[part 5 of 10: package /E40_Platform_System_SystemPackage/Components]
AUTOSAR XML (schema 4-2-1)
package /E40_Platform_System_SystemPackage/Components  (continued)
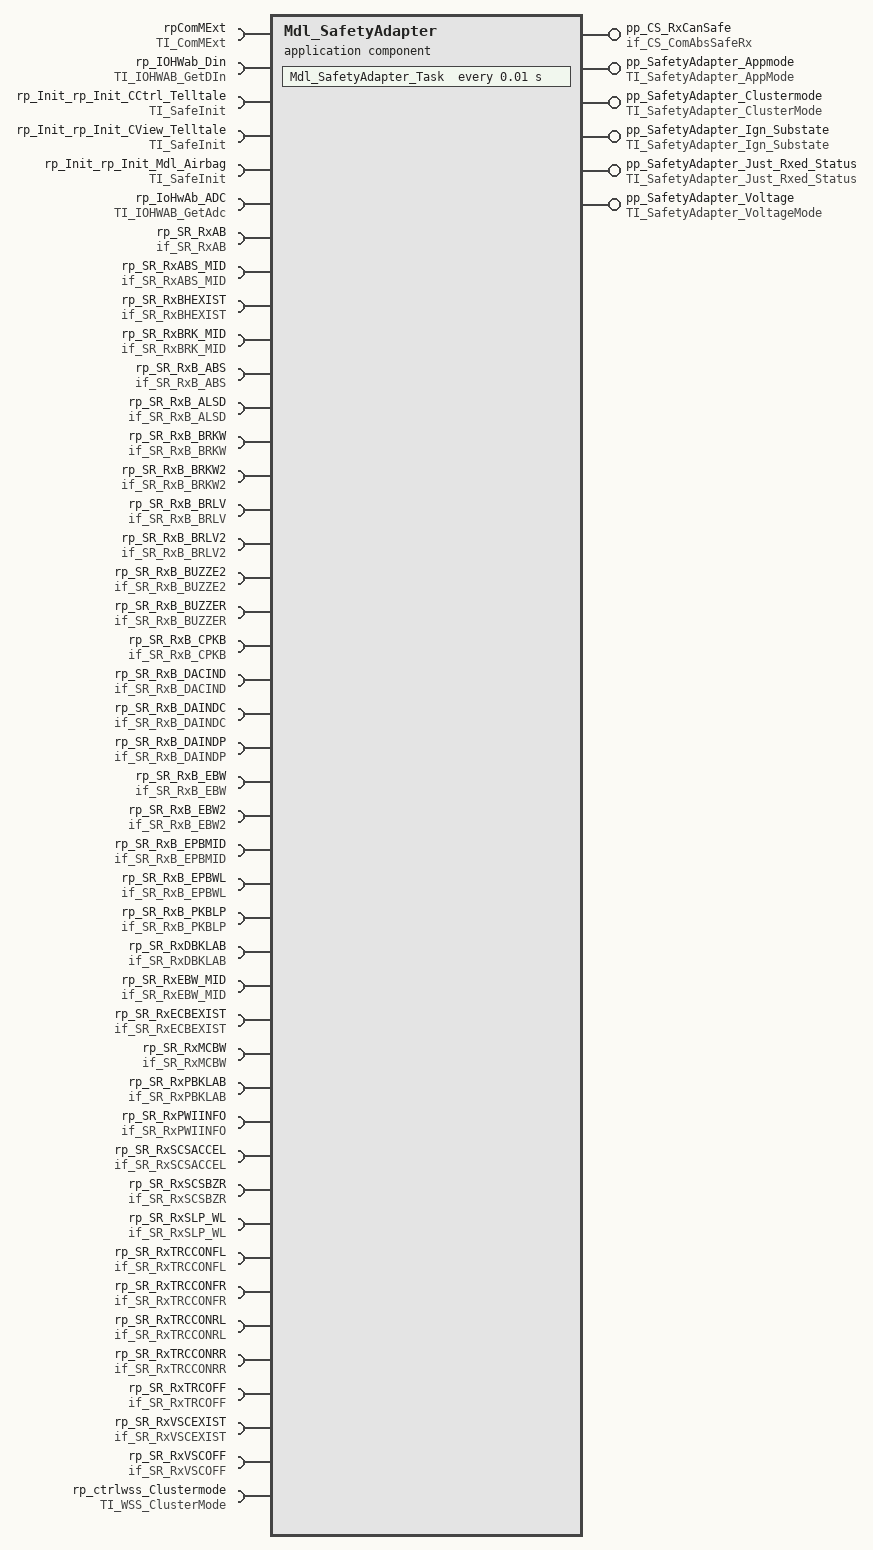
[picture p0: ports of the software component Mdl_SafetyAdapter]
  application sw component type Mdl_SafetyAdapter
    6 x provide port:
      pp_CS_RxCanSafe: provided-interface=if_CS_ComAbsSafeRx
        provided-com-specs:
          operation=Mdl_SafetyAdapter_ReloadMissingTimer, queue-length=1
          operation=RxCanVarInit, queue-length=1
          operation=RxCan_GetSafeSignalValue, queue-length=1
          operation=if_CS_ComAbsSafeRx/RxCan_SetSignalInitValue, queue-length=1
          operation=if_CS_ComAbsSafeRx/RxCan_SignalInvalidProcessingControl, queue-length=1
          operation=if_CS_ComAbsSafeRx/RxCan_SignalMissingProcessingControl, queue-length=1
          operation=if_CS_ComAbsSafeRx/RxCan_SignalNRProcessingControl, queue-length=1
      pp_SafetyAdapter_Appmode: nonqueued-sender-com-spec{data-element=SafetyAdapter_AppMode, init-value=constant-reference=Mdl_SafetyAdapterSafetyAdapter_AppModeValue0}, provided-interface=TI_SafetyAdapter_AppMode
      pp_SafetyAdapter_Clustermode: nonqueued-sender-com-spec{data-element=SafetyAdapter_CurrentClusterMode, init-value=constant-reference=Mdl_SafetyAdapterSafetyAdapter_CurrentClusterModeValue0}, provided-interface=TI_SafetyAdapter_ClusterMode
      pp_SafetyAdapter_Ign_Substate: nonqueued-sender-com-spec{data-element=SafetyAdapter_Ign_Substate, init-value=constant-reference=Mdl_SafetyAdapterSafetyAdapter_Ign_SubstateValue0}, provided-interface=TI_SafetyAdapter_Ign_Substate
      pp_SafetyAdapter_Just_Rxed_Status: provided-interface=TI_SafetyAdapter_Just_Rxed_Status
        provided-com-specs:
          operation=TI_SafetyAdapter_Just_Rxed_Status/RxCan_SignalClearJustRcvdStatus, queue-length=1
          operation=TI_SafetyAdapter_Just_Rxed_Status/RxCan_SignalGetJustRcvdStatus, queue-length=1
      pp_SafetyAdapter_Voltage: provided-interface=TI_SafetyAdapter_VoltageMode
        provided-com-specs:
          data-element=SafetyAdapter_HVSD1, init-value=constant-reference=Mdl_SafetyAdapterSafetyAdapter_HVSD1Value0
          data-element=SafetyAdapter_LVSD1, init-value=constant-reference=Mdl_SafetyAdapterSafetyAdapter_LVSD1Value0
    44 x require port:
      rpComMExt: required-interface=TI_ComMExt
      rp_IOHWab_Din: required-interface=TI_IOHWAB_GetDIn
      rp_Init_rp_Init_CCtrl_Telltale: required-interface=TI_SafeInit
      rp_Init_rp_Init_CView_Telltale: required-interface=TI_SafeInit
      rp_Init_rp_Init_Mdl_Airbag: required-interface=TI_SafeInit
      rp_IoHwAb_ADC: required-interface=TI_IOHWAB_GetAdc
      rp_SR_RxAB: nonqueued-receiver-com-spec{data-element=AB, init-value=constant-reference=Mdl_SafetyAdapterABValue0}, required-interface=if_SR_RxAB
      rp_SR_RxABS_MID: nonqueued-receiver-com-spec{data-element=ABS_MID, init-value=constant-reference=Mdl_SafetyAdapterABS_MIDValue0}, required-interface=if_SR_RxABS_MID
      rp_SR_RxBHEXIST: nonqueued-receiver-com-spec{data-element=BHEXIST, init-value=constant-reference=Mdl_SafetyAdapterBHEXISTValue0}, required-interface=if_SR_RxBHEXIST
      rp_SR_RxBRK_MID: nonqueued-receiver-com-spec{data-element=BRK_MID, init-value=constant-reference=Mdl_SafetyAdapterBRK_MIDValue0}, required-interface=if_SR_RxBRK_MID
      rp_SR_RxB_ABS: nonqueued-receiver-com-spec{data-element=B_ABS, init-value=constant-reference=Mdl_SafetyAdapterB_ABSValue0}, required-interface=if_SR_RxB_ABS
      rp_SR_RxB_ALSD: nonqueued-receiver-com-spec{data-element=B_ALSD, init-value=constant-reference=Mdl_SafetyAdapterB_ALSDValue0}, required-interface=if_SR_RxB_ALSD
      rp_SR_RxB_BRKW: nonqueued-receiver-com-spec{data-element=B_BRKW, init-value=constant-reference=Mdl_SafetyAdapterB_BRKWValue0}, required-interface=if_SR_RxB_BRKW
      rp_SR_RxB_BRKW2: nonqueued-receiver-com-spec{data-element=B_BRKW2, init-value=constant-reference=Mdl_SafetyAdapterB_BRKW2Value0}, required-interface=if_SR_RxB_BRKW2
      rp_SR_RxB_BRLV: nonqueued-receiver-com-spec{data-element=B_BRLV, init-value=constant-reference=Mdl_SafetyAdapterB_BRLVValue0}, required-interface=if_SR_RxB_BRLV
      rp_SR_RxB_BRLV2: nonqueued-receiver-com-spec{data-element=B_BRLV2, init-value=constant-reference=Mdl_SafetyAdapterB_BRLV2Value0}, required-interface=if_SR_RxB_BRLV2
      rp_SR_RxB_BUZZE2: nonqueued-receiver-com-spec{data-element=B_BUZZE2, init-value=constant-reference=Mdl_SafetyAdapterB_BUZZE2Value0}, required-interface=if_SR_RxB_BUZZE2
      rp_SR_RxB_BUZZER: nonqueued-receiver-com-spec{data-element=B_BUZZER, init-value=constant-reference=Mdl_SafetyAdapterB_BUZZERValue0}, required-interface=if_SR_RxB_BUZZER
      rp_SR_RxB_CPKB: nonqueued-receiver-com-spec{data-element=B_CPKB, init-value=constant-reference=Mdl_SafetyAdapterB_CPKBValue0}, required-interface=if_SR_RxB_CPKB
      rp_SR_RxB_DACIND: nonqueued-receiver-com-spec{data-element=B_DACIND, init-value=constant-reference=Mdl_SafetyAdapterB_DACINDValue0}, required-interface=if_SR_RxB_DACIND
      rp_SR_RxB_DAINDC: nonqueued-receiver-com-spec{data-element=B_DAINDC, init-value=constant-reference=Mdl_SafetyAdapterB_DAINDCValue0}, required-interface=if_SR_RxB_DAINDC
      rp_SR_RxB_DAINDP: nonqueued-receiver-com-spec{data-element=B_DAINDP, init-value=constant-reference=Mdl_SafetyAdapterB_DAINDPValue0}, required-interface=if_SR_RxB_DAINDP
      rp_SR_RxB_EBW: nonqueued-receiver-com-spec{data-element=B_EBW, init-value=constant-reference=Mdl_SafetyAdapterB_EBWValue0}, required-interface=if_SR_RxB_EBW
      rp_SR_RxB_EBW2: nonqueued-receiver-com-spec{data-element=B_EBW2, init-value=constant-reference=Mdl_SafetyAdapterB_EBW2Value0}, required-interface=if_SR_RxB_EBW2
      rp_SR_RxB_EPBMID: nonqueued-receiver-com-spec{data-element=B_EPBMID, init-value=constant-reference=Mdl_SafetyAdapterB_EPBMIDValue0}, required-interface=if_SR_RxB_EPBMID
      rp_SR_RxB_EPBWL: nonqueued-receiver-com-spec{data-element=B_EPBWL, init-value=constant-reference=Mdl_SafetyAdapterB_EPBWLValue0}, required-interface=if_SR_RxB_EPBWL
      rp_SR_RxB_PKBLP: nonqueued-receiver-com-spec{data-element=B_PKBLP, init-value=constant-reference=Mdl_SafetyAdapterB_PKBLPValue0}, required-interface=if_SR_RxB_PKBLP
      rp_SR_RxDBKLAB: nonqueued-receiver-com-spec{data-element=DBKLAB, init-value=constant-reference=Mdl_SafetyAdapterDBKLABValue0}, required-interface=if_SR_RxDBKLAB
      rp_SR_RxEBW_MID: nonqueued-receiver-com-spec{data-element=EBW_MID, init-value=constant-reference=Mdl_SafetyAdapterEBW_MIDValue0}, required-interface=if_SR_RxEBW_MID
      rp_SR_RxECBEXIST: nonqueued-receiver-com-spec{data-element=ECBEXIST, init-value=constant-reference=Mdl_SafetyAdapterECBEXISTValue0}, required-interface=if_SR_RxECBEXIST
      rp_SR_RxMCBW: nonqueued-receiver-com-spec{data-element=MCBW, init-value=constant-reference=Mdl_SafetyAdapterMCBWValue0}, required-interface=if_SR_RxMCBW
      rp_SR_RxPBKLAB: nonqueued-receiver-com-spec{data-element=PBKLAB, init-value=constant-reference=Mdl_SafetyAdapterPBKLABValue0}, required-interface=if_SR_RxPBKLAB
      rp_SR_RxPWIINFO: nonqueued-receiver-com-spec{data-element=PWIINFO, init-value=constant-reference=Mdl_SafetyAdapterPWIINFOValue0}, required-interface=if_SR_RxPWIINFO
      rp_SR_RxSCSACCEL: nonqueued-receiver-com-spec{data-element=SCSACCEL, init-value=constant-reference=Mdl_SafetyAdapterSCSACCELValue0}, required-interface=if_SR_RxSCSACCEL
      rp_SR_RxSCSBZR: nonqueued-receiver-com-spec{data-element=SCSBZR, init-value=constant-reference=Mdl_SafetyAdapterSCSBZRValue0}, required-interface=if_SR_RxSCSBZR
      rp_SR_RxSLP_WL: nonqueued-receiver-com-spec{data-element=SLP_WL, init-value=constant-reference=Mdl_SafetyAdapterSLP_WLValue0}, required-interface=if_SR_RxSLP_WL
      rp_SR_RxTRCCONFL: nonqueued-receiver-com-spec{data-element=TRCCONFL, init-value=constant-reference=Mdl_SafetyAdapterTRCCONFLValue0}, required-interface=if_SR_RxTRCCONFL
      rp_SR_RxTRCCONFR: nonqueued-receiver-com-spec{data-element=TRCCONFR, init-value=constant-reference=Mdl_SafetyAdapterTRCCONFRValue0}, required-interface=if_SR_RxTRCCONFR
      rp_SR_RxTRCCONRL: nonqueued-receiver-com-spec{data-element=TRCCONRL, init-value=constant-reference=Mdl_SafetyAdapterTRCCONRLValue0}, required-interface=if_SR_RxTRCCONRL
      rp_SR_RxTRCCONRR: nonqueued-receiver-com-spec{data-element=TRCCONRR, init-value=constant-reference=Mdl_SafetyAdapterTRCCONRRValue0}, required-interface=if_SR_RxTRCCONRR
      rp_SR_RxTRCOFF: nonqueued-receiver-com-spec{data-element=TRCOFF, init-value=constant-reference=Mdl_SafetyAdapterTRCOFFValue0}, required-interface=if_SR_RxTRCOFF
      rp_SR_RxVSCEXIST: nonqueued-receiver-com-spec{data-element=VSCEXIST, init-value=constant-reference=Mdl_SafetyAdapterVSCEXISTValue0}, required-interface=if_SR_RxVSCEXIST
      rp_SR_RxVSCOFF: nonqueued-receiver-com-spec{data-element=VSCOFF, init-value=constant-reference=Mdl_SafetyAdapterVSCOFFValue0}, required-interface=if_SR_RxVSCOFF
      rp_ctrlwss_Clustermode: nonqueued-receiver-com-spec{data-element=WSSCurrentClusterMode, init-value=constant-reference=Mdl_SafetyAdapterWSSCurrentClusterModeValue0}, required-interface=TI_WSS_ClusterMode
    behavior IB_Mdl_SafetyAdapter
      operation invoked event OIE_pp_CS_RxCanSafe_Mdl_SafetyAdapter_Mdl_SafetyAdapter_ReloadMissingTimerTrigByMdl_SafetyAdapter_ReloadMissingTimer: start-on-event=Mdl_SafetyAdapter_Mdl_SafetyAdapter_ReloadMissingTimer, operation=pp_CS_RxCanSafe.Mdl_SafetyAdapter_ReloadMissingTimer
      4 x data received event:
        DREMdl_SafetyAdapter_OnDataRx_B_EBW2TrigByB_EBW2: start-on-event=Mdl_SafetyAdapter_OnDataRx_B_EBW2, data=rp_SR_RxB_EBW2.B_EBW2
        DREMdl_SafetyAdapter_OnDataRx_B_PKBLPTrigByB_PKBLP: start-on-event=Mdl_SafetyAdapter_OnDataRx_B_PKBLP, data=rp_SR_RxB_PKBLP.B_PKBLP
        DREMdl_SafetyAdapter_OnDataRx_SCSBZRTrigBySCSBZR: start-on-event=Mdl_SafetyAdapter_OnDataRx_SCSBZR, data=rp_SR_RxSCSBZR.SCSBZR
        DREMdl_SafetyAdapter_OnDataRx_VSCOFFTrigByVSCOFF: start-on-event=Mdl_SafetyAdapter_OnDataRx_VSCOFF, data=rp_SR_RxVSCOFF.VSCOFF
      8 x operation invoked event:
        OIE_pp_CS_RxCanSafe_Mdl_SafetyAdapter_RxCanVarInitTrigByRxCanVarInit: start-on-event=Mdl_SafetyAdapter_RxCanVarInit, operation=pp_CS_RxCanSafe.RxCanVarInit
        OIE_pp_CS_RxCanSafe_Mdl_SafetyAdapter_RxCan_GetSafeSignalValueTrigByRxCan_GetSafeSignalValue: start-on-event=Mdl_SafetyAdapter_RxCan_GetSafeSignalValue, operation=pp_CS_RxCanSafe.RxCan_GetSafeSignalValue
        OIE_pp_CS_RxCanSafe_Mdl_SafetyAdapter_RxCan_SetSignalInitValueTrigByRxCan_SetSignalInitValue: start-on-event=Mdl_SafetyAdapter_RxCan_SetSignalInitValue, operation=pp_CS_RxCanSafe.RxCan_SetSignalInitValue
        OIE_pp_SafetyAdapter_Just_Rxed_Status_Mdl_SafetyAdapter_RxCan_SignalClearJustRcvdStatusTrigByRxCan_SignalClearJustRcvdStatus: start-on-event=Mdl_SafetyAdapter_RxCan_SignalClearJustRcvdStatus, operation=pp_SafetyAdapter_Just_Rxed_Status.RxCan_SignalClearJustRcvdStatus
        OIE_pp_SafetyAdapter_Just_Rxed_Status_Mdl_SafetyAdapter_RxCan_SignalGetJustRcvdStatusTrigByRxCan_SignalGetJustRcvdStatus: start-on-event=Mdl_SafetyAdapter_RxCan_SignalGetJustRcvdStatus, operation=pp_SafetyAdapter_Just_Rxed_Status.RxCan_SignalGetJustRcvdStatus
        OIE_pp_CS_RxCanSafe_Mdl_SafetyAdapter_RxCan_SignalInvalidProcessingControlTrigByRxCan_SignalInvalidProcessingControl: start-on-event=Mdl_SafetyAdapter_RxCan_SignalInvalidProcessingControl, operation=pp_CS_RxCanSafe.RxCan_SignalInvalidProcessingControl
        OIE_pp_CS_RxCanSafe_Mdl_SafetyAdapter_RxCan_SignalMissingProcessingControlTrigByRxCan_SignalMissingProcessingControl: start-on-event=Mdl_SafetyAdapter_RxCan_SignalMissingProcessingControl, operation=pp_CS_RxCanSafe.RxCan_SignalMissingProcessingControl
        OIE_pp_CS_RxCanSafe_Mdl_SafetyAdapter_RxCan_SignalNRProcessingControlTrigByRxCan_SignalNRProcessingControl: start-on-event=Mdl_SafetyAdapter_RxCan_SignalNRProcessingControl, operation=pp_CS_RxCanSafe.RxCan_SignalNRProcessingControl
      timing event TEMdl_SafetyAdapter_Task: start-on-event=Mdl_SafetyAdapter_Task, period=0.01
      port-api-options:
        enable-take-address=false, indirect-api=false, port=pp_CS_RxCanSafe
        enable-take-address=false, indirect-api=false, port=pp_SafetyAdapter_Appmode
        enable-take-address=false, indirect-api=false, port=pp_SafetyAdapter_Clustermode
        enable-take-address=false, indirect-api=false, port=pp_SafetyAdapter_Ign_Substate
        enable-take-address=false, indirect-api=false, port=pp_SafetyAdapter_Just_Rxed_Status
        enable-take-address=false, indirect-api=false, port=pp_SafetyAdapter_Voltage
        enable-take-address=false, indirect-api=false, port=Mdl_SafetyAdapter/rpComMExt
        enable-take-address=false, indirect-api=false, port=rp_IOHWab_Din
        enable-take-address=false, indirect-api=false, port=rp_Init_rp_Init_CCtrl_Telltale
        enable-take-address=false, indirect-api=false, port=rp_Init_rp_Init_CView_Telltale
        enable-take-address=false, indirect-api=false, port=rp_Init_rp_Init_Mdl_Airbag
        enable-take-address=false, indirect-api=false, port=Mdl_SafetyAdapter/rp_IoHwAb_ADC
        enable-take-address=false, indirect-api=false, port=rp_SR_RxAB
        enable-take-address=false, indirect-api=false, port=rp_SR_RxABS_MID
        enable-take-address=false, indirect-api=false, port=rp_SR_RxBHEXIST
        enable-take-address=false, indirect-api=false, port=rp_SR_RxBRK_MID
        enable-take-address=false, indirect-api=false, port=rp_SR_RxB_ABS
        enable-take-address=false, indirect-api=false, port=rp_SR_RxB_ALSD
        enable-take-address=false, indirect-api=false, port=rp_SR_RxB_BRKW
        enable-take-address=false, indirect-api=false, port=rp_SR_RxB_BRKW2
        enable-take-address=false, indirect-api=false, port=rp_SR_RxB_BRLV
        enable-take-address=false, indirect-api=false, port=rp_SR_RxB_BRLV2
        enable-take-address=false, indirect-api=false, port=rp_SR_RxB_BUZZE2
        enable-take-address=false, indirect-api=false, port=rp_SR_RxB_BUZZER
        enable-take-address=false, indirect-api=false, port=rp_SR_RxB_CPKB
        enable-take-address=false, indirect-api=false, port=rp_SR_RxB_DACIND
        enable-take-address=false, indirect-api=false, port=rp_SR_RxB_DAINDC
        enable-take-address=false, indirect-api=false, port=rp_SR_RxB_DAINDP
        enable-take-address=false, indirect-api=false, port=rp_SR_RxB_EBW
        enable-take-address=false, indirect-api=false, port=rp_SR_RxB_EBW2
        enable-take-address=false, indirect-api=false, port=rp_SR_RxB_EPBMID
        enable-take-address=false, indirect-api=false, port=rp_SR_RxB_EPBWL
        enable-take-address=false, indirect-api=false, port=rp_SR_RxB_PKBLP
        enable-take-address=false, indirect-api=false, port=rp_SR_RxDBKLAB
        enable-take-address=false, indirect-api=false, port=rp_SR_RxEBW_MID
        enable-take-address=false, indirect-api=false, port=rp_SR_RxECBEXIST
        enable-take-address=false, indirect-api=false, port=rp_SR_RxMCBW
        enable-take-address=false, indirect-api=false, port=rp_SR_RxPBKLAB
        enable-take-address=false, indirect-api=false, port=rp_SR_RxPWIINFO
        enable-take-address=false, indirect-api=false, port=rp_SR_RxSCSACCEL
        enable-take-address=false, indirect-api=false, port=rp_SR_RxSCSBZR
        enable-take-address=false, indirect-api=false, port=rp_SR_RxSLP_WL
        enable-take-address=false, indirect-api=false, port=rp_SR_RxTRCCONFL
        enable-take-address=false, indirect-api=false, port=rp_SR_RxTRCCONFR
        enable-take-address=false, indirect-api=false, port=rp_SR_RxTRCCONRL
        enable-take-address=false, indirect-api=false, port=rp_SR_RxTRCCONRR
        enable-take-address=false, indirect-api=false, port=rp_SR_RxTRCOFF
        enable-take-address=false, indirect-api=false, port=rp_SR_RxVSCEXIST
        enable-take-address=false, indirect-api=false, port=rp_SR_RxVSCOFF
        enable-take-address=false, indirect-api=false, port=rp_ctrlwss_Clustermode
      14 x runnable, all with can-be-invoked-concurrently=true:
        Mdl_SafetyAdapter_Mdl_SafetyAdapter_ReloadMissingTimer
        Mdl_SafetyAdapter_OnDataRx_B_EBW2
        Mdl_SafetyAdapter_OnDataRx_B_PKBLP
        Mdl_SafetyAdapter_OnDataRx_SCSBZR
        Mdl_SafetyAdapter_OnDataRx_VSCOFF
        Mdl_SafetyAdapter_RxCanVarInit
        Mdl_SafetyAdapter_RxCan_GetSafeSignalValue
        Mdl_SafetyAdapter_RxCan_SetSignalInitValue
        Mdl_SafetyAdapter_RxCan_SignalClearJustRcvdStatus
        Mdl_SafetyAdapter_RxCan_SignalGetJustRcvdStatus
        Mdl_SafetyAdapter_RxCan_SignalInvalidProcessingControl
        Mdl_SafetyAdapter_RxCan_SignalMissingProcessingControl
        Mdl_SafetyAdapter_RxCan_SignalNRProcessingControl
        Mdl_SafetyAdapter_Task
          data-receive-point-by-arguments:
            38 x access:
              DRA_rp_SR_RxAB_AB: accessed-variable=rp_SR_RxAB.AB
              DRA_rp_SR_RxABS_MID_ABS_MID: accessed-variable=rp_SR_RxABS_MID.ABS_MID
              DRA_rp_SR_RxBHEXIST_BHEXIST: accessed-variable=rp_SR_RxBHEXIST.BHEXIST
              DRA_rp_SR_RxBRK_MID_BRK_MID: accessed-variable=rp_SR_RxBRK_MID.BRK_MID
              DRA_rp_SR_RxB_ABS_B_ABS: accessed-variable=rp_SR_RxB_ABS.B_ABS
              DRA_rp_SR_RxB_ALSD_B_ALSD: accessed-variable=rp_SR_RxB_ALSD.B_ALSD
              DRA_rp_SR_RxB_BRKW_B_BRKW: accessed-variable=rp_SR_RxB_BRKW.B_BRKW
              DRA_rp_SR_RxB_BRKW2_B_BRKW2: accessed-variable=rp_SR_RxB_BRKW2.B_BRKW2
              DRA_rp_SR_RxB_BRLV_B_BRLV: accessed-variable=rp_SR_RxB_BRLV.B_BRLV
              DRA_rp_SR_RxB_BRLV2_B_BRLV2: accessed-variable=rp_SR_RxB_BRLV2.B_BRLV2
              DRA_rp_SR_RxB_BUZZE2_B_BUZZE2: accessed-variable=rp_SR_RxB_BUZZE2.B_BUZZE2
              DRA_rp_SR_RxB_BUZZER_B_BUZZER: accessed-variable=rp_SR_RxB_BUZZER.B_BUZZER
              DRA_rp_SR_RxB_CPKB_B_CPKB: accessed-variable=rp_SR_RxB_CPKB.B_CPKB
              DRA_rp_SR_RxB_DACIND_B_DACIND: accessed-variable=rp_SR_RxB_DACIND.B_DACIND
              DRA_rp_SR_RxB_DAINDC_B_DAINDC: accessed-variable=rp_SR_RxB_DAINDC.B_DAINDC
              DRA_rp_SR_RxB_DAINDP_B_DAINDP: accessed-variable=rp_SR_RxB_DAINDP.B_DAINDP
              DRA_rp_SR_RxB_EBW_B_EBW: accessed-variable=rp_SR_RxB_EBW.B_EBW
              DRA_rp_SR_RxB_EBW2_B_EBW2: accessed-variable=rp_SR_RxB_EBW2.B_EBW2
              DRA_rp_SR_RxB_EPBMID_B_EPBMID: accessed-variable=rp_SR_RxB_EPBMID.B_EPBMID
              DRA_rp_SR_RxB_EPBWL_B_EPBWL: accessed-variable=rp_SR_RxB_EPBWL.B_EPBWL
              DRA_rp_SR_RxB_PKBLP_B_PKBLP: accessed-variable=rp_SR_RxB_PKBLP.B_PKBLP
              DRA_rp_SR_RxDBKLAB_DBKLAB: accessed-variable=rp_SR_RxDBKLAB.DBKLAB
              DRA_rp_SR_RxEBW_MID_EBW_MID: accessed-variable=rp_SR_RxEBW_MID.EBW_MID
              DRA_rp_SR_RxECBEXIST_ECBEXIST: accessed-variable=rp_SR_RxECBEXIST.ECBEXIST
              DRA_rp_SR_RxMCBW_MCBW: accessed-variable=rp_SR_RxMCBW.MCBW
              DRA_rp_SR_RxPBKLAB_PBKLAB: accessed-variable=rp_SR_RxPBKLAB.PBKLAB
              DRA_rp_SR_RxPWIINFO_PWIINFO: accessed-variable=rp_SR_RxPWIINFO.PWIINFO
              DRA_rp_SR_RxSCSACCEL_SCSACCEL: accessed-variable=rp_SR_RxSCSACCEL.SCSACCEL
              DRA_rp_SR_RxSCSBZR_SCSBZR: accessed-variable=rp_SR_RxSCSBZR.SCSBZR
              DRA_rp_SR_RxSLP_WL_SLP_WL: accessed-variable=rp_SR_RxSLP_WL.SLP_WL
              DRA_rp_SR_RxTRCCONFL_TRCCONFL: accessed-variable=rp_SR_RxTRCCONFL.TRCCONFL
              DRA_rp_SR_RxTRCCONFR_TRCCONFR: accessed-variable=rp_SR_RxTRCCONFR.TRCCONFR
              DRA_rp_SR_RxTRCCONRL_TRCCONRL: accessed-variable=rp_SR_RxTRCCONRL.TRCCONRL
              DRA_rp_SR_RxTRCCONRR_TRCCONRR: accessed-variable=rp_SR_RxTRCCONRR.TRCCONRR
              DRA_rp_SR_RxTRCOFF_TRCOFF: accessed-variable=rp_SR_RxTRCOFF.TRCOFF
              DRA_rp_SR_RxVSCEXIST_VSCEXIST: accessed-variable=rp_SR_RxVSCEXIST.VSCEXIST
              DRA_rp_SR_RxVSCOFF_VSCOFF: accessed-variable=rp_SR_RxVSCOFF.VSCOFF
              DRA_rp_ctrlwss_Clustermode_WSSCurrentClusterMode: accessed-variable=rp_ctrlwss_Clustermode.WSSCurrentClusterMode
          data-send-points:
            5 x access:
              DWA_pp_SafetyAdapter_Appmode_SafetyAdapter_AppMode: accessed-variable=pp_SafetyAdapter_Appmode.SafetyAdapter_AppMode
              DWA_pp_SafetyAdapter_Clustermode_SafetyAdapter_CurrentClusterMode: accessed-variable=pp_SafetyAdapter_Clustermode.SafetyAdapter_CurrentClusterMode
              DWA_pp_SafetyAdapter_Ign_Substate_SafetyAdapter_Ign_Substate: accessed-variable=pp_SafetyAdapter_Ign_Substate.SafetyAdapter_Ign_Substate
              DWA_pp_SafetyAdapter_Voltage_SafetyAdapter_HVSD1: accessed-variable=pp_SafetyAdapter_Voltage.SafetyAdapter_HVSD1
              DWA_pp_SafetyAdapter_Voltage_SafetyAdapter_LVSD1: accessed-variable=pp_SafetyAdapter_Voltage.SafetyAdapter_LVSD1
          24 x sync call, all with timeout=0.0:
            OA_rpComMExt_Get_MCAN_ERR_PIN_Status: operation=rpComMExt.Get_MCAN_ERR_PIN_Status
            OA_rpComMExt_Impl_MainFunction: operation=rpComMExt.Impl_MainFunction
            OA_rpComMExt_Init: operation=rpComMExt.Init
            OA_rpComMExt_GetBusOffStatus: operation=rpComMExt.GetBusOffStatus
            OA_rpComMExt_CAN_RequestCommunication: operation=rpComMExt.CAN_RequestCommunication
            OA_rpComMExt_CAN_GetCurrentComMode: operation=rpComMExt.CAN_GetCurrentComMode
            OA_rpComMExt_CAN_ReleaseCommunication: operation=rpComMExt.CAN_ReleaseCommunication
            OA_rpComMExt_CAN_DeActivateSilentCommunication: operation=rpComMExt.CAN_DeActivateSilentCommunication
            OA_rpComMExt_CAN_CommControlSetDone: operation=rpComMExt.CAN_CommControlSetDone
            OA_rpComMExt_CAN_CommControlDeActivateTx: operation=rpComMExt.CAN_CommControlDeActivateTx
            OA_rpComMExt_CAN_CommControlDeActivateRx: operation=rpComMExt.CAN_CommControlDeActivateRx
            OA_rpComMExt_CAN_ActivateSilentCommunication: operation=rpComMExt.CAN_ActivateSilentCommunication
            OA_rpComMExt_CAN_CommControlActivateRx: operation=rpComMExt.CAN_CommControlActivateRx
            OA_rpComMExt_CAN_CommControlActivateTx: operation=rpComMExt.CAN_CommControlActivateTx
            OA_rp_IOHWab_Din_GetAsyncRawInput: operation=rp_IOHWab_Din.GetAsyncRawInput
            OA_rp_IOHWab_Din_GetProcessedInput: operation=rp_IOHWab_Din.GetProcessedInput
            OA_rp_IOHWab_Din_GetSyncRawInput: operation=rp_IOHWab_Din.GetSyncRawInput
            OA_rp_IOHWab_Din_GetInputGroup: operation=rp_IOHWab_Din.GetInputGroup
            OA_rp_Init_rp_Init_CCtrl_Telltale_Init: operation=rp_Init_rp_Init_CCtrl_Telltale.Init
            OA_rp_Init_rp_Init_CView_Telltale_Init: operation=rp_Init_rp_Init_CView_Telltale.Init
            OA_rp_Init_rp_Init_Mdl_Airbag_Init: operation=rp_Init_rp_Init_Mdl_Airbag.Init
            OA_rp_IoHwAb_ADC_GetAsyncRawAdc: operation=rp_IoHwAb_ADC.GetAsyncRawAdc
            OA_rp_IoHwAb_ADC_GetSyncRawAdc: operation=rp_IoHwAb_ADC.GetSyncRawAdc
            OA_rp_IoHwAb_ADC_GetProcessedAdc: operation=rp_IoHwAb_ADC.GetProcessedAdc
  43 x constant specification:
    Mdl_SafetyAdapterSafetyAdapter_AppModeValue0: value-spec=Mdl_SafetyAdapterSafetyAdapter_AppModeValue0:0
    Mdl_SafetyAdapterSafetyAdapter_CurrentClusterModeValue0: value-spec=Mdl_SafetyAdapterSafetyAdapter_CurrentClusterModeValue0:0
    Mdl_SafetyAdapterSafetyAdapter_Ign_SubstateValue0: value-spec=Mdl_SafetyAdapterSafetyAdapter_Ign_SubstateValue0:0
    Mdl_SafetyAdapterSafetyAdapter_HVSD1Value0: value-spec=Mdl_SafetyAdapterSafetyAdapter_HVSD1Value0:0
    Mdl_SafetyAdapterSafetyAdapter_LVSD1Value0: value-spec=Mdl_SafetyAdapterSafetyAdapter_LVSD1Value0:0
    Mdl_SafetyAdapterABValue0: value-spec=Mdl_SafetyAdapterABValue0:0
    Mdl_SafetyAdapterABS_MIDValue0: value-spec=Mdl_SafetyAdapterABS_MIDValue0:0
    Mdl_SafetyAdapterBHEXISTValue0: value-spec=Mdl_SafetyAdapterBHEXISTValue0:0
    Mdl_SafetyAdapterBRK_MIDValue0: value-spec=Mdl_SafetyAdapterBRK_MIDValue0:0
    Mdl_SafetyAdapterB_ABSValue0: value-spec=Mdl_SafetyAdapterB_ABSValue0:0
    Mdl_SafetyAdapterB_ALSDValue0: value-spec=Mdl_SafetyAdapterB_ALSDValue0:0
    Mdl_SafetyAdapterB_BRKWValue0: value-spec=Mdl_SafetyAdapterB_BRKWValue0:0
    Mdl_SafetyAdapterB_BRKW2Value0: value-spec=Mdl_SafetyAdapterB_BRKW2Value0:0
    Mdl_SafetyAdapterB_BRLVValue0: value-spec=Mdl_SafetyAdapterB_BRLVValue0:0
    Mdl_SafetyAdapterB_BRLV2Value0: value-spec=Mdl_SafetyAdapterB_BRLV2Value0:0
    Mdl_SafetyAdapterB_BUZZE2Value0: value-spec=Mdl_SafetyAdapterB_BUZZE2Value0:0
    Mdl_SafetyAdapterB_BUZZERValue0: value-spec=Mdl_SafetyAdapterB_BUZZERValue0:0
    Mdl_SafetyAdapterB_CPKBValue0: value-spec=Mdl_SafetyAdapterB_CPKBValue0:0
    Mdl_SafetyAdapterB_DACINDValue0: value-spec=Mdl_SafetyAdapterB_DACINDValue0:0
    Mdl_SafetyAdapterB_DAINDCValue0: value-spec=Mdl_SafetyAdapterB_DAINDCValue0:0
    Mdl_SafetyAdapterB_DAINDPValue0: value-spec=Mdl_SafetyAdapterB_DAINDPValue0:0
    Mdl_SafetyAdapterB_EBWValue0: value-spec=Mdl_SafetyAdapterB_EBWValue0:0
    Mdl_SafetyAdapterB_EBW2Value0: value-spec=Mdl_SafetyAdapterB_EBW2Value0:0
    Mdl_SafetyAdapterB_EPBMIDValue0: value-spec=Mdl_SafetyAdapterB_EPBMIDValue0:0
    Mdl_SafetyAdapterB_EPBWLValue0: value-spec=Mdl_SafetyAdapterB_EPBWLValue0:0
    Mdl_SafetyAdapterB_PKBLPValue0: value-spec=Mdl_SafetyAdapterB_PKBLPValue0:0
    Mdl_SafetyAdapterDBKLABValue0: value-spec=Mdl_SafetyAdapterDBKLABValue0:0
    Mdl_SafetyAdapterEBW_MIDValue0: value-spec=Mdl_SafetyAdapterEBW_MIDValue0:0
    Mdl_SafetyAdapterECBEXISTValue0: value-spec=Mdl_SafetyAdapterECBEXISTValue0:0
    Mdl_SafetyAdapterMCBWValue0: value-spec=Mdl_SafetyAdapterMCBWValue0:0
    Mdl_SafetyAdapterPBKLABValue0: value-spec=Mdl_SafetyAdapterPBKLABValue0:0
    Mdl_SafetyAdapterPWIINFOValue0: value-spec=Mdl_SafetyAdapterPWIINFOValue0:0
    Mdl_SafetyAdapterSCSACCELValue0: value-spec=Mdl_SafetyAdapterSCSACCELValue0:0
    Mdl_SafetyAdapterSCSBZRValue0: value-spec=Mdl_SafetyAdapterSCSBZRValue0:0
    Mdl_SafetyAdapterSLP_WLValue0: value-spec=Mdl_SafetyAdapterSLP_WLValue0:0
    Mdl_SafetyAdapterTRCCONFLValue0: value-spec=Mdl_SafetyAdapterTRCCONFLValue0:0
    Mdl_SafetyAdapterTRCCONFRValue0: value-spec=Mdl_SafetyAdapterTRCCONFRValue0:0
    Mdl_SafetyAdapterTRCCONRLValue0: value-spec=Mdl_SafetyAdapterTRCCONRLValue0:0
    Mdl_SafetyAdapterTRCCONRRValue0: value-spec=Mdl_SafetyAdapterTRCCONRRValue0:0
    Mdl_SafetyAdapterTRCOFFValue0: value-spec=Mdl_SafetyAdapterTRCOFFValue0:0
    Mdl_SafetyAdapterVSCEXISTValue0: value-spec=Mdl_SafetyAdapterVSCEXISTValue0:0
    Mdl_SafetyAdapterVSCOFFValue0: value-spec=Mdl_SafetyAdapterVSCOFFValue0:0
    Mdl_SafetyAdapterWSSCurrentClusterModeValue0: value-spec=Mdl_SafetyAdapterWSSCurrentClusterModeValue0:0
  swc implementation IMPL_Mdl_SafetyAdapter: programming-language=C, behavior=IB_Mdl_SafetyAdapter
    code-descriptors:
      code CodeDescriptor
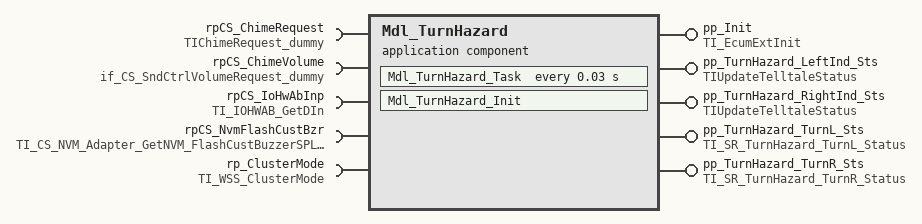
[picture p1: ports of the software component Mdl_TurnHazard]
  application sw component type Mdl_TurnHazard
    5 x provide port:
      pp_Init: server-com-spec{operation=TI_EcumExtInit/Init, queue-length=1}, provided-interface=TI_EcumExtInit
      pp_TurnHazard_LeftInd_Sts: nonqueued-sender-com-spec{data-element=CurrentTelltaleStatus, init-value=constant-reference=Mdl_TurnHazardCurrentTelltaleStatusValue0}, provided-interface=TIUpdateTelltaleStatus
      pp_TurnHazard_RightInd_Sts: nonqueued-sender-com-spec{data-element=CurrentTelltaleStatus, init-value=constant-reference=Mdl_TurnHazardCurrentTelltaleStatusValue0}, provided-interface=TIUpdateTelltaleStatus
      pp_TurnHazard_TurnL_Sts: nonqueued-sender-com-spec{data-element=LeftIndicatorSts, init-value=constant-reference=Mdl_TurnHazardLeftIndicatorStsValue0}, provided-interface=TI_SR_TurnHazard_TurnL_Status
      pp_TurnHazard_TurnR_Sts: nonqueued-sender-com-spec{data-element=RightIndicatorSts, init-value=constant-reference=Mdl_TurnHazardRightIndicatorStsValue0}, provided-interface=TI_SR_TurnHazard_TurnR_Status
    5 x require port:
      rpCS_ChimeRequest: nonqueued-receiver-com-spec{data-element=Chime_Request, init-value=constant-reference=Mdl_TurnHazardChime_RequestValue0}, required-interface=TIChimeRequest_dummy
      rpCS_ChimeVolume: nonqueued-receiver-com-spec{data-element=UpdateChimeVolume, init-value=constant-reference=Mdl_TurnHazardUpdateChimeVolumeValue0}, required-interface=if_CS_SndCtrlVolumeRequest_dummy
      rpCS_IoHwAbInp: required-interface=TI_IOHWAB_GetDIn
      rpCS_NvmFlashCustBzr: nonqueued-receiver-com-spec{data-element=Nvmdata, init-value=constant-reference=Mdl_TurnHazardNvmdataValue0}, required-interface=TI_CS_NVM_Adapter_GetNVM_FlashCustBuzzerSPL_Dummy
      rp_ClusterMode: nonqueued-receiver-com-spec{data-element=WSSCurrentClusterMode, init-value=constant-reference=Mdl_TurnHazardWSSCurrentClusterModeValue0}, required-interface=TI_WSS_ClusterMode
    behavior IB_Mdl_TurnHazard
      operation invoked event OIE_pp_Init_Mdl_TurnHazard_InitTrigByInit: start-on-event=Mdl_TurnHazard_Init, operation=pp_Init.Init
      timing event TEMdl_TurnHazard_Task: start-on-event=Mdl_TurnHazard_Task, period=0.03
      port-api-options:
        enable-take-address=false, indirect-api=false, port=Mdl_TurnHazard/pp_Init
        enable-take-address=false, indirect-api=false, port=pp_TurnHazard_LeftInd_Sts
        enable-take-address=false, indirect-api=false, port=pp_TurnHazard_RightInd_Sts
        enable-take-address=false, indirect-api=false, port=pp_TurnHazard_TurnL_Sts
        enable-take-address=false, indirect-api=false, port=pp_TurnHazard_TurnR_Sts
        enable-take-address=false, indirect-api=false, port=Mdl_TurnHazard/rpCS_ChimeRequest
        enable-take-address=false, indirect-api=false, port=rpCS_ChimeVolume
        enable-take-address=false, indirect-api=false, port=rpCS_IoHwAbInp
        enable-take-address=false, indirect-api=false, port=rpCS_NvmFlashCustBzr
        enable-take-address=false, indirect-api=false, port=Mdl_TurnHazard/rp_ClusterMode
      runnable Mdl_TurnHazard_Init: can-be-invoked-concurrently=true
      runnable Mdl_TurnHazard_Task: can-be-invoked-concurrently=true
        data-receive-point-by-arguments:
          4 x access:
            DRA_rpCS_ChimeRequest_Chime_Request: accessed-variable=rpCS_ChimeRequest.Chime_Request
            DRA_rpCS_ChimeVolume_UpdateChimeVolume: accessed-variable=rpCS_ChimeVolume.UpdateChimeVolume
            DRA_rpCS_NvmFlashCustBzr_Nvmdata: accessed-variable=rpCS_NvmFlashCustBzr.Nvmdata
            DRA_rp_ClusterMode_WSSCurrentClusterMode: accessed-variable=rp_ClusterMode.WSSCurrentClusterMode
        data-send-points:
          4 x access:
            DWA_pp_TurnHazard_LeftInd_Sts_CurrentTelltaleStatus: accessed-variable=pp_TurnHazard_LeftInd_Sts.CurrentTelltaleStatus
            DWA_pp_TurnHazard_RightInd_Sts_CurrentTelltaleStatus: accessed-variable=pp_TurnHazard_RightInd_Sts.CurrentTelltaleStatus
            DWA_pp_TurnHazard_TurnL_Sts_LeftIndicatorSts: accessed-variable=pp_TurnHazard_TurnL_Sts.LeftIndicatorSts
            DWA_pp_TurnHazard_TurnR_Sts_RightIndicatorSts: accessed-variable=pp_TurnHazard_TurnR_Sts.RightIndicatorSts
        4 x sync call, all with timeout=0.0:
          OA_rpCS_IoHwAbInp_GetAsyncRawInput: operation=rpCS_IoHwAbInp.GetAsyncRawInput
          OA_rpCS_IoHwAbInp_GetProcessedInput: operation=rpCS_IoHwAbInp.GetProcessedInput
          OA_rpCS_IoHwAbInp_GetSyncRawInput: operation=rpCS_IoHwAbInp.GetSyncRawInput
          OA_rpCS_IoHwAbInp_GetInputGroup: operation=rpCS_IoHwAbInp.GetInputGroup
  7 x constant specification:
    Mdl_TurnHazardCurrentTelltaleStatusValue0: value-spec=Mdl_TurnHazardCurrentTelltaleStatusValue0:0
    Mdl_TurnHazardLeftIndicatorStsValue0: value-spec=Mdl_TurnHazardLeftIndicatorStsValue0:0
    Mdl_TurnHazardRightIndicatorStsValue0: value-spec=Mdl_TurnHazardRightIndicatorStsValue0:0
    Mdl_TurnHazardChime_RequestValue0: value-spec=Mdl_TurnHazardChime_RequestValue0:0
    Mdl_TurnHazardUpdateChimeVolumeValue0: value-spec=Mdl_TurnHazardUpdateChimeVolumeValue0:0
    Mdl_TurnHazardNvmdataValue0: value-spec=Mdl_TurnHazardNvmdataValue0:0
    Mdl_TurnHazardWSSCurrentClusterModeValue0: value-spec=Mdl_TurnHazardWSSCurrentClusterModeValue0:0
  swc implementation IMPL_Mdl_TurnHazard: programming-language=C, behavior=IB_Mdl_TurnHazard
    code-descriptors:
      code CodeDescriptor
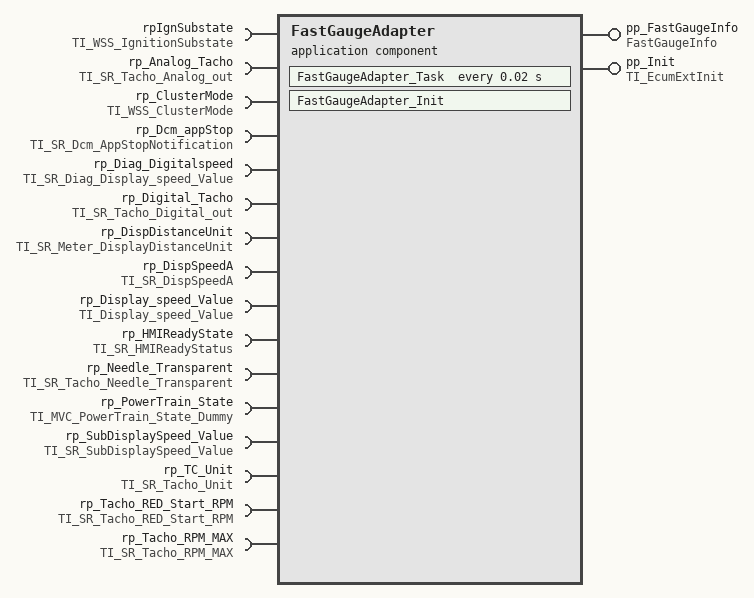
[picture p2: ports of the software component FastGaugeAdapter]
  application sw component type FastGaugeAdapter
    provide port pp_FastGaugeInfo: nonqueued-sender-com-spec{data-element=FastGaugeInfoData, init-value=constant-reference=FastGaugeAdapterFastGaugeInfoDataValue0}, provided-interface=FastGaugeInfo
    provide port pp_Init: server-com-spec{operation=TI_EcumExtInit/Init, queue-length=1}, provided-interface=TI_EcumExtInit
    16 x require port:
      rpIgnSubstate: nonqueued-receiver-com-spec{data-element=IgnitionSubstate, init-value=constant-reference=FastGaugeAdapterIgnitionSubstateValue0}, required-interface=TI_WSS_IgnitionSubstate
      rp_Analog_Tacho: nonqueued-receiver-com-spec{data-element=Analog_Tacho, init-value=constant-reference=FastGaugeAdapterAnalog_TachoValue0}, required-interface=TI_SR_Tacho_Analog_out
      rp_ClusterMode: nonqueued-receiver-com-spec{data-element=WSSCurrentClusterMode, init-value=constant-reference=FastGaugeAdapterWSSCurrentClusterModeValue0}, required-interface=TI_WSS_ClusterMode
      rp_Dcm_appStop: nonqueued-receiver-com-spec{data-element=AppId, init-value=constant-reference=FastGaugeAdapterAppIdValue0}, required-interface=TI_SR_Dcm_AppStopNotification
      rp_Diag_Digitalspeed: nonqueued-receiver-com-spec{data-element=Diag_Digital_Speed_Value, init-value=constant-reference=FastGaugeAdapterDiag_Digital_Speed_ValueValue0}, required-interface=TI_SR_Diag_Display_speed_Value
      rp_Digital_Tacho: nonqueued-receiver-com-spec{data-element=Digital_Tacho, init-value=constant-reference=FastGaugeAdapterDigital_TachoValue0}, required-interface=TI_SR_Tacho_Digital_out
      rp_DispDistanceUnit: nonqueued-receiver-com-spec{data-element=DisplayUnit, init-value=constant-reference=FastGaugeAdapterDisplayUnitValue0}, required-interface=TI_SR_Meter_DisplayDistanceUnit
      rp_DispSpeedA: nonqueued-receiver-com-spec{data-element=DispSpeedVal, init-value=constant-reference=FastGaugeAdapterDispSpeedValValue0}, required-interface=TI_SR_DispSpeedA
      rp_Display_speed_Value: nonqueued-receiver-com-spec{data-element=Digital_Speed_Value, init-value=constant-reference=FastGaugeAdapterDigital_Speed_ValueValue0}, required-interface=TI_Display_speed_Value
      rp_HMIReadyState: nonqueued-receiver-com-spec{data-element=HMI_ReadyStatus, init-value=constant-reference=FastGaugeAdapterHMI_ReadyStatusValue0}, required-interface=TI_SR_HMIReadyStatus
      rp_Needle_Transparent: nonqueued-receiver-com-spec{data-element=Needle_TR, init-value=constant-reference=FastGaugeAdapterNeedle_TRValue0}, required-interface=TI_SR_Tacho_Needle_Transparent
      rp_PowerTrain_State: nonqueued-receiver-com-spec{data-element=PowerTrain_Flag, init-value=constant-reference=FastGaugeAdapterPowerTrain_FlagValue0}, required-interface=TI_MVC_PowerTrain_State_Dummy
      rp_SubDisplaySpeed_Value: nonqueued-receiver-com-spec{data-element=SubDispSpeedVal, init-value=constant-reference=FastGaugeAdapterSubDispSpeedValValue0}, required-interface=TI_SR_SubDisplaySpeed_Value
      rp_TC_Unit: nonqueued-receiver-com-spec{data-element=Digital_TachoUnit, init-value=constant-reference=FastGaugeAdapterDigital_TachoUnitValue0}, required-interface=TI_SR_Tacho_Unit
      rp_Tacho_RED_Start_RPM: nonqueued-receiver-com-spec{data-element=RED_Start_RPM, init-value=constant-reference=FastGaugeAdapterRED_Start_RPMValue0}, required-interface=TI_SR_Tacho_RED_Start_RPM
      rp_Tacho_RPM_MAX: nonqueued-receiver-com-spec{data-element=REVP_RPM_MAX, init-value=constant-reference=FastGaugeAdapterREVP_RPM_MAXValue0}, required-interface=TI_SR_Tacho_RPM_MAX
    behavior IB_FastGaugeAdapter
      operation invoked event OIE_pp_Init_FastGaugeAdapter_InitTrigByInit: start-on-event=FastGaugeAdapter_Init, operation=pp_Init.Init
      timing event TEFastGaugeAdapter_Task: start-on-event=FastGaugeAdapter_Task, period=0.02
      port-api-options:
        enable-take-address=false, indirect-api=false, port=pp_FastGaugeInfo
        enable-take-address=false, indirect-api=false, port=FastGaugeAdapter/pp_Init
        enable-take-address=false, indirect-api=false, port=FastGaugeAdapter/rpIgnSubstate
        enable-take-address=false, indirect-api=false, port=rp_Analog_Tacho
        enable-take-address=false, indirect-api=false, port=FastGaugeAdapter/rp_ClusterMode
        enable-take-address=false, indirect-api=false, port=FastGaugeAdapter/rp_Dcm_appStop
        enable-take-address=false, indirect-api=false, port=FastGaugeAdapter/rp_Diag_Digitalspeed
        enable-take-address=false, indirect-api=false, port=rp_Digital_Tacho
        enable-take-address=false, indirect-api=false, port=FastGaugeAdapter/rp_DispDistanceUnit
        enable-take-address=false, indirect-api=false, port=rp_DispSpeedA
        enable-take-address=false, indirect-api=false, port=rp_Display_speed_Value
        enable-take-address=false, indirect-api=false, port=FastGaugeAdapter/rp_HMIReadyState
        enable-take-address=false, indirect-api=false, port=rp_Needle_Transparent
        enable-take-address=false, indirect-api=false, port=FastGaugeAdapter/rp_PowerTrain_State
        enable-take-address=false, indirect-api=false, port=rp_SubDisplaySpeed_Value
        enable-take-address=false, indirect-api=false, port=rp_TC_Unit
        enable-take-address=false, indirect-api=false, port=rp_Tacho_RED_Start_RPM
        enable-take-address=false, indirect-api=false, port=rp_Tacho_RPM_MAX
      runnable FastGaugeAdapter_Init: can-be-invoked-concurrently=true
      runnable FastGaugeAdapter_Task: can-be-invoked-concurrently=true
        data-receive-point-by-arguments:
          16 x access:
            DRA_rpIgnSubstate_IgnitionSubstate: accessed-variable=rpIgnSubstate.IgnitionSubstate
            DRA_rp_Analog_Tacho_Analog_Tacho: accessed-variable=rp_Analog_Tacho.Analog_Tacho
            DRA_rp_ClusterMode_WSSCurrentClusterMode: accessed-variable=rp_ClusterMode.WSSCurrentClusterMode
            DRA_rp_Dcm_appStop_AppId: accessed-variable=rp_Dcm_appStop.AppId
            DRA_rp_Diag_Digitalspeed_Diag_Digital_Speed_Value: accessed-variable=rp_Diag_Digitalspeed.Diag_Digital_Speed_Value
            DRA_rp_Digital_Tacho_Digital_Tacho: accessed-variable=rp_Digital_Tacho.Digital_Tacho
            DRA_rp_DispDistanceUnit_DisplayUnit: accessed-variable=rp_DispDistanceUnit.DisplayUnit
            DRA_rp_DispSpeedA_DispSpeedVal: accessed-variable=rp_DispSpeedA.DispSpeedVal
            DRA_rp_Display_speed_Value_Digital_Speed_Value: accessed-variable=rp_Display_speed_Value.Digital_Speed_Value
            DRA_rp_HMIReadyState_HMI_ReadyStatus: accessed-variable=rp_HMIReadyState.HMI_ReadyStatus
            DRA_rp_Needle_Transparent_Needle_TR: accessed-variable=rp_Needle_Transparent.Needle_TR
            DRA_rp_PowerTrain_State_PowerTrain_Flag: accessed-variable=rp_PowerTrain_State.PowerTrain_Flag
            DRA_rp_SubDisplaySpeed_Value_SubDispSpeedVal: accessed-variable=rp_SubDisplaySpeed_Value.SubDispSpeedVal
            DRA_rp_TC_Unit_Digital_TachoUnit: accessed-variable=rp_TC_Unit.Digital_TachoUnit
            DRA_rp_Tacho_RED_Start_RPM_RED_Start_RPM: accessed-variable=rp_Tacho_RED_Start_RPM.RED_Start_RPM
            DRA_rp_Tacho_RPM_MAX_REVP_RPM_MAX: accessed-variable=rp_Tacho_RPM_MAX.REVP_RPM_MAX
        data-send-points:
          access DWA_pp_FastGaugeInfo_FastGaugeInfoData: accessed-variable=pp_FastGaugeInfo.FastGaugeInfoData
  17 x constant specification:
    FastGaugeAdapterFastGaugeInfoDataValue0: value-spec={short-label=FastGaugeAdapterFastGaugeInfoDataValue0, fields={short-label=FastGaugeAdapterFastGaugeInfoDataValue_0, fields=[FastGaugeAdaptergaugeInfo_4Value_0:0, FastGaugeAdaptergaugeInfo_4Value_1:0, FastGaugeAdaptergaugeInfo_4Value_2:0, FastGaugeAdaptergaugeInfo_4Value_3:0, FastGaugeAdaptergaugeInfo_4Value_4:0]}}
    FastGaugeAdapterIgnitionSubstateValue0: value-spec=FastGaugeAdapterIgnitionSubstateValue0:0
    FastGaugeAdapterAnalog_TachoValue0: value-spec=FastGaugeAdapterAnalog_TachoValue0:0
    FastGaugeAdapterWSSCurrentClusterModeValue0: value-spec=FastGaugeAdapterWSSCurrentClusterModeValue0:0
    FastGaugeAdapterAppIdValue0: value-spec=FastGaugeAdapterAppIdValue0:0
    FastGaugeAdapterDiag_Digital_Speed_ValueValue0: value-spec=FastGaugeAdapterDiag_Digital_Speed_ValueValue0:0
    FastGaugeAdapterDigital_TachoValue0: value-spec=FastGaugeAdapterDigital_TachoValue0:0
    FastGaugeAdapterDisplayUnitValue0: value-spec=FastGaugeAdapterDisplayUnitValue0:0
    FastGaugeAdapterDispSpeedValValue0: value-spec=FastGaugeAdapterDispSpeedValValue0:0
    FastGaugeAdapterDigital_Speed_ValueValue0: value-spec=FastGaugeAdapterDigital_Speed_ValueValue0:0
    FastGaugeAdapterHMI_ReadyStatusValue0: value-spec=FastGaugeAdapterHMI_ReadyStatusValue0:0
    FastGaugeAdapterNeedle_TRValue0: value-spec=FastGaugeAdapterNeedle_TRValue0:0
    FastGaugeAdapterPowerTrain_FlagValue0: value-spec=FastGaugeAdapterPowerTrain_FlagValue0:0
    FastGaugeAdapterSubDispSpeedValValue0: value-spec=FastGaugeAdapterSubDispSpeedValValue0:0
    FastGaugeAdapterDigital_TachoUnitValue0: value-spec=FastGaugeAdapterDigital_TachoUnitValue0:false
    FastGaugeAdapterRED_Start_RPMValue0: value-spec=FastGaugeAdapterRED_Start_RPMValue0:0
    FastGaugeAdapterREVP_RPM_MAXValue0: value-spec=FastGaugeAdapterREVP_RPM_MAXValue0:0
  swc implementation IMPL_FastGaugeAdapter: programming-language=C, behavior=IB_FastGaugeAdapter
    code-descriptors:
      code CodeDescriptor
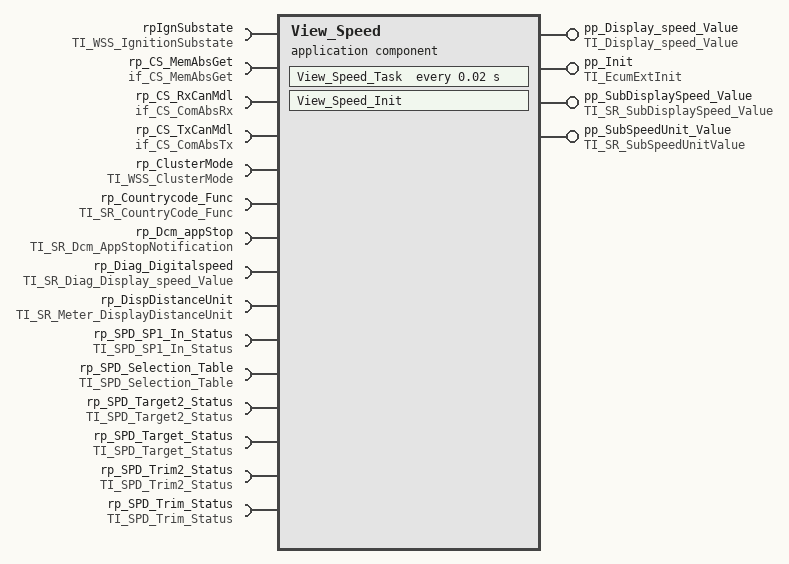
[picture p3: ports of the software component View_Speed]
  application sw component type View_Speed
    4 x provide port:
      pp_Display_speed_Value: nonqueued-sender-com-spec{data-element=Digital_Speed_Value, init-value=constant-reference=View_SpeedDigital_Speed_ValueValue0}, provided-interface=TI_Display_speed_Value
      pp_Init: server-com-spec{operation=TI_EcumExtInit/Init, queue-length=1}, provided-interface=TI_EcumExtInit
      pp_SubDisplaySpeed_Value: nonqueued-sender-com-spec{data-element=SubDispSpeedVal, init-value=constant-reference=View_SpeedSubDispSpeedValValue0}, provided-interface=TI_SR_SubDisplaySpeed_Value
      pp_SubSpeedUnit_Value: nonqueued-sender-com-spec{data-element=SubSpeedunit, init-value=constant-reference=View_SpeedSubSpeedunitValue0}, provided-interface=TI_SR_SubSpeedUnitValue
    15 x require port:
      rpIgnSubstate: nonqueued-receiver-com-spec{data-element=IgnitionSubstate, init-value=constant-reference=View_SpeedIgnitionSubstateValue0}, required-interface=TI_WSS_IgnitionSubstate
      rp_CS_MemAbsGet: required-interface=if_CS_MemAbsGet
      rp_CS_RxCanMdl: required-interface=if_CS_ComAbsRx
      rp_CS_TxCanMdl: required-interface=if_CS_ComAbsTx
      rp_ClusterMode: nonqueued-receiver-com-spec{data-element=WSSCurrentClusterMode, init-value=constant-reference=View_SpeedWSSCurrentClusterModeValue0}, required-interface=TI_WSS_ClusterMode
      rp_Countrycode_Func: nonqueued-receiver-com-spec{data-element=CountryCode_Func, init-value=constant-reference=View_SpeedCountryCode_FuncValue0}, required-interface=TI_SR_CountryCode_Func
      rp_Dcm_appStop: nonqueued-receiver-com-spec{data-element=AppId, init-value=constant-reference=View_SpeedAppIdValue0}, required-interface=TI_SR_Dcm_AppStopNotification
      rp_Diag_Digitalspeed: nonqueued-receiver-com-spec{data-element=Diag_Digital_Speed_Value, init-value=constant-reference=View_SpeedDiag_Digital_Speed_ValueValue0}, required-interface=TI_SR_Diag_Display_speed_Value
      rp_DispDistanceUnit: nonqueued-receiver-com-spec{data-element=DisplayUnit, init-value=constant-reference=View_SpeedDisplayUnitValue0}, required-interface=TI_SR_Meter_DisplayDistanceUnit
      rp_SPD_SP1_In_Status: nonqueued-receiver-com-spec{data-element=SP1_In_Status, init-value=constant-reference=View_SpeedSP1_In_StatusValue0}, required-interface=TI_SPD_SP1_In_Status
      rp_SPD_Selection_Table: nonqueued-receiver-com-spec{data-element=Speed_Selection_Table, init-value=constant-reference=View_SpeedSpeed_Selection_TableValue0}, required-interface=TI_SPD_Selection_Table
      rp_SPD_Target2_Status: nonqueued-receiver-com-spec{data-element=Spd_Target2_Status, init-value=constant-reference=View_SpeedSpd_Target2_StatusValue0}, required-interface=TI_SPD_Target2_Status
      rp_SPD_Target_Status: nonqueued-receiver-com-spec{data-element=Spd_Target_Status, init-value=constant-reference=View_SpeedSpd_Target_StatusValue0}, required-interface=TI_SPD_Target_Status
      rp_SPD_Trim2_Status: nonqueued-receiver-com-spec{data-element=Spd_Trim2_Status, init-value=constant-reference=View_SpeedSpd_Trim2_StatusValue0}, required-interface=TI_SPD_Trim2_Status
      rp_SPD_Trim_Status: nonqueued-receiver-com-spec{data-element=Spd_Trim_Status, init-value=constant-reference=View_SpeedSpd_Trim_StatusValue0}, required-interface=TI_SPD_Trim_Status
    behavior IB_View_Speed
      operation invoked event OIE_pp_Init_View_Speed_InitTrigByInit: start-on-event=View_Speed_Init, operation=pp_Init.Init
      timing event TEView_Speed_Task: start-on-event=View_Speed_Task, period=0.02
      port-api-options:
        enable-take-address=false, indirect-api=false, port=pp_Display_speed_Value
        enable-take-address=false, indirect-api=false, port=View_Speed/pp_Init
        enable-take-address=false, indirect-api=false, port=pp_SubDisplaySpeed_Value
        enable-take-address=false, indirect-api=false, port=pp_SubSpeedUnit_Value
        enable-take-address=false, indirect-api=false, port=View_Speed/rpIgnSubstate
        enable-take-address=false, indirect-api=false, port=View_Speed/rp_CS_MemAbsGet
        enable-take-address=false, indirect-api=false, port=View_Speed/rp_CS_RxCanMdl
        enable-take-address=false, indirect-api=false, port=View_Speed/rp_CS_TxCanMdl
        enable-take-address=false, indirect-api=false, port=View_Speed/rp_ClusterMode
        enable-take-address=false, indirect-api=false, port=View_Speed/rp_Countrycode_Func
        enable-take-address=false, indirect-api=false, port=View_Speed/rp_Dcm_appStop
        enable-take-address=false, indirect-api=false, port=View_Speed/rp_Diag_Digitalspeed
        enable-take-address=false, indirect-api=false, port=View_Speed/rp_DispDistanceUnit
        enable-take-address=false, indirect-api=false, port=View_Speed/rp_SPD_SP1_In_Status
        enable-take-address=false, indirect-api=false, port=rp_SPD_Selection_Table
        enable-take-address=false, indirect-api=false, port=rp_SPD_Target2_Status
        enable-take-address=false, indirect-api=false, port=rp_SPD_Target_Status
        enable-take-address=false, indirect-api=false, port=rp_SPD_Trim2_Status
        enable-take-address=false, indirect-api=false, port=rp_SPD_Trim_Status
      runnable View_Speed_Init: can-be-invoked-concurrently=true
      runnable View_Speed_Task: can-be-invoked-concurrently=true
        data-receive-point-by-arguments:
          12 x access:
            DRA_rpIgnSubstate_IgnitionSubstate: accessed-variable=rpIgnSubstate.IgnitionSubstate
            DRA_rp_ClusterMode_WSSCurrentClusterMode: accessed-variable=rp_ClusterMode.WSSCurrentClusterMode
            DRA_rp_Countrycode_Func_CountryCode_Func: accessed-variable=rp_Countrycode_Func.CountryCode_Func
            DRA_rp_Dcm_appStop_AppId: accessed-variable=rp_Dcm_appStop.AppId
            DRA_rp_Diag_Digitalspeed_Diag_Digital_Speed_Value: accessed-variable=rp_Diag_Digitalspeed.Diag_Digital_Speed_Value
            DRA_rp_DispDistanceUnit_DisplayUnit: accessed-variable=rp_DispDistanceUnit.DisplayUnit
            DRA_rp_SPD_SP1_In_Status_SP1_In_Status: accessed-variable=rp_SPD_SP1_In_Status.SP1_In_Status
            DRA_rp_SPD_Selection_Table_Speed_Selection_Table: accessed-variable=rp_SPD_Selection_Table.Speed_Selection_Table
            DRA_rp_SPD_Target2_Status_Spd_Target2_Status: accessed-variable=rp_SPD_Target2_Status.Spd_Target2_Status
            DRA_rp_SPD_Target_Status_Spd_Target_Status: accessed-variable=rp_SPD_Target_Status.Spd_Target_Status
            DRA_rp_SPD_Trim2_Status_Spd_Trim2_Status: accessed-variable=rp_SPD_Trim2_Status.Spd_Trim2_Status
            DRA_rp_SPD_Trim_Status_Spd_Trim_Status: accessed-variable=rp_SPD_Trim_Status.Spd_Trim_Status
        data-send-points:
          access DWA_pp_Display_speed_Value_Digital_Speed_Value: accessed-variable=pp_Display_speed_Value.Digital_Speed_Value
          access DWA_pp_SubDisplaySpeed_Value_SubDispSpeedVal: accessed-variable=pp_SubDisplaySpeed_Value.SubDispSpeedVal
          access DWA_pp_SubSpeedUnit_Value_SubSpeedunit: accessed-variable=pp_SubSpeedUnit_Value.SubSpeedunit
        109 x sync call, all with timeout=0.0:
          OA_rp_CS_MemAbsGet_Get_BsShare_SwUpdReflash_Element: operation=rp_CS_MemAbsGet.Get_BsShare_SwUpdReflash_Element
          OA_rp_CS_MemAbsGet_Get_BsShare_SwUpdFotaMode_Element: operation=rp_CS_MemAbsGet.Get_BsShare_SwUpdFotaMode_Element
          OA_rp_CS_MemAbsGet_Get_BsShare_SwUpdFotaFinPrint_Element: operation=rp_CS_MemAbsGet.Get_BsShare_SwUpdFotaFinPrint_Element
          OA_rp_CS_MemAbsGet_Get_BsShare_SwUpdFotaStatus_Element: operation=rp_CS_MemAbsGet.Get_BsShare_SwUpdFotaStatus_Element
          OA_rp_CS_MemAbsGet_Get_BsShare_SwUpdFotadecrypt_Element: operation=rp_CS_MemAbsGet.Get_BsShare_SwUpdFotadecrypt_Element
          OA_rp_CS_MemAbsGet_Get_BsShare_EcuPartNumber_Element: operation=rp_CS_MemAbsGet.Get_BsShare_EcuPartNumber_Element
          OA_rp_CS_MemAbsGet_Get_BsShare_VisteonPartNumber: operation=rp_CS_MemAbsGet.Get_BsShare_VisteonPartNumber
          OA_rp_CS_MemAbsGet_Get_BsShare_VisteonPCBPartNumber: operation=rp_CS_MemAbsGet.Get_BsShare_VisteonPCBPartNumber
          OA_rp_CS_MemAbsGet_Get_BsShare_ProductSerialNumber: operation=rp_CS_MemAbsGet.Get_BsShare_ProductSerialNumber
          OA_rp_CS_MemAbsGet_Get_BsShare_PCBSerialNumber: operation=rp_CS_MemAbsGet.Get_BsShare_PCBSerialNumber
          OA_rp_CS_MemAbsGet_Get_BsShare_SMTManufacturingDate: operation=rp_CS_MemAbsGet.Get_BsShare_SMTManufacturingDate
          OA_rp_CS_MemAbsGet_Get_BsShare_AssemblyManufacturingDate: operation=rp_CS_MemAbsGet.Get_BsShare_AssemblyManufacturingDate
          OA_rp_CS_MemAbsGet_Get_BsShare_SMTPlantNumber: operation=rp_CS_MemAbsGet.Get_BsShare_SMTPlantNumber
          OA_rp_CS_MemAbsGet_Get_BsShare_AssemblyPlantNumber: operation=rp_CS_MemAbsGet.Get_BsShare_AssemblyPlantNumber
          OA_rp_CS_MemAbsGet_Get_BsShare_HWModification: operation=rp_CS_MemAbsGet.Get_BsShare_HWModification
          OA_rp_CS_MemAbsGet_Get_BsShare_VisMeet_Element: operation=rp_CS_MemAbsGet.Get_BsShare_VisMeet_Element
          OA_rp_CS_MemAbsGet_Get_BsShare_VisMeet_EOLEntry_Element: operation=rp_CS_MemAbsGet.Get_BsShare_VisMeet_EOLEntry_Element
          OA_rp_CS_MemAbsGet_Get_BsShare_VehicleConfig_Element: operation=rp_CS_MemAbsGet.Get_BsShare_VehicleConfig_Element
          OA_rp_CS_MemAbsGet_Get_BsConst_SpeedoGauge_Element: operation=rp_CS_MemAbsGet.Get_BsConst_SpeedoGauge_Element
          OA_rp_CS_MemAbsGet_Get_BsConst_TachoGauge_Element: operation=rp_CS_MemAbsGet.Get_BsConst_TachoGauge_Element
          OA_rp_CS_MemAbsGet_Get_BsConst_FuelGauge_Element: operation=rp_CS_MemAbsGet.Get_BsConst_FuelGauge_Element
          OA_rp_CS_MemAbsGet_Get_BsConst_TempGauge_Element: operation=rp_CS_MemAbsGet.Get_BsConst_TempGauge_Element
          OA_rp_CS_MemAbsGet_Get_BsConst_PowerGauge_Element: operation=rp_CS_MemAbsGet.Get_BsConst_PowerGauge_Element
          OA_rp_CS_MemAbsGet_Get_BsConst_OilGauge_Element: operation=rp_CS_MemAbsGet.Get_BsConst_OilGauge_Element
          OA_rp_CS_MemAbsGet_Get_BsConst_TripComputer_Element: operation=rp_CS_MemAbsGet.Get_BsConst_TripComputer_Element
          OA_rp_CS_MemAbsGet_Get_BsConst_Compensation_Line_Slope_m: operation=rp_CS_MemAbsGet.Get_BsConst_Compensation_Line_Slope_m
          OA_rp_CS_MemAbsGet_Get_BsConst_Compensation_Line_Shift_b: operation=rp_CS_MemAbsGet.Get_BsConst_Compensation_Line_Shift_b
          OA_rp_CS_MemAbsGet_Get_BsConst_Lookup_Curve_HotSpot_Coef_X: operation=rp_CS_MemAbsGet.Get_BsConst_Lookup_Curve_HotSpot_Coef_X
          OA_rp_CS_MemAbsGet_Get_BsConst_Lookup_Curve_HotSpot_Coef_Y: operation=rp_CS_MemAbsGet.Get_BsConst_Lookup_Curve_HotSpot_Coef_Y
          OA_rp_CS_MemAbsGet_Get_BsConst_Temp_Threshold_Hysteresis_Derating: operation=rp_CS_MemAbsGet.Get_BsConst_Temp_Threshold_Hysteresis_Derating
          OA_rp_CS_MemAbsGet_Get_BsConst_Derating_Backlight_Disable: operation=rp_CS_MemAbsGet.Get_BsConst_Derating_Backlight_Disable
          OA_rp_CS_MemAbsGet_Get_BsConst_Temperature_Sensor_Conv: operation=rp_CS_MemAbsGet.Get_BsConst_Temperature_Sensor_Conv
          OA_rp_CS_MemAbsGet_Get_BsConst_PCB_Temperature_Sensor_Conv: operation=rp_CS_MemAbsGet.Get_BsConst_PCB_Temperature_Sensor_Conv
          OA_rp_CS_MemAbsGet_Get_BsConst_Display_Illum_Max_Level: operation=rp_CS_MemAbsGet.Get_BsConst_Display_Illum_Max_Level
          OA_rp_CS_MemAbsGet_Get_BsConst_PWM_boost_bypass_duty: operation=rp_CS_MemAbsGet.Get_BsConst_PWM_boost_bypass_duty
          OA_rp_CS_MemAbsGet_Get_BsConst_BsConst_Illumination_ReservedByte: operation=rp_CS_MemAbsGet.Get_BsConst_BsConst_Illumination_ReservedByte
          OA_rp_CS_MemAbsGet_Get_BsConst_Compensation_Line_Slope_m_SafeCopy1: operation=rp_CS_MemAbsGet.Get_BsConst_Compensation_Line_Slope_m_SafeCopy1
          OA_rp_CS_MemAbsGet_Get_BsConst_Compensation_Line_Shift_b_SafeCopy1: operation=rp_CS_MemAbsGet.Get_BsConst_Compensation_Line_Shift_b_SafeCopy1
          OA_rp_CS_MemAbsGet_Get_BsConst_Lookup_Curve_HotSpot_Coef_X_SafeCopy1: operation=rp_CS_MemAbsGet.Get_BsConst_Lookup_Curve_HotSpot_Coef_X_SafeCopy1
          OA_rp_CS_MemAbsGet_Get_BsConst_Lookup_Curve_HotSpot_Coef_Y_SafeCopy1: operation=rp_CS_MemAbsGet.Get_BsConst_Lookup_Curve_HotSpot_Coef_Y_SafeCopy1
          OA_rp_CS_MemAbsGet_Get_BsConst_Temp_Threshold_Hysteresis_Derating_SafeCopy1: operation=rp_CS_MemAbsGet.Get_BsConst_Temp_Threshold_Hysteresis_Derating_SafeCopy1
          OA_rp_CS_MemAbsGet_Get_BsConst_Derating_Backlight_Disable_SafeCopy1: operation=rp_CS_MemAbsGet.Get_BsConst_Derating_Backlight_Disable_SafeCopy1
          OA_rp_CS_MemAbsGet_Get_BsConst_Temperature_Sensor_Conv_SafeCopy1: operation=rp_CS_MemAbsGet.Get_BsConst_Temperature_Sensor_Conv_SafeCopy1
          OA_rp_CS_MemAbsGet_Get_BsConst_PCB_Temperature_Sensor_Conv_SafeCopy1: operation=rp_CS_MemAbsGet.Get_BsConst_PCB_Temperature_Sensor_Conv_SafeCopy1
          OA_rp_CS_MemAbsGet_Get_BsConst_Display_Illum_Max_Level_SafeCopy1: operation=rp_CS_MemAbsGet.Get_BsConst_Display_Illum_Max_Level_SafeCopy1
          OA_rp_CS_MemAbsGet_Get_BsConst_PWM_boost_bypass_duty_SafeCopy1: operation=rp_CS_MemAbsGet.Get_BsConst_PWM_boost_bypass_duty_SafeCopy1
          OA_rp_CS_MemAbsGet_Get_BsConst_BsConst_Illumination_ReservedByte_SafeCopy1: operation=rp_CS_MemAbsGet.Get_BsConst_BsConst_Illumination_ReservedByte_SafeCopy1
          OA_rp_CS_MemAbsGet_Get_BsConst_Compensation_Line_Slope_m_SafeCopy2: operation=rp_CS_MemAbsGet.Get_BsConst_Compensation_Line_Slope_m_SafeCopy2
          OA_rp_CS_MemAbsGet_Get_BsConst_Compensation_Line_Shift_b_SafeCopy2: operation=rp_CS_MemAbsGet.Get_BsConst_Compensation_Line_Shift_b_SafeCopy2
          OA_rp_CS_MemAbsGet_Get_BsConst_Lookup_Curve_HotSpot_Coef_X_SafeCopy2: operation=rp_CS_MemAbsGet.Get_BsConst_Lookup_Curve_HotSpot_Coef_X_SafeCopy2
          OA_rp_CS_MemAbsGet_Get_BsConst_Lookup_Curve_HotSpot_Coef_Y_SafeCopy2: operation=rp_CS_MemAbsGet.Get_BsConst_Lookup_Curve_HotSpot_Coef_Y_SafeCopy2
          OA_rp_CS_MemAbsGet_Get_BsConst_Temp_Threshold_Hysteresis_Derating_SafeCopy2: operation=rp_CS_MemAbsGet.Get_BsConst_Temp_Threshold_Hysteresis_Derating_SafeCopy2
          OA_rp_CS_MemAbsGet_Get_BsConst_Derating_Backlight_Disable_SafeCopy2: operation=rp_CS_MemAbsGet.Get_BsConst_Derating_Backlight_Disable_SafeCopy2
          OA_rp_CS_MemAbsGet_Get_BsConst_Temperature_Sensor_Conv_SafeCopy2: operation=rp_CS_MemAbsGet.Get_BsConst_Temperature_Sensor_Conv_SafeCopy2
          OA_rp_CS_MemAbsGet_Get_BsConst_PCB_Temperature_Sensor_Conv_SafeCopy2: operation=rp_CS_MemAbsGet.Get_BsConst_PCB_Temperature_Sensor_Conv_SafeCopy2
          OA_rp_CS_MemAbsGet_Get_BsConst_Display_Illum_Max_Level_SafeCopy2: operation=rp_CS_MemAbsGet.Get_BsConst_Display_Illum_Max_Level_SafeCopy2
          OA_rp_CS_MemAbsGet_Get_BsConst_PWM_boost_bypass_duty_SafeCopy2: operation=rp_CS_MemAbsGet.Get_BsConst_PWM_boost_bypass_duty_SafeCopy2
          OA_rp_CS_MemAbsGet_Get_BsConst_BsConst_Illumination_ReservedByte_SafeCopy2: operation=rp_CS_MemAbsGet.Get_BsConst_BsConst_Illumination_ReservedByte_SafeCopy2
          OA_rp_CS_MemAbsGet_Get_BsConst_Audio_Element: operation=rp_CS_MemAbsGet.Get_BsConst_Audio_Element
          OA_rp_CS_MemAbsGet_Get_BsConst_Warning_Element: operation=rp_CS_MemAbsGet.Get_BsConst_Warning_Element
          OA_rp_CS_MemAbsGet_Get_BsConst_RealTimeClock_Element: operation=rp_CS_MemAbsGet.Get_BsConst_RealTimeClock_Element
          OA_rp_CS_MemAbsGet_Get_BsConst_Communication_Element: operation=rp_CS_MemAbsGet.Get_BsConst_Communication_Element
          OA_rp_CS_MemAbsGet_Get_BsConst_Power_Element: operation=rp_CS_MemAbsGet.Get_BsConst_Power_Element
          OA_rp_CS_MemAbsGet_Get_BsConst_ServiceReminder_Element: operation=rp_CS_MemAbsGet.Get_BsConst_ServiceReminder_Element
          OA_rp_CS_MemAbsGet_Get_BsConst_EngOffTimer_Element: operation=rp_CS_MemAbsGet.Get_BsConst_EngOffTimer_Element
          OA_rp_CS_MemAbsGet_Get_BsCys_Certicificate_Element: operation=rp_CS_MemAbsGet.Get_BsCys_Certicificate_Element
          OA_rp_CS_MemAbsGet_Get_RefCys_Certicificate_Element: operation=rp_CS_MemAbsGet.Get_RefCys_Certicificate_Element
          OA_rp_CS_MemAbsGet_Get_RefCys_Certicificate1_Element: operation=rp_CS_MemAbsGet.Get_RefCys_Certicificate1_Element
          OA_rp_CS_MemAbsGet_Get_BsRt_Odometer_Element: operation=rp_CS_MemAbsGet.Get_BsRt_Odometer_Element
          OA_rp_CS_MemAbsGet_Get_BsRt_SpeedoGauge_Element: operation=rp_CS_MemAbsGet.Get_BsRt_SpeedoGauge_Element
          OA_rp_CS_MemAbsGet_Get_BsRt_TachoGauge_Element: operation=rp_CS_MemAbsGet.Get_BsRt_TachoGauge_Element
          OA_rp_CS_MemAbsGet_Get_BsRt_FuelGauge_Element: operation=rp_CS_MemAbsGet.Get_BsRt_FuelGauge_Element
          OA_rp_CS_MemAbsGet_Get_BsRt_TempGauge_Element: operation=rp_CS_MemAbsGet.Get_BsRt_TempGauge_Element
          OA_rp_CS_MemAbsGet_Get_BsRt_PowerGauge_Element: operation=rp_CS_MemAbsGet.Get_BsRt_PowerGauge_Element
          OA_rp_CS_MemAbsGet_Get_BsRt_OilGauge_Element: operation=rp_CS_MemAbsGet.Get_BsRt_OilGauge_Element
          OA_rp_CS_MemAbsGet_Get_BsRt_TripComputer_Element: operation=rp_CS_MemAbsGet.Get_BsRt_TripComputer_Element
          OA_rp_CS_MemAbsGet_Get_BsRt_Warning_Element: operation=rp_CS_MemAbsGet.Get_BsRt_Warning_Element
          OA_rp_CS_MemAbsGet_Get_BsRt_RealTimeClock_Element: operation=rp_CS_MemAbsGet.Get_BsRt_RealTimeClock_Element
          OA_rp_CS_MemAbsGet_Get_BsRt_Personalization_Element: operation=rp_CS_MemAbsGet.Get_BsRt_Personalization_Element
          OA_rp_CS_MemAbsGet_Get_BsRt_Illumination_Element: operation=rp_CS_MemAbsGet.Get_BsRt_Illumination_Element
          OA_rp_CS_MemAbsGet_Get_BsRt_CusDlt_Element: operation=rp_CS_MemAbsGet.Get_BsRt_CusDlt_Element
          OA_rp_CS_MemAbsGet_Get_BsReten_Odometer_Element: operation=rp_CS_MemAbsGet.Get_BsReten_Odometer_Element
          OA_rp_CS_MemAbsGet_Get_BsReten_Gauges_Element: operation=rp_CS_MemAbsGet.Get_BsReten_Gauges_Element
          OA_rp_CS_MemAbsGet_Get_BsReten_Tripcomputer_Element: operation=rp_CS_MemAbsGet.Get_BsReten_Tripcomputer_Element
          OA_rp_CS_MemAbsGet_Get_BsReten_Illumination_Element: operation=rp_CS_MemAbsGet.Get_BsReten_Illumination_Element
          OA_rp_CS_MemAbsGet_Get_BsReten_Audio_Element: operation=rp_CS_MemAbsGet.Get_BsReten_Audio_Element
          OA_rp_CS_MemAbsGet_Get_BsReten_Warning_Element: operation=rp_CS_MemAbsGet.Get_BsReten_Warning_Element
          OA_rp_CS_MemAbsGet_Get_BsReten_RealTimeClock_Element: operation=rp_CS_MemAbsGet.Get_BsReten_RealTimeClock_Element
          OA_rp_CS_MemAbsGet_Get_BsReten_Communication_Element: operation=rp_CS_MemAbsGet.Get_BsReten_Communication_Element
          OA_rp_CS_MemAbsGet_Get_BsReten_Personalization_Element: operation=rp_CS_MemAbsGet.Get_BsReten_Personalization_Element
          OA_rp_CS_MemAbsGet_Get_BsReten_VisDlt_Element: operation=rp_CS_MemAbsGet.Get_BsReten_VisDlt_Element
          OA_rp_CS_MemAbsGet_Get_BsReten_Power_Element: operation=rp_CS_MemAbsGet.Get_BsReten_Power_Element
          OA_rp_CS_MemAbsGet_Get_BsReten_Display_Element: operation=rp_CS_MemAbsGet.Get_BsReten_Display_Element
          OA_rp_CS_MemAbsGet_Get_BsDiag_ErrorRecord_Element: operation=rp_CS_MemAbsGet.Get_BsDiag_ErrorRecord_Element
          OA_rp_CS_MemAbsGet_Get_BsDiag_Dtc_Element: operation=rp_CS_MemAbsGet.Get_BsDiag_Dtc_Element
          OA_rp_CS_RxCanMdl_RxCan_GetSignalValueU8Arr: operation=rp_CS_RxCanMdl.RxCan_GetSignalValueU8Arr
          OA_rp_CS_RxCanMdl_RxCan_SetSignalInitValue: operation=rp_CS_RxCanMdl.RxCan_SetSignalInitValue
          OA_rp_CS_RxCanMdl_RxCan_SetSignalInitValueU8Arr: operation=rp_CS_RxCanMdl.RxCan_SetSignalInitValueU8Arr
          OA_rp_CS_RxCanMdl_RxCan_SignalInvalidProcessingControl: operation=rp_CS_RxCanMdl.RxCan_SignalInvalidProcessingControl
          OA_rp_CS_RxCanMdl_RxCan_SignalMissingProcessingControl: operation=rp_CS_RxCanMdl.RxCan_SignalMissingProcessingControl
          OA_rp_CS_RxCanMdl_RxCan_SignalNRProcessingControl: operation=rp_CS_RxCanMdl.RxCan_SignalNRProcessingControl
          OA_rp_CS_RxCanMdl_RxCan_SignalGetJustRcvdStatus: operation=rp_CS_RxCanMdl.RxCan_SignalGetJustRcvdStatus
          OA_rp_CS_RxCanMdl_RxCan_SignalClearJustRcvdStatus: operation=rp_CS_RxCanMdl.RxCan_SignalClearJustRcvdStatus
          OA_rp_CS_RxCanMdl_RxCan_GetSignalValue: operation=rp_CS_RxCanMdl.RxCan_GetSignalValue
          OA_rp_CS_TxCanMdl_TxCan_ClearCanSignalTxConfirmation: operation=rp_CS_TxCanMdl.TxCan_ClearCanSignalTxConfirmation
          OA_rp_CS_TxCanMdl_TxCan_GetCanSignalTxConfirmation: operation=rp_CS_TxCanMdl.TxCan_GetCanSignalTxConfirmation
          OA_rp_CS_TxCanMdl_TxCan_SetSignalFromRetentionBuffer: operation=rp_CS_TxCanMdl.TxCan_SetSignalFromRetentionBuffer
          OA_rp_CS_TxCanMdl_TxCan_SetSignalValue: operation=rp_CS_TxCanMdl.TxCan_SetSignalValue
          OA_rp_CS_TxCanMdl_TxCan_SetSignalValueU8Arr: operation=rp_CS_TxCanMdl.TxCan_SetSignalValueU8Arr
  15 x constant specification:
    View_SpeedDigital_Speed_ValueValue0: value-spec=View_SpeedDigital_Speed_ValueValue0:0
    View_SpeedSubDispSpeedValValue0: value-spec=View_SpeedSubDispSpeedValValue0:0
    View_SpeedSubSpeedunitValue0: value-spec=View_SpeedSubSpeedunitValue0:0
    View_SpeedIgnitionSubstateValue0: value-spec=View_SpeedIgnitionSubstateValue0:0
    View_SpeedWSSCurrentClusterModeValue0: value-spec=View_SpeedWSSCurrentClusterModeValue0:0
    View_SpeedCountryCode_FuncValue0: value-spec=View_SpeedCountryCode_FuncValue0:0
    View_SpeedAppIdValue0: value-spec=View_SpeedAppIdValue0:0
    View_SpeedDiag_Digital_Speed_ValueValue0: value-spec=View_SpeedDiag_Digital_Speed_ValueValue0:0
    View_SpeedDisplayUnitValue0: value-spec=View_SpeedDisplayUnitValue0:0
    View_SpeedSP1_In_StatusValue0: value-spec=View_SpeedSP1_In_StatusValue0:0
    View_SpeedSpeed_Selection_TableValue0: value-spec=View_SpeedSpeed_Selection_TableValue0:0
    View_SpeedSpd_Target2_StatusValue0: value-spec=View_SpeedSpd_Target2_StatusValue0:0
    View_SpeedSpd_Target_StatusValue0: value-spec=View_SpeedSpd_Target_StatusValue0:0
    View_SpeedSpd_Trim2_StatusValue0: value-spec=View_SpeedSpd_Trim2_StatusValue0:0
    View_SpeedSpd_Trim_StatusValue0: value-spec=View_SpeedSpd_Trim_StatusValue0:0
  swc implementation IMPL_View_Speed: programming-language=C, behavior=IB_View_Speed
    code-descriptors:
      code CodeDescriptor
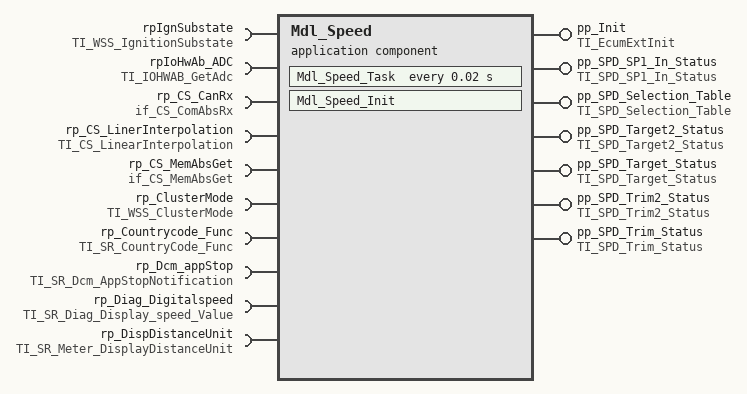
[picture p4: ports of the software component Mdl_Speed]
  application sw component type Mdl_Speed
    7 x provide port:
      pp_Init: server-com-spec{operation=TI_EcumExtInit/Init, queue-length=1}, provided-interface=TI_EcumExtInit
      pp_SPD_SP1_In_Status: nonqueued-sender-com-spec{data-element=SP1_In_Status, init-value=constant-reference=Mdl_SpeedSP1_In_StatusValue0}, provided-interface=TI_SPD_SP1_In_Status
      pp_SPD_Selection_Table: nonqueued-sender-com-spec{data-element=Speed_Selection_Table, init-value=constant-reference=Mdl_SpeedSpeed_Selection_TableValue0}, provided-interface=TI_SPD_Selection_Table
      pp_SPD_Target2_Status: nonqueued-sender-com-spec{data-element=Spd_Target2_Status, init-value=constant-reference=Mdl_SpeedSpd_Target2_StatusValue0}, provided-interface=TI_SPD_Target2_Status
      pp_SPD_Target_Status: nonqueued-sender-com-spec{data-element=Spd_Target_Status, init-value=constant-reference=Mdl_SpeedSpd_Target_StatusValue0}, provided-interface=TI_SPD_Target_Status
      pp_SPD_Trim2_Status: nonqueued-sender-com-spec{data-element=Spd_Trim2_Status, init-value=constant-reference=Mdl_SpeedSpd_Trim2_StatusValue0}, provided-interface=TI_SPD_Trim2_Status
      pp_SPD_Trim_Status: nonqueued-sender-com-spec{data-element=Spd_Trim_Status, init-value=constant-reference=Mdl_SpeedSpd_Trim_StatusValue0}, provided-interface=TI_SPD_Trim_Status
    10 x require port:
      rpIgnSubstate: nonqueued-receiver-com-spec{data-element=IgnitionSubstate, init-value=constant-reference=Mdl_SpeedIgnitionSubstateValue0}, required-interface=TI_WSS_IgnitionSubstate
      rpIoHwAb_ADC: required-interface=TI_IOHWAB_GetAdc
      rp_CS_CanRx: required-interface=if_CS_ComAbsRx
      rp_CS_LinerInterpolation: required-interface=TI_CS_LinearInterpolation
      rp_CS_MemAbsGet: required-interface=if_CS_MemAbsGet
      rp_ClusterMode: nonqueued-receiver-com-spec{data-element=WSSCurrentClusterMode, init-value=constant-reference=Mdl_SpeedWSSCurrentClusterModeValue0}, required-interface=TI_WSS_ClusterMode
      rp_Countrycode_Func: nonqueued-receiver-com-spec{data-element=CountryCode_Func, init-value=constant-reference=Mdl_SpeedCountryCode_FuncValue0}, required-interface=TI_SR_CountryCode_Func
      rp_Dcm_appStop: nonqueued-receiver-com-spec{data-element=AppId, init-value=constant-reference=Mdl_SpeedAppIdValue0}, required-interface=TI_SR_Dcm_AppStopNotification
      rp_Diag_Digitalspeed: nonqueued-receiver-com-spec{data-element=Diag_Digital_Speed_Value, init-value=constant-reference=Mdl_SpeedDiag_Digital_Speed_ValueValue0}, required-interface=TI_SR_Diag_Display_speed_Value
      rp_DispDistanceUnit: nonqueued-receiver-com-spec{data-element=DisplayUnit, init-value=constant-reference=Mdl_SpeedDisplayUnitValue0}, required-interface=TI_SR_Meter_DisplayDistanceUnit
    behavior IB_Mdl_Speed
      operation invoked event OIE_pp_Init_Mdl_Speed_InitTrigByInit: start-on-event=Mdl_Speed_Init, operation=pp_Init.Init
      timing event TEMdl_Speed_Task: start-on-event=Mdl_Speed_Task, period=0.02
      port-api-options:
        enable-take-address=false, indirect-api=false, port=Mdl_Speed/pp_Init
        enable-take-address=false, indirect-api=false, port=pp_SPD_SP1_In_Status
        enable-take-address=false, indirect-api=false, port=pp_SPD_Selection_Table
        enable-take-address=false, indirect-api=false, port=pp_SPD_Target2_Status
        enable-take-address=false, indirect-api=false, port=pp_SPD_Target_Status
        enable-take-address=false, indirect-api=false, port=pp_SPD_Trim2_Status
        enable-take-address=false, indirect-api=false, port=pp_SPD_Trim_Status
        enable-take-address=false, indirect-api=false, port=Mdl_Speed/rpIgnSubstate
        enable-take-address=false, indirect-api=false, port=Mdl_Speed/rpIoHwAb_ADC
        enable-take-address=false, indirect-api=false, port=Mdl_Speed/rp_CS_CanRx
        enable-take-address=false, indirect-api=false, port=rp_CS_LinerInterpolation
        enable-take-address=false, indirect-api=false, port=Mdl_Speed/rp_CS_MemAbsGet
        enable-take-address=false, indirect-api=false, port=Mdl_Speed/rp_ClusterMode
        enable-take-address=false, indirect-api=false, port=Mdl_Speed/rp_Countrycode_Func
        enable-take-address=false, indirect-api=false, port=Mdl_Speed/rp_Dcm_appStop
        enable-take-address=false, indirect-api=false, port=Mdl_Speed/rp_Diag_Digitalspeed
        enable-take-address=false, indirect-api=false, port=Mdl_Speed/rp_DispDistanceUnit
      runnable Mdl_Speed_Init: can-be-invoked-concurrently=true
      runnable Mdl_Speed_Task: can-be-invoked-concurrently=true
        data-receive-point-by-arguments:
          6 x access:
            DRA_rpIgnSubstate_IgnitionSubstate: accessed-variable=rpIgnSubstate.IgnitionSubstate
            DRA_rp_ClusterMode_WSSCurrentClusterMode: accessed-variable=rp_ClusterMode.WSSCurrentClusterMode
            DRA_rp_Countrycode_Func_CountryCode_Func: accessed-variable=rp_Countrycode_Func.CountryCode_Func
            DRA_rp_Dcm_appStop_AppId: accessed-variable=rp_Dcm_appStop.AppId
            DRA_rp_Diag_Digitalspeed_Diag_Digital_Speed_Value: accessed-variable=rp_Diag_Digitalspeed.Diag_Digital_Speed_Value
            DRA_rp_DispDistanceUnit_DisplayUnit: accessed-variable=rp_DispDistanceUnit.DisplayUnit
        data-send-points:
          6 x access:
            DWA_pp_SPD_SP1_In_Status_SP1_In_Status: accessed-variable=pp_SPD_SP1_In_Status.SP1_In_Status
            DWA_pp_SPD_Selection_Table_Speed_Selection_Table: accessed-variable=pp_SPD_Selection_Table.Speed_Selection_Table
            DWA_pp_SPD_Target2_Status_Spd_Target2_Status: accessed-variable=pp_SPD_Target2_Status.Spd_Target2_Status
            DWA_pp_SPD_Target_Status_Spd_Target_Status: accessed-variable=pp_SPD_Target_Status.Spd_Target_Status
            DWA_pp_SPD_Trim2_Status_Spd_Trim2_Status: accessed-variable=pp_SPD_Trim2_Status.Spd_Trim2_Status
            DWA_pp_SPD_Trim_Status_Spd_Trim_Status: accessed-variable=pp_SPD_Trim_Status.Spd_Trim_Status
        111 x sync call, all with timeout=0.0:
          OA_rpIoHwAb_ADC_GetAsyncRawAdc: operation=rpIoHwAb_ADC.GetAsyncRawAdc
          OA_rpIoHwAb_ADC_GetSyncRawAdc: operation=rpIoHwAb_ADC.GetSyncRawAdc
          OA_rpIoHwAb_ADC_GetProcessedAdc: operation=rpIoHwAb_ADC.GetProcessedAdc
          OA_rp_CS_CanRx_RxCan_GetSignalValueU8Arr: operation=rp_CS_CanRx.RxCan_GetSignalValueU8Arr
          OA_rp_CS_CanRx_RxCan_SetSignalInitValue: operation=rp_CS_CanRx.RxCan_SetSignalInitValue
          OA_rp_CS_CanRx_RxCan_SetSignalInitValueU8Arr: operation=rp_CS_CanRx.RxCan_SetSignalInitValueU8Arr
          OA_rp_CS_CanRx_RxCan_SignalInvalidProcessingControl: operation=rp_CS_CanRx.RxCan_SignalInvalidProcessingControl
          OA_rp_CS_CanRx_RxCan_SignalMissingProcessingControl: operation=rp_CS_CanRx.RxCan_SignalMissingProcessingControl
          OA_rp_CS_CanRx_RxCan_SignalNRProcessingControl: operation=rp_CS_CanRx.RxCan_SignalNRProcessingControl
          OA_rp_CS_CanRx_RxCan_SignalGetJustRcvdStatus: operation=rp_CS_CanRx.RxCan_SignalGetJustRcvdStatus
          OA_rp_CS_CanRx_RxCan_SignalClearJustRcvdStatus: operation=rp_CS_CanRx.RxCan_SignalClearJustRcvdStatus
          OA_rp_CS_CanRx_RxCan_GetSignalValue: operation=rp_CS_CanRx.RxCan_GetSignalValue
          OA_rp_CS_LinerInterpolation_Get_LinearInterpolateWord: operation=rp_CS_LinerInterpolation.Get_LinearInterpolateWord
          OA_rp_CS_LinerInterpolation_Get_LinearInterpolateByte: operation=rp_CS_LinerInterpolation.Get_LinearInterpolateByte
          OA_rp_CS_LinerInterpolation_Get_LinearInterpolateSByte: operation=rp_CS_LinerInterpolation.Get_LinearInterpolateSByte
          OA_rp_CS_LinerInterpolation_Get_LinearInterpolateSWord: operation=rp_CS_LinerInterpolation.Get_LinearInterpolateSWord
          OA_rp_CS_MemAbsGet_Get_BsShare_SwUpdReflash_Element: operation=rp_CS_MemAbsGet.Get_BsShare_SwUpdReflash_Element
          OA_rp_CS_MemAbsGet_Get_BsShare_SwUpdFotaMode_Element: operation=rp_CS_MemAbsGet.Get_BsShare_SwUpdFotaMode_Element
          OA_rp_CS_MemAbsGet_Get_BsShare_SwUpdFotaFinPrint_Element: operation=rp_CS_MemAbsGet.Get_BsShare_SwUpdFotaFinPrint_Element
          OA_rp_CS_MemAbsGet_Get_BsShare_SwUpdFotaStatus_Element: operation=rp_CS_MemAbsGet.Get_BsShare_SwUpdFotaStatus_Element
          OA_rp_CS_MemAbsGet_Get_BsShare_SwUpdFotadecrypt_Element: operation=rp_CS_MemAbsGet.Get_BsShare_SwUpdFotadecrypt_Element
          OA_rp_CS_MemAbsGet_Get_BsShare_EcuPartNumber_Element: operation=rp_CS_MemAbsGet.Get_BsShare_EcuPartNumber_Element
          OA_rp_CS_MemAbsGet_Get_BsShare_VisteonPartNumber: operation=rp_CS_MemAbsGet.Get_BsShare_VisteonPartNumber
          OA_rp_CS_MemAbsGet_Get_BsShare_VisteonPCBPartNumber: operation=rp_CS_MemAbsGet.Get_BsShare_VisteonPCBPartNumber
          OA_rp_CS_MemAbsGet_Get_BsShare_ProductSerialNumber: operation=rp_CS_MemAbsGet.Get_BsShare_ProductSerialNumber
          OA_rp_CS_MemAbsGet_Get_BsShare_PCBSerialNumber: operation=rp_CS_MemAbsGet.Get_BsShare_PCBSerialNumber
          OA_rp_CS_MemAbsGet_Get_BsShare_SMTManufacturingDate: operation=rp_CS_MemAbsGet.Get_BsShare_SMTManufacturingDate
          OA_rp_CS_MemAbsGet_Get_BsShare_AssemblyManufacturingDate: operation=rp_CS_MemAbsGet.Get_BsShare_AssemblyManufacturingDate
          OA_rp_CS_MemAbsGet_Get_BsShare_SMTPlantNumber: operation=rp_CS_MemAbsGet.Get_BsShare_SMTPlantNumber
          OA_rp_CS_MemAbsGet_Get_BsShare_AssemblyPlantNumber: operation=rp_CS_MemAbsGet.Get_BsShare_AssemblyPlantNumber
          OA_rp_CS_MemAbsGet_Get_BsShare_HWModification: operation=rp_CS_MemAbsGet.Get_BsShare_HWModification
          OA_rp_CS_MemAbsGet_Get_BsShare_VisMeet_Element: operation=rp_CS_MemAbsGet.Get_BsShare_VisMeet_Element
          OA_rp_CS_MemAbsGet_Get_BsShare_VisMeet_EOLEntry_Element: operation=rp_CS_MemAbsGet.Get_BsShare_VisMeet_EOLEntry_Element
          OA_rp_CS_MemAbsGet_Get_BsShare_VehicleConfig_Element: operation=rp_CS_MemAbsGet.Get_BsShare_VehicleConfig_Element
          OA_rp_CS_MemAbsGet_Get_BsConst_SpeedoGauge_Element: operation=rp_CS_MemAbsGet.Get_BsConst_SpeedoGauge_Element
          OA_rp_CS_MemAbsGet_Get_BsConst_TachoGauge_Element: operation=rp_CS_MemAbsGet.Get_BsConst_TachoGauge_Element
          OA_rp_CS_MemAbsGet_Get_BsConst_FuelGauge_Element: operation=rp_CS_MemAbsGet.Get_BsConst_FuelGauge_Element
          OA_rp_CS_MemAbsGet_Get_BsConst_TempGauge_Element: operation=rp_CS_MemAbsGet.Get_BsConst_TempGauge_Element
          OA_rp_CS_MemAbsGet_Get_BsConst_PowerGauge_Element: operation=rp_CS_MemAbsGet.Get_BsConst_PowerGauge_Element
          OA_rp_CS_MemAbsGet_Get_BsConst_OilGauge_Element: operation=rp_CS_MemAbsGet.Get_BsConst_OilGauge_Element
          OA_rp_CS_MemAbsGet_Get_BsConst_TripComputer_Element: operation=rp_CS_MemAbsGet.Get_BsConst_TripComputer_Element
          OA_rp_CS_MemAbsGet_Get_BsConst_Compensation_Line_Slope_m: operation=rp_CS_MemAbsGet.Get_BsConst_Compensation_Line_Slope_m
          OA_rp_CS_MemAbsGet_Get_BsConst_Compensation_Line_Shift_b: operation=rp_CS_MemAbsGet.Get_BsConst_Compensation_Line_Shift_b
          OA_rp_CS_MemAbsGet_Get_BsConst_Lookup_Curve_HotSpot_Coef_X: operation=rp_CS_MemAbsGet.Get_BsConst_Lookup_Curve_HotSpot_Coef_X
          OA_rp_CS_MemAbsGet_Get_BsConst_Lookup_Curve_HotSpot_Coef_Y: operation=rp_CS_MemAbsGet.Get_BsConst_Lookup_Curve_HotSpot_Coef_Y
          OA_rp_CS_MemAbsGet_Get_BsConst_Temp_Threshold_Hysteresis_Derating: operation=rp_CS_MemAbsGet.Get_BsConst_Temp_Threshold_Hysteresis_Derating
          OA_rp_CS_MemAbsGet_Get_BsConst_Derating_Backlight_Disable: operation=rp_CS_MemAbsGet.Get_BsConst_Derating_Backlight_Disable
          OA_rp_CS_MemAbsGet_Get_BsConst_Temperature_Sensor_Conv: operation=rp_CS_MemAbsGet.Get_BsConst_Temperature_Sensor_Conv
          OA_rp_CS_MemAbsGet_Get_BsConst_PCB_Temperature_Sensor_Conv: operation=rp_CS_MemAbsGet.Get_BsConst_PCB_Temperature_Sensor_Conv
          OA_rp_CS_MemAbsGet_Get_BsConst_Display_Illum_Max_Level: operation=rp_CS_MemAbsGet.Get_BsConst_Display_Illum_Max_Level
          OA_rp_CS_MemAbsGet_Get_BsConst_PWM_boost_bypass_duty: operation=rp_CS_MemAbsGet.Get_BsConst_PWM_boost_bypass_duty
          OA_rp_CS_MemAbsGet_Get_BsConst_BsConst_Illumination_ReservedByte: operation=rp_CS_MemAbsGet.Get_BsConst_BsConst_Illumination_ReservedByte
          OA_rp_CS_MemAbsGet_Get_BsConst_Compensation_Line_Slope_m_SafeCopy1: operation=rp_CS_MemAbsGet.Get_BsConst_Compensation_Line_Slope_m_SafeCopy1
          OA_rp_CS_MemAbsGet_Get_BsConst_Compensation_Line_Shift_b_SafeCopy1: operation=rp_CS_MemAbsGet.Get_BsConst_Compensation_Line_Shift_b_SafeCopy1
          OA_rp_CS_MemAbsGet_Get_BsConst_Lookup_Curve_HotSpot_Coef_X_SafeCopy1: operation=rp_CS_MemAbsGet.Get_BsConst_Lookup_Curve_HotSpot_Coef_X_SafeCopy1
          OA_rp_CS_MemAbsGet_Get_BsConst_Lookup_Curve_HotSpot_Coef_Y_SafeCopy1: operation=rp_CS_MemAbsGet.Get_BsConst_Lookup_Curve_HotSpot_Coef_Y_SafeCopy1
          OA_rp_CS_MemAbsGet_Get_BsConst_Temp_Threshold_Hysteresis_Derating_SafeCopy1: operation=rp_CS_MemAbsGet.Get_BsConst_Temp_Threshold_Hysteresis_Derating_SafeCopy1
          OA_rp_CS_MemAbsGet_Get_BsConst_Derating_Backlight_Disable_SafeCopy1: operation=rp_CS_MemAbsGet.Get_BsConst_Derating_Backlight_Disable_SafeCopy1
          OA_rp_CS_MemAbsGet_Get_BsConst_Temperature_Sensor_Conv_SafeCopy1: operation=rp_CS_MemAbsGet.Get_BsConst_Temperature_Sensor_Conv_SafeCopy1
          OA_rp_CS_MemAbsGet_Get_BsConst_PCB_Temperature_Sensor_Conv_SafeCopy1: operation=rp_CS_MemAbsGet.Get_BsConst_PCB_Temperature_Sensor_Conv_SafeCopy1
          OA_rp_CS_MemAbsGet_Get_BsConst_Display_Illum_Max_Level_SafeCopy1: operation=rp_CS_MemAbsGet.Get_BsConst_Display_Illum_Max_Level_SafeCopy1
          OA_rp_CS_MemAbsGet_Get_BsConst_PWM_boost_bypass_duty_SafeCopy1: operation=rp_CS_MemAbsGet.Get_BsConst_PWM_boost_bypass_duty_SafeCopy1
          OA_rp_CS_MemAbsGet_Get_BsConst_BsConst_Illumination_ReservedByte_SafeCopy1: operation=rp_CS_MemAbsGet.Get_BsConst_BsConst_Illumination_ReservedByte_SafeCopy1
          OA_rp_CS_MemAbsGet_Get_BsConst_Compensation_Line_Slope_m_SafeCopy2: operation=rp_CS_MemAbsGet.Get_BsConst_Compensation_Line_Slope_m_SafeCopy2
          OA_rp_CS_MemAbsGet_Get_BsConst_Compensation_Line_Shift_b_SafeCopy2: operation=rp_CS_MemAbsGet.Get_BsConst_Compensation_Line_Shift_b_SafeCopy2
          OA_rp_CS_MemAbsGet_Get_BsConst_Lookup_Curve_HotSpot_Coef_X_SafeCopy2: operation=rp_CS_MemAbsGet.Get_BsConst_Lookup_Curve_HotSpot_Coef_X_SafeCopy2
          OA_rp_CS_MemAbsGet_Get_BsConst_Lookup_Curve_HotSpot_Coef_Y_SafeCopy2: operation=rp_CS_MemAbsGet.Get_BsConst_Lookup_Curve_HotSpot_Coef_Y_SafeCopy2
          OA_rp_CS_MemAbsGet_Get_BsConst_Temp_Threshold_Hysteresis_Derating_SafeCopy2: operation=rp_CS_MemAbsGet.Get_BsConst_Temp_Threshold_Hysteresis_Derating_SafeCopy2
          OA_rp_CS_MemAbsGet_Get_BsConst_Derating_Backlight_Disable_SafeCopy2: operation=rp_CS_MemAbsGet.Get_BsConst_Derating_Backlight_Disable_SafeCopy2
          OA_rp_CS_MemAbsGet_Get_BsConst_Temperature_Sensor_Conv_SafeCopy2: operation=rp_CS_MemAbsGet.Get_BsConst_Temperature_Sensor_Conv_SafeCopy2
          OA_rp_CS_MemAbsGet_Get_BsConst_PCB_Temperature_Sensor_Conv_SafeCopy2: operation=rp_CS_MemAbsGet.Get_BsConst_PCB_Temperature_Sensor_Conv_SafeCopy2
          OA_rp_CS_MemAbsGet_Get_BsConst_Display_Illum_Max_Level_SafeCopy2: operation=rp_CS_MemAbsGet.Get_BsConst_Display_Illum_Max_Level_SafeCopy2
          OA_rp_CS_MemAbsGet_Get_BsConst_PWM_boost_bypass_duty_SafeCopy2: operation=rp_CS_MemAbsGet.Get_BsConst_PWM_boost_bypass_duty_SafeCopy2
          OA_rp_CS_MemAbsGet_Get_BsConst_BsConst_Illumination_ReservedByte_SafeCopy2: operation=rp_CS_MemAbsGet.Get_BsConst_BsConst_Illumination_ReservedByte_SafeCopy2
          OA_rp_CS_MemAbsGet_Get_BsConst_Audio_Element: operation=rp_CS_MemAbsGet.Get_BsConst_Audio_Element
          OA_rp_CS_MemAbsGet_Get_BsConst_Warning_Element: operation=rp_CS_MemAbsGet.Get_BsConst_Warning_Element
          OA_rp_CS_MemAbsGet_Get_BsConst_RealTimeClock_Element: operation=rp_CS_MemAbsGet.Get_BsConst_RealTimeClock_Element
          OA_rp_CS_MemAbsGet_Get_BsConst_Communication_Element: operation=rp_CS_MemAbsGet.Get_BsConst_Communication_Element
          OA_rp_CS_MemAbsGet_Get_BsConst_Power_Element: operation=rp_CS_MemAbsGet.Get_BsConst_Power_Element
          OA_rp_CS_MemAbsGet_Get_BsConst_ServiceReminder_Element: operation=rp_CS_MemAbsGet.Get_BsConst_ServiceReminder_Element
          OA_rp_CS_MemAbsGet_Get_BsConst_EngOffTimer_Element: operation=rp_CS_MemAbsGet.Get_BsConst_EngOffTimer_Element
          OA_rp_CS_MemAbsGet_Get_BsCys_Certicificate_Element: operation=rp_CS_MemAbsGet.Get_BsCys_Certicificate_Element
          OA_rp_CS_MemAbsGet_Get_RefCys_Certicificate_Element: operation=rp_CS_MemAbsGet.Get_RefCys_Certicificate_Element
          OA_rp_CS_MemAbsGet_Get_RefCys_Certicificate1_Element: operation=rp_CS_MemAbsGet.Get_RefCys_Certicificate1_Element
          OA_rp_CS_MemAbsGet_Get_BsRt_Odometer_Element: operation=rp_CS_MemAbsGet.Get_BsRt_Odometer_Element
          OA_rp_CS_MemAbsGet_Get_BsRt_SpeedoGauge_Element: operation=rp_CS_MemAbsGet.Get_BsRt_SpeedoGauge_Element
          OA_rp_CS_MemAbsGet_Get_BsRt_TachoGauge_Element: operation=rp_CS_MemAbsGet.Get_BsRt_TachoGauge_Element
          OA_rp_CS_MemAbsGet_Get_BsRt_FuelGauge_Element: operation=rp_CS_MemAbsGet.Get_BsRt_FuelGauge_Element
          OA_rp_CS_MemAbsGet_Get_BsRt_TempGauge_Element: operation=rp_CS_MemAbsGet.Get_BsRt_TempGauge_Element
          OA_rp_CS_MemAbsGet_Get_BsRt_PowerGauge_Element: operation=rp_CS_MemAbsGet.Get_BsRt_PowerGauge_Element
          OA_rp_CS_MemAbsGet_Get_BsRt_OilGauge_Element: operation=rp_CS_MemAbsGet.Get_BsRt_OilGauge_Element
          OA_rp_CS_MemAbsGet_Get_BsRt_TripComputer_Element: operation=rp_CS_MemAbsGet.Get_BsRt_TripComputer_Element
          OA_rp_CS_MemAbsGet_Get_BsRt_Warning_Element: operation=rp_CS_MemAbsGet.Get_BsRt_Warning_Element
          OA_rp_CS_MemAbsGet_Get_BsRt_RealTimeClock_Element: operation=rp_CS_MemAbsGet.Get_BsRt_RealTimeClock_Element
          OA_rp_CS_MemAbsGet_Get_BsRt_Personalization_Element: operation=rp_CS_MemAbsGet.Get_BsRt_Personalization_Element
          OA_rp_CS_MemAbsGet_Get_BsRt_Illumination_Element: operation=rp_CS_MemAbsGet.Get_BsRt_Illumination_Element
          OA_rp_CS_MemAbsGet_Get_BsRt_CusDlt_Element: operation=rp_CS_MemAbsGet.Get_BsRt_CusDlt_Element
          OA_rp_CS_MemAbsGet_Get_BsReten_Odometer_Element: operation=rp_CS_MemAbsGet.Get_BsReten_Odometer_Element
          OA_rp_CS_MemAbsGet_Get_BsReten_Gauges_Element: operation=rp_CS_MemAbsGet.Get_BsReten_Gauges_Element
          OA_rp_CS_MemAbsGet_Get_BsReten_Tripcomputer_Element: operation=rp_CS_MemAbsGet.Get_BsReten_Tripcomputer_Element
          OA_rp_CS_MemAbsGet_Get_BsReten_Illumination_Element: operation=rp_CS_MemAbsGet.Get_BsReten_Illumination_Element
          OA_rp_CS_MemAbsGet_Get_BsReten_Audio_Element: operation=rp_CS_MemAbsGet.Get_BsReten_Audio_Element
          OA_rp_CS_MemAbsGet_Get_BsReten_Warning_Element: operation=rp_CS_MemAbsGet.Get_BsReten_Warning_Element
          OA_rp_CS_MemAbsGet_Get_BsReten_RealTimeClock_Element: operation=rp_CS_MemAbsGet.Get_BsReten_RealTimeClock_Element
          OA_rp_CS_MemAbsGet_Get_BsReten_Communication_Element: operation=rp_CS_MemAbsGet.Get_BsReten_Communication_Element
          OA_rp_CS_MemAbsGet_Get_BsReten_Personalization_Element: operation=rp_CS_MemAbsGet.Get_BsReten_Personalization_Element
          OA_rp_CS_MemAbsGet_Get_BsReten_VisDlt_Element: operation=rp_CS_MemAbsGet.Get_BsReten_VisDlt_Element
          OA_rp_CS_MemAbsGet_Get_BsReten_Power_Element: operation=rp_CS_MemAbsGet.Get_BsReten_Power_Element
          OA_rp_CS_MemAbsGet_Get_BsReten_Display_Element: operation=rp_CS_MemAbsGet.Get_BsReten_Display_Element
          OA_rp_CS_MemAbsGet_Get_BsDiag_ErrorRecord_Element: operation=rp_CS_MemAbsGet.Get_BsDiag_ErrorRecord_Element
          OA_rp_CS_MemAbsGet_Get_BsDiag_Dtc_Element: operation=rp_CS_MemAbsGet.Get_BsDiag_Dtc_Element
  12 x constant specification:
    Mdl_SpeedSP1_In_StatusValue0: value-spec=Mdl_SpeedSP1_In_StatusValue0:0
    Mdl_SpeedSpeed_Selection_TableValue0: value-spec=Mdl_SpeedSpeed_Selection_TableValue0:0
    Mdl_SpeedSpd_Target2_StatusValue0: value-spec=Mdl_SpeedSpd_Target2_StatusValue0:0
    Mdl_SpeedSpd_Target_StatusValue0: value-spec=Mdl_SpeedSpd_Target_StatusValue0:0
    Mdl_SpeedSpd_Trim2_StatusValue0: value-spec=Mdl_SpeedSpd_Trim2_StatusValue0:0
    Mdl_SpeedSpd_Trim_StatusValue0: value-spec=Mdl_SpeedSpd_Trim_StatusValue0:0
    Mdl_SpeedIgnitionSubstateValue0: value-spec=Mdl_SpeedIgnitionSubstateValue0:0
    Mdl_SpeedWSSCurrentClusterModeValue0: value-spec=Mdl_SpeedWSSCurrentClusterModeValue0:0
    Mdl_SpeedCountryCode_FuncValue0: value-spec=Mdl_SpeedCountryCode_FuncValue0:0
    Mdl_SpeedAppIdValue0: value-spec=Mdl_SpeedAppIdValue0:0
    Mdl_SpeedDiag_Digital_Speed_ValueValue0: value-spec=Mdl_SpeedDiag_Digital_Speed_ValueValue0:0
    Mdl_SpeedDisplayUnitValue0: value-spec=Mdl_SpeedDisplayUnitValue0:0
  swc implementation IMPL_Mdl_Speed: programming-language=C, behavior=IB_Mdl_Speed
    code-descriptors:
      code CodeDescriptor
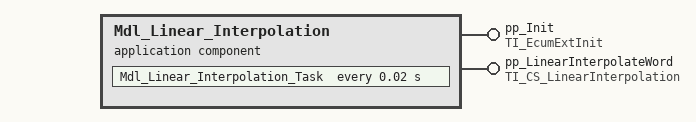
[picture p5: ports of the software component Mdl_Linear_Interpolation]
  application sw component type Mdl_Linear_Interpolation
    provide port pp_Init: server-com-spec{operation=TI_EcumExtInit/Init, queue-length=1}, provided-interface=TI_EcumExtInit
    provide port pp_LinearInterpolateWord: provided-interface=TI_CS_LinearInterpolation
      provided-com-specs:
        operation=Get_LinearInterpolateByte, queue-length=1
        operation=Get_LinearInterpolateSByte, queue-length=1
        operation=Get_LinearInterpolateSWord, queue-length=1
        operation=Get_LinearInterpolateWord, queue-length=1
    behavior IB_Mdl_Linear_Interpolation
      5 x operation invoked event:
        OIE_pp_LinearInterpolateWord_Mdl_Linear_Interpolation_Get_LinearInterpolateByteTrigByGet_LinearInterpolateByte: start-on-event=Mdl_Linear_Interpolation_Get_LinearInterpolateByte, operation=pp_LinearInterpolateWord.Get_LinearInterpolateByte
        OIE_pp_LinearInterpolateWord_Mdl_Linear_Interpolation_Get_LinearInterpolateSByteTrigByGet_LinearInterpolateSByte: start-on-event=Mdl_Linear_Interpolation_Get_LinearInterpolateSByte, operation=pp_LinearInterpolateWord.Get_LinearInterpolateSByte
        OIE_pp_LinearInterpolateWord_Mdl_Linear_Interpolation_Get_LinearInterpolateSWordTrigByGet_LinearInterpolateSWord: start-on-event=Mdl_Linear_Interpolation_Get_LinearInterpolateSWord, operation=pp_LinearInterpolateWord.Get_LinearInterpolateSWord
        OIE_pp_LinearInterpolateWord_Mdl_Linear_Interpolation_Get_LinearInterpolateWordTrigByGet_LinearInterpolateWord: start-on-event=Mdl_Linear_Interpolation_Get_LinearInterpolateWord, operation=pp_LinearInterpolateWord.Get_LinearInterpolateWord
        OIE_pp_Init_Mdl_Linear_Interpolation_InitTrigByInit: start-on-event=Mdl_Linear_Interpolation_Init, operation=pp_Init.Init
      timing event TEMdl_Linear_Interpolation_Task: start-on-event=Mdl_Linear_Interpolation_Task, period=0.02
      port-api-options:
        enable-take-address=false, indirect-api=false, port=Mdl_Linear_Interpolation/pp_Init
        enable-take-address=false, indirect-api=false, port=pp_LinearInterpolateWord
      6 x runnable, all with can-be-invoked-concurrently=true:
        Mdl_Linear_Interpolation_Get_LinearInterpolateByte
        Mdl_Linear_Interpolation_Get_LinearInterpolateSByte
        Mdl_Linear_Interpolation_Get_LinearInterpolateSWord
        Mdl_Linear_Interpolation_Get_LinearInterpolateWord
        Mdl_Linear_Interpolation_Init
        Mdl_Linear_Interpolation_Task
  swc implementation IMPL_Mdl_Linear_Interpolation: programming-language=C, behavior=IB_Mdl_Linear_Interpolation
    code-descriptors:
      code CodeDescriptor
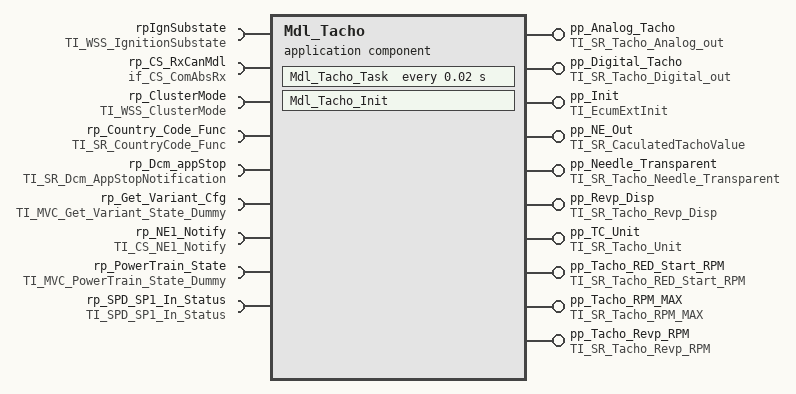
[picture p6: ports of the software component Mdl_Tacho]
  application sw component type Mdl_Tacho
    10 x provide port:
      pp_Analog_Tacho: nonqueued-sender-com-spec{data-element=Analog_Tacho, init-value=constant-reference=Mdl_TachoAnalog_TachoValue0}, provided-interface=TI_SR_Tacho_Analog_out
      pp_Digital_Tacho: nonqueued-sender-com-spec{data-element=Digital_Tacho, init-value=constant-reference=Mdl_TachoDigital_TachoValue0}, provided-interface=TI_SR_Tacho_Digital_out
      pp_Init: server-com-spec{operation=TI_EcumExtInit/Init, queue-length=1}, provided-interface=TI_EcumExtInit
      pp_NE_Out: nonqueued-sender-com-spec{data-element=CalTachoValue, init-value=constant-reference=Mdl_TachoCalTachoValueValue0}, provided-interface=TI_SR_CaculatedTachoValue
      pp_Needle_Transparent: nonqueued-sender-com-spec{data-element=Needle_TR, init-value=constant-reference=Mdl_TachoNeedle_TRValue0}, provided-interface=TI_SR_Tacho_Needle_Transparent
      pp_Revp_Disp: nonqueued-sender-com-spec{data-element=REVP_DISP, uses-end-to-end-protection=0, init-value=constant-reference=Mdl_TachoREVP_DISPValue0}, provided-interface=TI_SR_Tacho_Revp_Disp
      pp_TC_Unit: nonqueued-sender-com-spec{data-element=Digital_TachoUnit, uses-end-to-end-protection=0, init-value=constant-reference=Mdl_TachoDigital_TachoUnitValue0}, provided-interface=TI_SR_Tacho_Unit
      pp_Tacho_RED_Start_RPM: nonqueued-sender-com-spec{data-element=RED_Start_RPM, init-value=constant-reference=Mdl_TachoRED_Start_RPMValue0}, provided-interface=TI_SR_Tacho_RED_Start_RPM
      pp_Tacho_RPM_MAX: nonqueued-sender-com-spec{data-element=REVP_RPM_MAX, init-value=constant-reference=Mdl_TachoREVP_RPM_MAXValue0}, provided-interface=TI_SR_Tacho_RPM_MAX
      pp_Tacho_Revp_RPM: nonqueued-sender-com-spec{data-element=REVP_RPM, init-value=constant-reference=Mdl_TachoREVP_RPMValue0}, provided-interface=TI_SR_Tacho_Revp_RPM
    9 x require port:
      rpIgnSubstate: nonqueued-receiver-com-spec{data-element=IgnitionSubstate, init-value=constant-reference=Mdl_TachoIgnitionSubstateValue0}, required-interface=TI_WSS_IgnitionSubstate
      rp_CS_RxCanMdl: required-interface=if_CS_ComAbsRx
      rp_ClusterMode: nonqueued-receiver-com-spec{data-element=WSSCurrentClusterMode, init-value=constant-reference=Mdl_TachoWSSCurrentClusterModeValue0}, required-interface=TI_WSS_ClusterMode
      rp_Country_Code_Func: nonqueued-receiver-com-spec{data-element=CountryCode_Func, init-value=constant-reference=Mdl_TachoCountryCode_FuncValue0}, required-interface=TI_SR_CountryCode_Func
      rp_Dcm_appStop: nonqueued-receiver-com-spec{data-element=AppId, init-value=constant-reference=Mdl_TachoAppIdValue0}, required-interface=TI_SR_Dcm_AppStopNotification
      rp_Get_Variant_Cfg: required-interface=TI_MVC_Get_Variant_State_Dummy
      rp_NE1_Notify: required-interface=TI_CS_NE1_Notify
      rp_PowerTrain_State: nonqueued-receiver-com-spec{data-element=PowerTrain_Flag, init-value=constant-reference=Mdl_TachoPowerTrain_FlagValue0}, required-interface=TI_MVC_PowerTrain_State_Dummy
      rp_SPD_SP1_In_Status: nonqueued-receiver-com-spec{data-element=SP1_In_Status, init-value=constant-reference=Mdl_TachoSP1_In_StatusValue0}, required-interface=TI_SPD_SP1_In_Status
    behavior IB_Mdl_Tacho
      operation invoked event OIE_pp_Init_Mdl_Tacho_InitTrigByInit: start-on-event=Mdl_Tacho_Init, operation=pp_Init.Init
      timing event TEMdl_Tacho_Task: start-on-event=Mdl_Tacho_Task, period=0.02
      port-api-options:
        enable-take-address=false, indirect-api=false, port=pp_Analog_Tacho
        enable-take-address=false, indirect-api=false, port=pp_Digital_Tacho
        enable-take-address=false, indirect-api=false, port=Mdl_Tacho/pp_Init
        enable-take-address=false, indirect-api=false, port=pp_NE_Out
        enable-take-address=false, indirect-api=false, port=pp_Needle_Transparent
        enable-take-address=false, indirect-api=false, port=pp_Revp_Disp
        enable-take-address=false, indirect-api=false, port=pp_TC_Unit
        enable-take-address=false, indirect-api=false, port=pp_Tacho_RED_Start_RPM
        enable-take-address=false, indirect-api=false, port=pp_Tacho_RPM_MAX
        enable-take-address=false, indirect-api=false, port=pp_Tacho_Revp_RPM
        enable-take-address=false, indirect-api=false, port=Mdl_Tacho/rpIgnSubstate
        enable-take-address=false, indirect-api=false, port=Mdl_Tacho/rp_CS_RxCanMdl
        enable-take-address=false, indirect-api=false, port=Mdl_Tacho/rp_ClusterMode
        enable-take-address=false, indirect-api=false, port=rp_Country_Code_Func
        enable-take-address=false, indirect-api=false, port=Mdl_Tacho/rp_Dcm_appStop
        enable-take-address=false, indirect-api=false, port=Mdl_Tacho/rp_Get_Variant_Cfg
        enable-take-address=false, indirect-api=false, port=rp_NE1_Notify
        enable-take-address=false, indirect-api=false, port=Mdl_Tacho/rp_PowerTrain_State
        enable-take-address=false, indirect-api=false, port=Mdl_Tacho/rp_SPD_SP1_In_Status
      runnable Mdl_Tacho_Init: can-be-invoked-concurrently=true
      runnable Mdl_Tacho_Task: can-be-invoked-concurrently=true
        data-receive-point-by-arguments:
          6 x access:
            DRA_rpIgnSubstate_IgnitionSubstate: accessed-variable=rpIgnSubstate.IgnitionSubstate
            DRA_rp_ClusterMode_WSSCurrentClusterMode: accessed-variable=rp_ClusterMode.WSSCurrentClusterMode
            DRA_rp_Country_Code_Func_CountryCode_Func: accessed-variable=rp_Country_Code_Func.CountryCode_Func
            DRA_rp_Dcm_appStop_AppId: accessed-variable=rp_Dcm_appStop.AppId
            DRA_rp_PowerTrain_State_PowerTrain_Flag: accessed-variable=rp_PowerTrain_State.PowerTrain_Flag
            DRA_rp_SPD_SP1_In_Status_SP1_In_Status: accessed-variable=rp_SPD_SP1_In_Status.SP1_In_Status
        data-send-points:
          9 x access:
            DWA_pp_Analog_Tacho_Analog_Tacho: accessed-variable=pp_Analog_Tacho.Analog_Tacho
            DWA_pp_Digital_Tacho_Digital_Tacho: accessed-variable=pp_Digital_Tacho.Digital_Tacho
            DWA_pp_NE_Out_CalTachoValue: accessed-variable=pp_NE_Out.CalTachoValue
            DWA_pp_Needle_Transparent_Needle_TR: accessed-variable=pp_Needle_Transparent.Needle_TR
            DWA_pp_Revp_Disp_REVP_DISP: accessed-variable=pp_Revp_Disp.REVP_DISP
            DWA_pp_TC_Unit_Digital_TachoUnit: accessed-variable=pp_TC_Unit.Digital_TachoUnit
            DWA_pp_Tacho_RED_Start_RPM_RED_Start_RPM: accessed-variable=pp_Tacho_RED_Start_RPM.RED_Start_RPM
            DWA_pp_Tacho_RPM_MAX_REVP_RPM_MAX: accessed-variable=pp_Tacho_RPM_MAX.REVP_RPM_MAX
            DWA_pp_Tacho_Revp_RPM_REVP_RPM: accessed-variable=pp_Tacho_Revp_RPM.REVP_RPM
        11 x sync call, all with timeout=0.0:
          OA_rp_CS_RxCanMdl_RxCan_GetSignalValueU8Arr: operation=rp_CS_RxCanMdl.RxCan_GetSignalValueU8Arr
          OA_rp_CS_RxCanMdl_RxCan_SetSignalInitValue: operation=rp_CS_RxCanMdl.RxCan_SetSignalInitValue
          OA_rp_CS_RxCanMdl_RxCan_SetSignalInitValueU8Arr: operation=rp_CS_RxCanMdl.RxCan_SetSignalInitValueU8Arr
          OA_rp_CS_RxCanMdl_RxCan_SignalInvalidProcessingControl: operation=rp_CS_RxCanMdl.RxCan_SignalInvalidProcessingControl
          OA_rp_CS_RxCanMdl_RxCan_SignalMissingProcessingControl: operation=rp_CS_RxCanMdl.RxCan_SignalMissingProcessingControl
          OA_rp_CS_RxCanMdl_RxCan_SignalNRProcessingControl: operation=rp_CS_RxCanMdl.RxCan_SignalNRProcessingControl
          OA_rp_CS_RxCanMdl_RxCan_SignalGetJustRcvdStatus: operation=rp_CS_RxCanMdl.RxCan_SignalGetJustRcvdStatus
          OA_rp_CS_RxCanMdl_RxCan_SignalClearJustRcvdStatus: operation=rp_CS_RxCanMdl.RxCan_SignalClearJustRcvdStatus
          OA_rp_CS_RxCanMdl_RxCan_GetSignalValue: operation=rp_CS_RxCanMdl.RxCan_GetSignalValue
          OA_rp_Get_Variant_Cfg_Get_Variant_Config_State: operation=rp_Get_Variant_Cfg.Get_Variant_Config_State
          OA_rp_NE1_Notify_NE1_Recieve_Notify_Value: operation=rp_NE1_Notify.NE1_Recieve_Notify_Value
  15 x constant specification:
    Mdl_TachoAnalog_TachoValue0: value-spec=Mdl_TachoAnalog_TachoValue0:0
    Mdl_TachoDigital_TachoValue0: value-spec=Mdl_TachoDigital_TachoValue0:0
    Mdl_TachoCalTachoValueValue0: value-spec=Mdl_TachoCalTachoValueValue0:0
    Mdl_TachoNeedle_TRValue0: value-spec=Mdl_TachoNeedle_TRValue0:0
    Mdl_TachoREVP_DISPValue0: value-spec=Mdl_TachoREVP_DISPValue0:false
    Mdl_TachoDigital_TachoUnitValue0: value-spec=Mdl_TachoDigital_TachoUnitValue0:false
    Mdl_TachoRED_Start_RPMValue0: value-spec=Mdl_TachoRED_Start_RPMValue0:0
    Mdl_TachoREVP_RPM_MAXValue0: value-spec=Mdl_TachoREVP_RPM_MAXValue0:0
    Mdl_TachoREVP_RPMValue0: value-spec=Mdl_TachoREVP_RPMValue0:0
    Mdl_TachoIgnitionSubstateValue0: value-spec=Mdl_TachoIgnitionSubstateValue0:0
    Mdl_TachoWSSCurrentClusterModeValue0: value-spec=Mdl_TachoWSSCurrentClusterModeValue0:0
    Mdl_TachoCountryCode_FuncValue0: value-spec=Mdl_TachoCountryCode_FuncValue0:0
    Mdl_TachoAppIdValue0: value-spec=Mdl_TachoAppIdValue0:0
    Mdl_TachoPowerTrain_FlagValue0: value-spec=Mdl_TachoPowerTrain_FlagValue0:0
    Mdl_TachoSP1_In_StatusValue0: value-spec=Mdl_TachoSP1_In_StatusValue0:0
  swc implementation IMPL_Mdl_Tacho: programming-language=C, behavior=IB_Mdl_Tacho
    code-descriptors:
      code CodeDescriptor
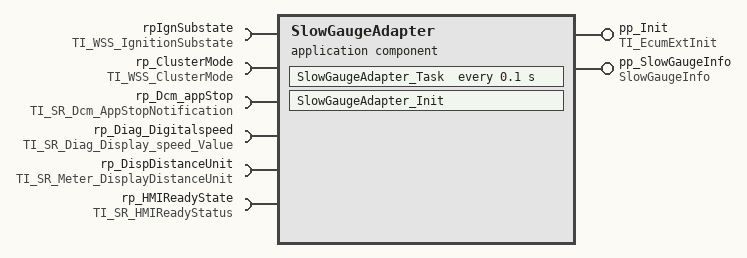
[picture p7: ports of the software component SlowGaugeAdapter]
  application sw component type SlowGaugeAdapter
    provide port pp_Init: server-com-spec{operation=TI_EcumExtInit/Init, queue-length=1}, provided-interface=TI_EcumExtInit
    provide port pp_SlowGaugeInfo: nonqueued-sender-com-spec{data-element=SlowGaugeInfoData, init-value=constant-reference=SlowGaugeAdapterSlowGaugeInfoDataValue0}, provided-interface=SlowGaugeInfo
    6 x require port:
      rpIgnSubstate: nonqueued-receiver-com-spec{data-element=IgnitionSubstate, init-value=constant-reference=SlowGaugeAdapterIgnitionSubstateValue0}, required-interface=TI_WSS_IgnitionSubstate
      rp_ClusterMode: nonqueued-receiver-com-spec{data-element=WSSCurrentClusterMode, init-value=constant-reference=SlowGaugeAdapterWSSCurrentClusterModeValue0}, required-interface=TI_WSS_ClusterMode
      rp_Dcm_appStop: nonqueued-receiver-com-spec{data-element=AppId, init-value=constant-reference=SlowGaugeAdapterAppIdValue0}, required-interface=TI_SR_Dcm_AppStopNotification
      rp_Diag_Digitalspeed: nonqueued-receiver-com-spec{data-element=Diag_Digital_Speed_Value, init-value=constant-reference=SlowGaugeAdapterDiag_Digital_Speed_ValueValue0}, required-interface=TI_SR_Diag_Display_speed_Value
      rp_DispDistanceUnit: nonqueued-receiver-com-spec{data-element=DisplayUnit, init-value=constant-reference=SlowGaugeAdapterDisplayUnitValue0}, required-interface=TI_SR_Meter_DisplayDistanceUnit
      rp_HMIReadyState: nonqueued-receiver-com-spec{data-element=HMI_ReadyStatus, init-value=constant-reference=SlowGaugeAdapterHMI_ReadyStatusValue0}, required-interface=TI_SR_HMIReadyStatus
    behavior IB_SlowGaugeAdapter
      operation invoked event OIE_pp_Init_SlowGaugeAdapter_InitTrigByInit: start-on-event=SlowGaugeAdapter_Init, operation=pp_Init.Init
      timing event TESlowGaugeAdapter_Task: start-on-event=SlowGaugeAdapter_Task, period=0.1
      port-api-options:
        enable-take-address=false, indirect-api=false, port=SlowGaugeAdapter/pp_Init
        enable-take-address=false, indirect-api=false, port=pp_SlowGaugeInfo
        enable-take-address=false, indirect-api=false, port=SlowGaugeAdapter/rpIgnSubstate
        enable-take-address=false, indirect-api=false, port=SlowGaugeAdapter/rp_ClusterMode
        enable-take-address=false, indirect-api=false, port=SlowGaugeAdapter/rp_Dcm_appStop
        enable-take-address=false, indirect-api=false, port=SlowGaugeAdapter/rp_Diag_Digitalspeed
        enable-take-address=false, indirect-api=false, port=SlowGaugeAdapter/rp_DispDistanceUnit
        enable-take-address=false, indirect-api=false, port=SlowGaugeAdapter/rp_HMIReadyState
      runnable SlowGaugeAdapter_Init: can-be-invoked-concurrently=true
      runnable SlowGaugeAdapter_Task: can-be-invoked-concurrently=true
        data-receive-point-by-arguments:
          6 x access:
            DRA_rpIgnSubstate_IgnitionSubstate: accessed-variable=rpIgnSubstate.IgnitionSubstate
            DRA_rp_ClusterMode_WSSCurrentClusterMode: accessed-variable=rp_ClusterMode.WSSCurrentClusterMode
            DRA_rp_Dcm_appStop_AppId: accessed-variable=rp_Dcm_appStop.AppId
            DRA_rp_Diag_Digitalspeed_Diag_Digital_Speed_Value: accessed-variable=rp_Diag_Digitalspeed.Diag_Digital_Speed_Value
            DRA_rp_DispDistanceUnit_DisplayUnit: accessed-variable=rp_DispDistanceUnit.DisplayUnit
            DRA_rp_HMIReadyState_HMI_ReadyStatus: accessed-variable=rp_HMIReadyState.HMI_ReadyStatus
        data-send-points:
          access DWA_pp_SlowGaugeInfo_SlowGaugeInfoData: accessed-variable=pp_SlowGaugeInfo.SlowGaugeInfoData
  7 x constant specification:
    SlowGaugeAdapterSlowGaugeInfoDataValue0: value-spec={short-label=SlowGaugeAdapterSlowGaugeInfoDataValue0, fields={short-label=SlowGaugeAdapterSlowGaugeInfoDataValue_0, fields=[SlowGaugeAdaptergaugeInfoValue_0:0, SlowGaugeAdaptergaugeInfoValue_1:0, SlowGaugeAdaptergaugeInfoValue_2:0, SlowGaugeAdaptergaugeInfoValue_3:0, SlowGaugeAdaptergaugeInfoValue_4:0]}}
    SlowGaugeAdapterIgnitionSubstateValue0: value-spec=SlowGaugeAdapterIgnitionSubstateValue0:0
    SlowGaugeAdapterWSSCurrentClusterModeValue0: value-spec=SlowGaugeAdapterWSSCurrentClusterModeValue0:0
    SlowGaugeAdapterAppIdValue0: value-spec=SlowGaugeAdapterAppIdValue0:0
    SlowGaugeAdapterDiag_Digital_Speed_ValueValue0: value-spec=SlowGaugeAdapterDiag_Digital_Speed_ValueValue0:0
    SlowGaugeAdapterDisplayUnitValue0: value-spec=SlowGaugeAdapterDisplayUnitValue0:0
    SlowGaugeAdapterHMI_ReadyStatusValue0: value-spec=SlowGaugeAdapterHMI_ReadyStatusValue0:0
  swc implementation IMPL_SlowGaugeAdapter: programming-language=C, behavior=IB_SlowGaugeAdapter
    code-descriptors:
      code CodeDescriptor
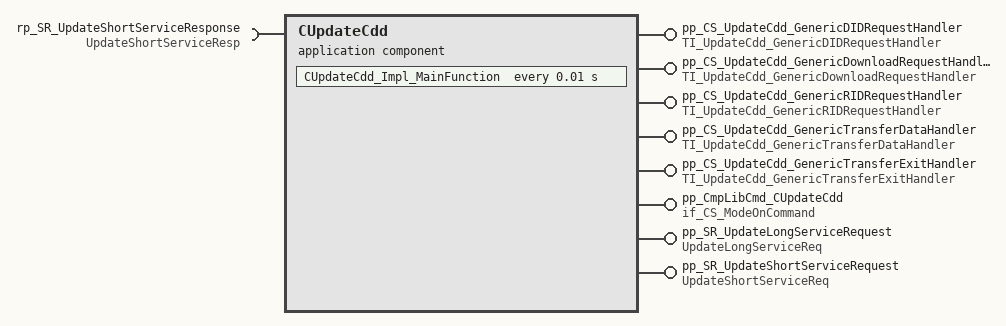
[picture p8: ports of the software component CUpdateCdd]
  application sw component type CUpdateCdd
    8 x provide port:
      pp_CS_UpdateCdd_GenericDIDRequestHandler: server-com-spec{operation=UpdateCdd_GenericDIDRequestHandler, queue-length=1}, provided-interface=TI_UpdateCdd_GenericDIDRequestHandler
      pp_CS_UpdateCdd_GenericDownloadRequestHandler: server-com-spec{operation=UpdateCdd_GenericDownloadRequestHandler, queue-length=1}, provided-interface=TI_UpdateCdd_GenericDownloadRequestHandler
      pp_CS_UpdateCdd_GenericRIDRequestHandler: server-com-spec{operation=UpdateCdd_GenericRIDRequestHandler, queue-length=1}, provided-interface=TI_UpdateCdd_GenericRIDRequestHandler
      pp_CS_UpdateCdd_GenericTransferDataHandler: server-com-spec{operation=UpdateCdd_GenericTransferDataHandler, queue-length=1}, provided-interface=TI_UpdateCdd_GenericTransferDataHandler
      pp_CS_UpdateCdd_GenericTransferExitHandler: server-com-spec{operation=UpdateCdd_GenericTransferExitHandler, queue-length=1}, provided-interface=TI_UpdateCdd_GenericTransferExitHandler
      pp_CmpLibCmd_CUpdateCdd: server-com-spec{operation=Impl_OnCommand, queue-length=1}, provided-interface=if_CS_ModeOnCommand
      pp_SR_UpdateLongServiceRequest: nonqueued-sender-com-spec{data-element=UpdateLongServiceReqData, init-value=constant-reference=CUpdateCddUpdateLongServiceReqDataValue0}, provided-interface=UpdateLongServiceReq
      pp_SR_UpdateShortServiceRequest: nonqueued-sender-com-spec{data-element=UpdateShortServiceReqData, init-value=constant-reference=CUpdateCddUpdateShortServiceReqDataValue0}, provided-interface=UpdateShortServiceReq
    require port rp_SR_UpdateShortServiceResponse: nonqueued-receiver-com-spec{data-element=UpdateShortServiceRespData, init-value=constant-reference=CUpdateCddUpdateShortServiceRespDataValue0}, required-interface=UpdateShortServiceResp
    behavior IB_CUpdateCdd
      timing event TECUpdateCdd_Impl_MainFunction: start-on-event=CUpdateCdd_Impl_MainFunction, period=0.01
      6 x operation invoked event:
        OIE_pp_CmpLibCmd_CUpdateCdd_CUpdateCdd_Impl_OnCommandTrigByImpl_OnCommand: start-on-event=CUpdateCdd_Impl_OnCommand, operation=pp_CmpLibCmd_CUpdateCdd.Impl_OnCommand
        OperationInvokeEvent_105: start-on-event=CUpdateCdd_UpdateCdd_GenericDIDRequestHandler, operation=pp_CS_UpdateCdd_GenericDIDRequestHandler.UpdateCdd_GenericDIDRequestHandler
        OperationInvokeEvent_106: start-on-event=CUpdateCdd_UpdateCdd_GenericDownloadRequestHandler, operation=pp_CS_UpdateCdd_GenericDownloadRequestHandler.UpdateCdd_GenericDownloadRequestHandler
        OperationInvokeEvent_107: start-on-event=CUpdateCdd_UpdateCdd_GenericRIDRequestHandler, operation=pp_CS_UpdateCdd_GenericRIDRequestHandler.UpdateCdd_GenericRIDRequestHandler
        OperationInvokeEvent_108: start-on-event=CUpdateCdd_UpdateCdd_GenericTransferDataHandler, operation=pp_CS_UpdateCdd_GenericTransferDataHandler.UpdateCdd_GenericTransferDataHandler
        OperationInvokeEvent_109: start-on-event=CUpdateCdd_UpdateCdd_GenericTransferExitHandler, operation=pp_CS_UpdateCdd_GenericTransferExitHandler.UpdateCdd_GenericTransferExitHandler
      port-api-options:
        enable-take-address=false, indirect-api=false, port=pp_CS_UpdateCdd_GenericDIDRequestHandler
        enable-take-address=false, indirect-api=false, port=pp_CS_UpdateCdd_GenericDownloadRequestHandler
        enable-take-address=false, indirect-api=false, port=pp_CS_UpdateCdd_GenericRIDRequestHandler
        enable-take-address=false, indirect-api=false, port=pp_CS_UpdateCdd_GenericTransferDataHandler
        enable-take-address=false, indirect-api=false, port=pp_CS_UpdateCdd_GenericTransferExitHandler
        enable-take-address=false, indirect-api=false, port=pp_CmpLibCmd_CUpdateCdd
        enable-take-address=false, indirect-api=false, port=pp_SR_UpdateLongServiceRequest
        enable-take-address=false, indirect-api=false, port=pp_SR_UpdateShortServiceRequest
        enable-take-address=false, indirect-api=false, port=rp_SR_UpdateShortServiceResponse
      7 x runnable, all with can-be-invoked-concurrently=true:
        CUpdateCdd_Impl_MainFunction
          data-receive-point-by-arguments:
            access DRA_rp_SR_UpdateShortServiceResponse_UpdateShortServiceRespData: accessed-variable=rp_SR_UpdateShortServiceResponse.UpdateShortServiceRespData
          data-send-points:
            access DWA_pp_SR_UpdateLongServiceRequest_UpdateLongServiceReqData: accessed-variable=pp_SR_UpdateLongServiceRequest.UpdateLongServiceReqData
            access DWA_pp_SR_UpdateShortServiceRequest_UpdateShortServiceReqData: accessed-variable=pp_SR_UpdateShortServiceRequest.UpdateShortServiceReqData
        CUpdateCdd_Impl_OnCommand
          data-receive-point-by-arguments:
            access DRA_rp_SR_UpdateShortServiceResponse_UpdateShortServiceRespData: accessed-variable=rp_SR_UpdateShortServiceResponse.UpdateShortServiceRespData
          data-send-points:
            access DWA_pp_SR_UpdateLongServiceRequest_UpdateLongServiceReqData: accessed-variable=pp_SR_UpdateLongServiceRequest.UpdateLongServiceReqData
            access DWA_pp_SR_UpdateShortServiceRequest_UpdateShortServiceReqData: accessed-variable=pp_SR_UpdateShortServiceRequest.UpdateShortServiceReqData
        CUpdateCdd_UpdateCdd_GenericDIDRequestHandler
          data-receive-point-by-arguments:
            access DRA_rp_SR_UpdateShortServiceResponse_UpdateShortServiceRespData: accessed-variable=rp_SR_UpdateShortServiceResponse.UpdateShortServiceRespData
          data-send-points:
            access DWA_pp_SR_UpdateLongServiceRequest_UpdateLongServiceReqData: accessed-variable=pp_SR_UpdateLongServiceRequest.UpdateLongServiceReqData
            access DWA_pp_SR_UpdateShortServiceRequest_UpdateShortServiceReqData: accessed-variable=pp_SR_UpdateShortServiceRequest.UpdateShortServiceReqData
        CUpdateCdd_UpdateCdd_GenericDownloadRequestHandler
          data-receive-point-by-arguments:
            access DRA_rp_SR_UpdateShortServiceResponse_UpdateShortServiceRespData: accessed-variable=rp_SR_UpdateShortServiceResponse.UpdateShortServiceRespData
          data-send-points:
            access DWA_pp_SR_UpdateLongServiceRequest_UpdateLongServiceReqData: accessed-variable=pp_SR_UpdateLongServiceRequest.UpdateLongServiceReqData
            access DWA_pp_SR_UpdateShortServiceRequest_UpdateShortServiceReqData: accessed-variable=pp_SR_UpdateShortServiceRequest.UpdateShortServiceReqData
        CUpdateCdd_UpdateCdd_GenericRIDRequestHandler
          data-receive-point-by-arguments:
            access DRA_rp_SR_UpdateShortServiceResponse_UpdateShortServiceRespData: accessed-variable=rp_SR_UpdateShortServiceResponse.UpdateShortServiceRespData
          data-send-points:
            access DWA_pp_SR_UpdateLongServiceRequest_UpdateLongServiceReqData: accessed-variable=pp_SR_UpdateLongServiceRequest.UpdateLongServiceReqData
            access DWA_pp_SR_UpdateShortServiceRequest_UpdateShortServiceReqData: accessed-variable=pp_SR_UpdateShortServiceRequest.UpdateShortServiceReqData
        CUpdateCdd_UpdateCdd_GenericTransferDataHandler
          data-receive-point-by-arguments:
            access DRA_rp_SR_UpdateShortServiceResponse_UpdateShortServiceRespData: accessed-variable=rp_SR_UpdateShortServiceResponse.UpdateShortServiceRespData
          data-send-points:
            access DWA_pp_SR_UpdateLongServiceRequest_UpdateLongServiceReqData: accessed-variable=pp_SR_UpdateLongServiceRequest.UpdateLongServiceReqData
            access DWA_pp_SR_UpdateShortServiceRequest_UpdateShortServiceReqData: accessed-variable=pp_SR_UpdateShortServiceRequest.UpdateShortServiceReqData
        CUpdateCdd_UpdateCdd_GenericTransferExitHandler
          data-receive-point-by-arguments:
            access DRA_rp_SR_UpdateShortServiceResponse_UpdateShortServiceRespData: accessed-variable=rp_SR_UpdateShortServiceResponse.UpdateShortServiceRespData
          data-send-points:
            access DWA_pp_SR_UpdateLongServiceRequest_UpdateLongServiceReqData: accessed-variable=pp_SR_UpdateLongServiceRequest.UpdateLongServiceReqData
            access DWA_pp_SR_UpdateShortServiceRequest_UpdateShortServiceReqData: accessed-variable=pp_SR_UpdateShortServiceRequest.UpdateShortServiceReqData
  constant specification CUpdateCddUpdateLongServiceReqDataValue0: value-spec={short-label=CUpdateCddUpdateLongServiceReqDataValue0, fields=[CUpdateCddUpdateLongServiceReqDataValue_0:0, CUpdateCddUpdateLongServiceReqDataValue_1:0, CUpdateCddUpdateLongServiceReqDataValue_2:0, CUpdateCddUpdateLongServiceReqDataValue_3:0, CUpdateCddUpdateLongServiceReqDataValue_4:0, CUpdateCddUpdateLongServiceReqDataValue_5:0, CUpdateCddUpdateLongServiceReqDataValue_6:[CUpdateCdddata0Value:0, CUpdateCdddata1Value:0, CUpdateCdddata2Value:0, CUpdateCdddata3Value:0, CUpdateCdddata4Value:0, CUpdateCdddata5Value:0, CUpdateCdddata6Value:0, CUpdateCdddata7Value:0, CUpdateCdddata8Value:0, CUpdateCdddata9Value:0, CUpdateCdddata10Value:0, CUpdateCdddata11Value:0, CUpdateCdddata12Value:0, CUpdateCdddata13Value:0, CUpdateCdddata14Value:0, CUpdateCdddata15Value:0, CUpdateCdddata16Value:0, CUpdateCdddata17Value:0, CUpdateCdddata18Value:0, CUpdateCdddata19Value:0, CUpdateCdddata20Value:0, CUpdateCdddata21Value:0, CUpdateCdddata22Value:0, CUpdateCdddata23Value:0, CUpdateCdddata24Value:0, CUpdateCdddata25Value:0, CUpdateCdddata26Value:0, CUpdateCdddata27Value:0, CUpdateCdddata28Value:0, CUpdateCdddata29Value:0, CUpdateCdddata30Value:0, CUpdateCdddata31Value:0, CUpdateCdddata32Value:0, CUpdateCdddata33Value:0, CUpdateCdddata34Value:0, CUpdateCdddata35Value:0, CUpdateCdddata36Value:0, CUpdateCdddata37Value:0, CUpdateCdddata38Value:0, CUpdateCdddata39Value:0, CUpdateCdddata40Value:0, CUpdateCdddata41Value:0, CUpdateCdddata42Value:0, CUpdateCdddata43Value:0, CUpdateCdddata44Value:0, CUpdateCdddata45Value:0, CUpdateCdddata46Value:0, CUpdateCdddata47Value:0, CUpdateCdddata48Value:0, CUpdateCdddata49Value:0, CUpdateCdddata50Value:0, CUpdateCdddata51Value:0, CUpdateCdddata52Value:0, CUpdateCdddata53Value:0, CUpdateCdddata54Value:0, CUpdateCdddata55Value:0, CUpdateCdddata56Value:0, CUpdateCdddata57Value:0, CUpdateCdddata58Value:0, CUpdateCdddata59Value:0, CUpdateCdddata60Value:0, CUpdateCdddata61Value:0, CUpdateCdddata62Value:0, CUpdateCdddata63Value:0, CUpdateCdddata64Value:0, CUpdateCdddata65Value:0, CUpdateCdddata66Value:0, CUpdateCdddata67Value:0, CUpdateCdddata68Value:0, CUpdateCdddata69Value:0, CUpdateCdddata70Value:0, CUpdateCdddata71Value:0, CUpdateCdddata72Value:0, CUpdateCdddata73Value:0, CUpdateCdddata74Value:0, CUpdateCdddata75Value:0, CUpdateCdddata76Value:0, CUpdateCdddata77Value:0, CUpdateCdddata78Value:0, CUpdateCdddata79Value:0, CUpdateCdddata80Value:0, CUpdateCdddata81Value:0, CUpdateCdddata82Value:0, CUpdateCdddata83Value:0, CUpdateCdddata84Value:0, CUpdateCdddata85Value:0, CUpdateCdddata86Value:0, CUpdateCdddata87Value:0, CUpdateCdddata88Value:0, CUpdateCdddata89Value:0, CUpdateCdddata90Value:0, CUpdateCdddata91Value:0, CUpdateCdddata92Value:0, CUpdateCdddata93Value:0, CUpdateCdddata94Value:0, CUpdateCdddata95Value:0, CUpdateCdddata96Value:0, CUpdateCdddata97Value:0, CUpdateCdddata98Value:0, CUpdateCdddata99Value:0, CUpdateCdddata100Value:0, CUpdateCdddata101Value:0, CUpdateCdddata102Value:0, CUpdateCdddata103Value:0, CUpdateCdddata104Value:0, CUpdateCdddata105Value:0, CUpdateCdddata106Value:0, CUpdateCdddata107Value:0, CUpdateCdddata108Value:0, CUpdateCdddata109Value:0, CUpdateCdddata110Value:0, CUpdateCdddata111Value:0, CUpdateCdddata112Value:0, CUpdateCdddata113Value:0, CUpdateCdddata114Value:0, CUpdateCdddata115Value:0, CUpdateCdddata116Value:0, CUpdateCdddata117Value:0, CUpdateCdddata118Value:0, CUpdateCdddata119Value:0, CUpdateCdddata120Value:0, CUpdateCdddata121Value:0, CUpdateCdddata122Value:0, CUpdateCdddata123Value:0, CUpdateCdddata124Value:0, CUpdateCdddata125Value:0, CUpdateCdddata126Value:0, CUpdateCdddata127Value:0, CUpdateCdddata128Value:0, CUpdateCdddata129Value:0, CUpdateCdddata130Value:0, CUpdateCdddata131Value:0, CUpdateCdddata132Value:0, CUpdateCdddata133Value:0, CUpdateCdddata134Value:0, CUpdateCdddata135Value:0, CUpdateCdddata136Value:0, CUpdateCdddata137Value:0, CUpdateCdddata138Value:0, CUpdateCdddata139Value:0, CUpdateCdddata140Value:0, CUpdateCdddata141Value:0, CUpdateCdddata142Value:0, CUpdateCdddata143Value:0, CUpdateCdddata144Value:0, CUpdateCdddata145Value:0, CUpdateCdddata146Value:0, CUpdateCdddata147Value:0, CUpdateCdddata148Value:0, CUpdateCdddata149Value:0, CUpdateCdddata150Value:0, CUpdateCdddata151Value:0, CUpdateCdddata152Value:0, CUpdateCdddata153Value:0, CUpdateCdddata154Value:0, CUpdateCdddata155Value:0, CUpdateCdddata156Value:0, CUpdateCdddata157Value:0, CUpdateCdddata158Value:0, CUpdateCdddata159Value:0, CUpdateCdddata160Value:0, CUpdateCdddata161Value:0, CUpdateCdddata162Value:0, CUpdateCdddata163Value:0, CUpdateCdddata164Value:0, CUpdateCdddata165Value:0, CUpdateCdddata166Value:0, CUpdateCdddata167Value:0, CUpdateCdddata168Value:0, CUpdateCdddata169Value:0, CUpdateCdddata170Value:0, CUpdateCdddata171Value:0, CUpdateCdddata172Value:0, CUpdateCdddata173Value:0, CUpdateCdddata174Value:0, CUpdateCdddata175Value:0, CUpdateCdddata176Value:0, CUpdateCdddata177Value:0, CUpdateCdddata178Value:0, CUpdateCdddata179Value:0, CUpdateCdddata180Value:0, CUpdateCdddata181Value:0, CUpdateCdddata182Value:0, CUpdateCdddata183Value:0, CUpdateCdddata184Value:0, CUpdateCdddata185Value:0, CUpdateCdddata186Value:0, CUpdateCdddata187Value:0, CUpdateCdddata188Value:0, CUpdateCdddata189Value:0, CUpdateCdddata190Value:0, CUpdateCdddata191Value:0, CUpdateCdddata192Value:0, CUpdateCdddata193Value:0, CUpdateCdddata194Value:0, CUpdateCdddata195Value:0, CUpdateCdddata196Value:0, CUpdateCdddata197Value:0, CUpdateCdddata198Value:0, CUpdateCdddata199Value:0, CUpdateCdddata200Value:0, CUpdateCdddata201Value:0, CUpdateCdddata202Value:0, CUpdateCdddata203Value:0, CUpdateCdddata204Value:0, CUpdateCdddata205Value:0, CUpdateCdddata206Value:0, CUpdateCdddata207Value:0, CUpdateCdddata208Value:0, CUpdateCdddata209Value:0, CUpdateCdddata210Value:0, CUpdateCdddata211Value:0, CUpdateCdddata212Value:0, CUpdateCdddata213Value:0, CUpdateCdddata214Value:0, CUpdateCdddata215Value:0, CUpdateCdddata216Value:0, CUpdateCdddata217Value:0, CUpdateCdddata218Value:0, CUpdateCdddata219Value:0, CUpdateCdddata220Value:0, CUpdateCdddata221Value:0, CUpdateCdddata222Value:0, CUpdateCdddata223Value:0, CUpdateCdddata224Value:0, CUpdateCdddata225Value:0, CUpdateCdddata226Value:0, CUpdateCdddata227Value:0, CUpdateCdddata228Value:0, CUpdateCdddata229Value:0, CUpdateCdddata230Value:0, CUpdateCdddata231Value:0, CUpdateCdddata232Value:0, CUpdateCdddata233Value:0, CUpdateCdddata234Value:0, CUpdateCdddata235Value:0, CUpdateCdddata236Value:0, CUpdateCdddata237Value:0, CUpdateCdddata238Value:0, CUpdateCdddata239Value:0, CUpdateCdddata240Value:0, CUpdateCdddata241Value:0, CUpdateCdddata242Value:0, CUpdateCdddata243Value:0, CUpdateCdddata244Value:0, CUpdateCdddata245Value:0, CUpdateCdddata246Value:0, CUpdateCdddata247Value:0, CUpdateCdddata248Value:0, CUpdateCdddata249Value:0, CUpdateCdddata250Value:0, CUpdateCdddata251Value:0, CUpdateCdddata252Value:0, CUpdateCdddata253Value:0, CUpdateCdddata254Value:0, CUpdateCdddata255Value:0, CUpdateCdddata256Value:0, CUpdateCdddata257Value:0, CUpdateCdddata258Value:0, CUpdateCdddata259Value:0, CUpdateCdddata260Value:0, CUpdateCdddata261Value:0, CUpdateCdddata262Value:0, CUpdateCdddata263Value:0, CUpdateCdddata264Value:0, CUpdateCdddata265Value:0, CUpdateCdddata266Value:0, CUpdateCdddata267Value:0, CUpdateCdddata268Value:0, CUpdateCdddata269Value:0, CUpdateCdddata270Value:0, CUpdateCdddata271Value:0, CUpdateCdddata272Value:0, CUpdateCdddata273Value:0, CUpdateCdddata274Value:0, CUpdateCdddata275Value:0, CUpdateCdddata276Value:0, CUpdateCdddata277Value:0, CUpdateCdddata278Value:0, CUpdateCdddata279Value:0, CUpdateCdddata280Value:0, CUpdateCdddata281Value:0, CUpdateCdddata282Value:0, CUpdateCdddata283Value:0, CUpdateCdddata284Value:0, CUpdateCdddata285Value:0, CUpdateCdddata286Value:0, CUpdateCdddata287Value:0, CUpdateCdddata288Value:0, CUpdateCdddata289Value:0, CUpdateCdddata290Value:0, CUpdateCdddata291Value:0, CUpdateCdddata292Value:0, CUpdateCdddata293Value:0, CUpdateCdddata294Value:0, CUpdateCdddata295Value:0, CUpdateCdddata296Value:0, CUpdateCdddata297Value:0, CUpdateCdddata298Value:0, CUpdateCdddata299Value:0, CUpdateCdddata300Value:0, CUpdateCdddata301Value:0, CUpdateCdddata302Value:0, CUpdateCdddata303Value:0, CUpdateCdddata304Value:0, CUpdateCdddata305Value:0, CUpdateCdddata306Value:0, CUpdateCdddata307Value:0, CUpdateCdddata308Value:0, CUpdateCdddata309Value:0, CUpdateCdddata310Value:0, CUpdateCdddata311Value:0, CUpdateCdddata312Value:0, CUpdateCdddata313Value:0, CUpdateCdddata314Value:0, CUpdateCdddata315Value:0, CUpdateCdddata316Value:0, CUpdateCdddata317Value:0, CUpdateCdddata318Value:0, CUpdateCdddata319Value:0, CUpdateCdddata320Value:0, CUpdateCdddata321Value:0, CUpdateCdddata322Value:0, CUpdateCdddata323Value:0, CUpdateCdddata324Value:0, CUpdateCdddata325Value:0, CUpdateCdddata326Value:0, CUpdateCdddata327Value:0, CUpdateCdddata328Value:0, CUpdateCdddata329Value:0, CUpdateCdddata330Value:0, CUpdateCdddata331Value:0, CUpdateCdddata332Value:0, CUpdateCdddata333Value:0, CUpdateCdddata334Value:0, CUpdateCdddata335Value:0, CUpdateCdddata336Value:0, CUpdateCdddata337Value:0, CUpdateCdddata338Value:0, CUpdateCdddata339Value:0, CUpdateCdddata340Value:0, CUpdateCdddata341Value:0, CUpdateCdddata342Value:0, CUpdateCdddata343Value:0, CUpdateCdddata344Value:0, CUpdateCdddata345Value:0, CUpdateCdddata346Value:0, CUpdateCdddata347Value:0, CUpdateCdddata348Value:0, CUpdateCdddata349Value:0, CUpdateCdddata350Value:0, CUpdateCdddata351Value:0, CUpdateCdddata352Value:0, CUpdateCdddata353Value:0, CUpdateCdddata354Value:0, CUpdateCdddata355Value:0, CUpdateCdddata356Value:0, CUpdateCdddata357Value:0, CUpdateCdddata358Value:0, CUpdateCdddata359Value:0, CUpdateCdddata360Value:0, CUpdateCdddata361Value:0, CUpdateCdddata362Value:0, CUpdateCdddata363Value:0, CUpdateCdddata364Value:0, CUpdateCdddata365Value:0, CUpdateCdddata366Value:0, CUpdateCdddata367Value:0, CUpdateCdddata368Value:0, CUpdateCdddata369Value:0, CUpdateCdddata370Value:0, CUpdateCdddata371Value:0, CUpdateCdddata372Value:0, CUpdateCdddata373Value:0, CUpdateCdddata374Value:0, CUpdateCdddata375Value:0, CUpdateCdddata376Value:0, CUpdateCdddata377Value:0, CUpdateCdddata378Value:0, CUpdateCdddata379Value:0, CUpdateCdddata380Value:0, CUpdateCdddata381Value:0, CUpdateCdddata382Value:0, CUpdateCdddata383Value:0, CUpdateCdddata384Value:0, CUpdateCdddata385Value:0, CUpdateCdddata386Value:0, CUpdateCdddata387Value:0, CUpdateCdddata388Value:0, CUpdateCdddata389Value:0, CUpdateCdddata390Value:0, CUpdateCdddata391Value:0, CUpdateCdddata392Value:0, CUpdateCdddata393Value:0, CUpdateCdddata394Value:0, CUpdateCdddata395Value:0, CUpdateCdddata396Value:0, CUpdateCdddata397Value:0, CUpdateCdddata398Value:0, CUpdateCdddata399Value:0, CUpdateCdddata400Value:0, CUpdateCdddata401Value:0, CUpdateCdddata402Value:0, CUpdateCdddata403Value:0, CUpdateCdddata404Value:0, CUpdateCdddata405Value:0, CUpdateCdddata406Value:0, CUpdateCdddata407Value:0, CUpdateCdddata408Value:0, CUpdateCdddata409Value:0, CUpdateCdddata410Value:0, CUpdateCdddata411Value:0, CUpdateCdddata412Value:0, CUpdateCdddata413Value:0, CUpdateCdddata414Value:0, CUpdateCdddata415Value:0, CUpdateCdddata416Value:0, CUpdateCdddata417Value:0, CUpdateCdddata418Value:0, CUpdateCdddata419Value:0, CUpdateCdddata420Value:0, CUpdateCdddata421Value:0, CUpdateCdddata422Value:0, CUpdateCdddata423Value:0, CUpdateCdddata424Value:0, CUpdateCdddata425Value:0, CUpdateCdddata426Value:0, CUpdateCdddata427Value:0, CUpdateCdddata428Value:0, CUpdateCdddata429Value:0, CUpdateCdddata430Value:0, CUpdateCdddata431Value:0, CUpdateCdddata432Value:0, CUpdateCdddata433Value:0, CUpdateCdddata434Value:0, CUpdateCdddata435Value:0, CUpdateCdddata436Value:0, CUpdateCdddata437Value:0, CUpdateCdddata438Value:0, CUpdateCdddata439Value:0, CUpdateCdddata440Value:0, CUpdateCdddata441Value:0, CUpdateCdddata442Value:0, CUpdateCdddata443Value:0, CUpdateCdddata444Value:0, CUpdateCdddata445Value:0, CUpdateCdddata446Value:0, CUpdateCdddata447Value:0, CUpdateCdddata448Value:0, CUpdateCdddata449Value:0, CUpdateCdddata450Value:0, CUpdateCdddata451Value:0, CUpdateCdddata452Value:0, CUpdateCdddata453Value:0, CUpdateCdddata454Value:0, CUpdateCdddata455Value:0, CUpdateCdddata456Value:0, CUpdateCdddata457Value:0, CUpdateCdddata458Value:0, CUpdateCdddata459Value:0, CUpdateCdddata460Value:0, CUpdateCdddata461Value:0, CUpdateCdddata462Value:0, CUpdateCdddata463Value:0, CUpdateCdddata464Value:0, CUpdateCdddata465Value:0, CUpdateCdddata466Value:0, CUpdateCdddata467Value:0, CUpdateCdddata468Value:0, CUpdateCdddata469Value:0, CUpdateCdddata470Value:0, CUpdateCdddata471Value:0, CUpdateCdddata472Value:0, CUpdateCdddata473Value:0, CUpdateCdddata474Value:0, CUpdateCdddata475Value:0, CUpdateCdddata476Value:0, CUpdateCdddata477Value:0, CUpdateCdddata478Value:0, CUpdateCdddata479Value:0, CUpdateCdddata480Value:0, CUpdateCdddata481Value:0, CUpdateCdddata482Value:0, CUpdateCdddata483Value:0, CUpdateCdddata484Value:0, CUpdateCdddata485Value:0, CUpdateCdddata486Value:0, CUpdateCdddata487Value:0, CUpdateCdddata488Value:0, CUpdateCdddata489Value:0, CUpdateCdddata490Value:0, CUpdateCdddata491Value:0, CUpdateCdddata492Value:0, CUpdateCdddata493Value:0, CUpdateCdddata494Value:0, CUpdateCdddata495Value:0, CUpdateCdddata496Value:0, CUpdateCdddata497Value:0, CUpdateCdddata498Value:0, CUpdateCdddata499Value:0, CUpdateCdddata500Value:0, CUpdateCdddata501Value:0, CUpdateCdddata502Value:0, CUpdateCdddata503Value:0, CUpdateCdddata504Value:0, CUpdateCdddata505Value:0, CUpdateCdddata506Value:0, CUpdateCdddata507Value:0, CUpdateCdddata508Value:0, CUpdateCdddata509Value:0, CUpdateCdddata510Value:0, CUpdateCdddata511Value:0]]}
  constant specification CUpdateCddUpdateShortServiceReqDataValue0: value-spec={short-label=CUpdateCddUpdateShortServiceReqDataValue0, fields=[CUpdateCddUpdateShortServiceReqDataValue_0:0, CUpdateCddUpdateShortServiceReqDataValue_1:0, CUpdateCddUpdateShortServiceReqDataValue_2:0, CUpdateCddUpdateShortServiceReqDataValue_3:0, CUpdateCddUpdateShortServiceReqDataValue_4:0, CUpdateCddUpdateShortServiceReqDataValue_5:0, CUpdateCddUpdateShortServiceReqDataValue_6:[CUpdateCdddata0Value:0, CUpdateCdddata1Value:0, CUpdateCdddata2Value:0, CUpdateCdddata3Value:0, CUpdateCdddata4Value:0, CUpdateCdddata5Value:0, CUpdateCdddata6Value:0, CUpdateCdddata7Value:0, CUpdateCdddata8Value:0, CUpdateCdddata9Value:0, CUpdateCdddata10Value:0, CUpdateCdddata11Value:0, CUpdateCdddata12Value:0, CUpdateCdddata13Value:0, CUpdateCdddata14Value:0, CUpdateCdddata15Value:0, CUpdateCdddata16Value:0, CUpdateCdddata17Value:0, CUpdateCdddata18Value:0, CUpdateCdddata19Value:0, CUpdateCdddata20Value:0, CUpdateCdddata21Value:0, CUpdateCdddata22Value:0, CUpdateCdddata23Value:0, CUpdateCdddata24Value:0, CUpdateCdddata25Value:0, CUpdateCdddata26Value:0, CUpdateCdddata27Value:0, CUpdateCdddata28Value:0, CUpdateCdddata29Value:0, CUpdateCdddata30Value:0, CUpdateCdddata31Value:0, CUpdateCdddata32Value:0, CUpdateCdddata33Value:0, CUpdateCdddata34Value:0, CUpdateCdddata35Value:0, CUpdateCdddata36Value:0, CUpdateCdddata37Value:0, CUpdateCdddata38Value:0, CUpdateCdddata39Value:0, CUpdateCdddata40Value:0, CUpdateCdddata41Value:0, CUpdateCdddata42Value:0, CUpdateCdddata43Value:0, CUpdateCdddata44Value:0, CUpdateCdddata45Value:0, CUpdateCdddata46Value:0, CUpdateCdddata47Value:0, CUpdateCdddata48Value:0, CUpdateCdddata49Value:0, CUpdateCdddata50Value:0, CUpdateCdddata51Value:0, CUpdateCdddata52Value:0, CUpdateCdddata53Value:0, CUpdateCdddata54Value:0, CUpdateCdddata55Value:0, CUpdateCdddata56Value:0, CUpdateCdddata57Value:0, CUpdateCdddata58Value:0, CUpdateCdddata59Value:0, CUpdateCdddata60Value:0, CUpdateCdddata61Value:0, CUpdateCdddata62Value:0, CUpdateCdddata63Value:0]]}
  constant specification CUpdateCddUpdateShortServiceRespDataValue0: value-spec={short-label=CUpdateCddUpdateShortServiceRespDataValue0, fields=[CUpdateCddUpdateShortServiceRespDataValue_0:0, CUpdateCddUpdateShortServiceRespDataValue_1:0, CUpdateCddUpdateShortServiceRespDataValue_2:0, CUpdateCddUpdateShortServiceRespDataValue_3:0, CUpdateCddUpdateShortServiceRespDataValue_4:0, CUpdateCddUpdateShortServiceRespDataValue_5:0, CUpdateCddUpdateShortServiceRespDataValue_6:[CUpdateCdddata0Value:0, CUpdateCdddata1Value:0, CUpdateCdddata2Value:0, CUpdateCdddata3Value:0, CUpdateCdddata4Value:0, CUpdateCdddata5Value:0, CUpdateCdddata6Value:0, CUpdateCdddata7Value:0, CUpdateCdddata8Value:0, CUpdateCdddata9Value:0, CUpdateCdddata10Value:0, CUpdateCdddata11Value:0, CUpdateCdddata12Value:0, CUpdateCdddata13Value:0, CUpdateCdddata14Value:0, CUpdateCdddata15Value:0, CUpdateCdddata16Value:0, CUpdateCdddata17Value:0, CUpdateCdddata18Value:0, CUpdateCdddata19Value:0, CUpdateCdddata20Value:0, CUpdateCdddata21Value:0, CUpdateCdddata22Value:0, CUpdateCdddata23Value:0, CUpdateCdddata24Value:0, CUpdateCdddata25Value:0, CUpdateCdddata26Value:0, CUpdateCdddata27Value:0, CUpdateCdddata28Value:0, CUpdateCdddata29Value:0, CUpdateCdddata30Value:0, CUpdateCdddata31Value:0, CUpdateCdddata32Value:0, CUpdateCdddata33Value:0, CUpdateCdddata34Value:0, CUpdateCdddata35Value:0, CUpdateCdddata36Value:0, CUpdateCdddata37Value:0, CUpdateCdddata38Value:0, CUpdateCdddata39Value:0, CUpdateCdddata40Value:0, CUpdateCdddata41Value:0, CUpdateCdddata42Value:0, CUpdateCdddata43Value:0, CUpdateCdddata44Value:0, CUpdateCdddata45Value:0, CUpdateCdddata46Value:0, CUpdateCdddata47Value:0, CUpdateCdddata48Value:0, CUpdateCdddata49Value:0, CUpdateCdddata50Value:0, CUpdateCdddata51Value:0, CUpdateCdddata52Value:0, CUpdateCdddata53Value:0, CUpdateCdddata54Value:0, CUpdateCdddata55Value:0, CUpdateCdddata56Value:0, CUpdateCdddata57Value:0, CUpdateCdddata58Value:0, CUpdateCdddata59Value:0, CUpdateCdddata60Value:0, CUpdateCdddata61Value:0, CUpdateCdddata62Value:0, CUpdateCdddata63Value:0]]}
  swc implementation IMPL_CUpdateCdd: programming-language=C, behavior=IB_CUpdateCdd
    code-descriptors:
      code CodeDescriptor
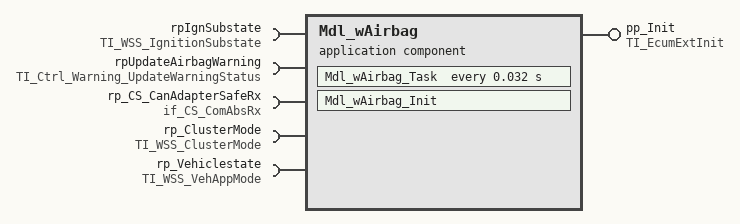
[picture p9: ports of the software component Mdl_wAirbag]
  application sw component type Mdl_wAirbag
    provide port pp_Init: server-com-spec{operation=TI_EcumExtInit/Init, queue-length=1}, provided-interface=TI_EcumExtInit
    5 x require port:
      rpIgnSubstate: nonqueued-receiver-com-spec{data-element=IgnitionSubstate, init-value=constant-reference=Mdl_wAirbagIgnitionSubstateValue0}, required-interface=TI_WSS_IgnitionSubstate
      rpUpdateAirbagWarning: required-interface=TI_Ctrl_Warning_UpdateWarningStatus
      rp_CS_CanAdapterSafeRx: required-interface=if_CS_ComAbsRx
      rp_ClusterMode: nonqueued-receiver-com-spec{data-element=WSSCurrentClusterMode, init-value=constant-reference=Mdl_wAirbagWSSCurrentClusterModeValue0}, required-interface=TI_WSS_ClusterMode
      rp_Vehiclestate: nonqueued-receiver-com-spec{data-element=WSSCurrentVehicleState, init-value=constant-reference=Mdl_wAirbagWSSCurrentVehicleStateValue0}, required-interface=TI_WSS_VehAppMode
    behavior IB_Mdl_wAirbag
      operation invoked event OIE_pp_Init_Mdl_wAirbag_InitTrigByInit: start-on-event=Mdl_wAirbag_Init, operation=pp_Init.Init
      timing event TEMdl_wAirbag_Task: start-on-event=Mdl_wAirbag_Task, period=0.032
      port-api-options:
        enable-take-address=false, indirect-api=false, port=Mdl_wAirbag/pp_Init
        enable-take-address=false, indirect-api=false, port=Mdl_wAirbag/rpIgnSubstate
        enable-take-address=false, indirect-api=false, port=rpUpdateAirbagWarning
        enable-take-address=false, indirect-api=false, port=rp_CS_CanAdapterSafeRx
        enable-take-address=false, indirect-api=false, port=Mdl_wAirbag/rp_ClusterMode
        enable-take-address=false, indirect-api=false, port=rp_Vehiclestate
      runnable Mdl_wAirbag_Init: can-be-invoked-concurrently=true
      runnable Mdl_wAirbag_Task: can-be-invoked-concurrently=true
        data-receive-point-by-arguments:
          access DRA_rpIgnSubstate_IgnitionSubstate: accessed-variable=rpIgnSubstate.IgnitionSubstate
          access DRA_rp_ClusterMode_WSSCurrentClusterMode: accessed-variable=rp_ClusterMode.WSSCurrentClusterMode
          access DRA_rp_Vehiclestate_WSSCurrentVehicleState: accessed-variable=rp_Vehiclestate.WSSCurrentVehicleState
        10 x sync call, all with timeout=0.0:
          OA_rpUpdateAirbagWarning_UpdateWarningStatus: operation=rpUpdateAirbagWarning.UpdateWarningStatus
          OA_rp_CS_CanAdapterSafeRx_RxCan_GetSignalValueU8Arr: operation=rp_CS_CanAdapterSafeRx.RxCan_GetSignalValueU8Arr
          OA_rp_CS_CanAdapterSafeRx_RxCan_SetSignalInitValue: operation=rp_CS_CanAdapterSafeRx.RxCan_SetSignalInitValue
          OA_rp_CS_CanAdapterSafeRx_RxCan_SetSignalInitValueU8Arr: operation=rp_CS_CanAdapterSafeRx.RxCan_SetSignalInitValueU8Arr
          OA_rp_CS_CanAdapterSafeRx_RxCan_SignalInvalidProcessingControl: operation=rp_CS_CanAdapterSafeRx.RxCan_SignalInvalidProcessingControl
          OA_rp_CS_CanAdapterSafeRx_RxCan_SignalMissingProcessingControl: operation=rp_CS_CanAdapterSafeRx.RxCan_SignalMissingProcessingControl
          OA_rp_CS_CanAdapterSafeRx_RxCan_SignalNRProcessingControl: operation=rp_CS_CanAdapterSafeRx.RxCan_SignalNRProcessingControl
          OA_rp_CS_CanAdapterSafeRx_RxCan_SignalGetJustRcvdStatus: operation=rp_CS_CanAdapterSafeRx.RxCan_SignalGetJustRcvdStatus
          OA_rp_CS_CanAdapterSafeRx_RxCan_SignalClearJustRcvdStatus: operation=rp_CS_CanAdapterSafeRx.RxCan_SignalClearJustRcvdStatus
          OA_rp_CS_CanAdapterSafeRx_RxCan_GetSignalValue: operation=rp_CS_CanAdapterSafeRx.RxCan_GetSignalValue
  constant specification Mdl_wAirbagIgnitionSubstateValue0: value-spec=Mdl_wAirbagIgnitionSubstateValue0:0
  constant specification Mdl_wAirbagWSSCurrentClusterModeValue0: value-spec=Mdl_wAirbagWSSCurrentClusterModeValue0:0
  constant specification Mdl_wAirbagWSSCurrentVehicleStateValue0: value-spec=Mdl_wAirbagWSSCurrentVehicleStateValue0:0
  swc implementation IMPL_Mdl_wAirbag: programming-language=C, behavior=IB_Mdl_wAirbag
    code-descriptors:
      code CodeDescriptor
  application sw component type Mdl_wFuelLidOpen
    provide port pp_Init: server-com-spec{operation=TI_EcumExtInit/Init, queue-length=1}, provided-interface=TI_EcumExtInit
    4 x require port:
      rpIgnSubstate: nonqueued-receiver-com-spec{data-element=IgnitionSubstate, init-value=constant-reference=Mdl_wFuelLidOpenIgnitionSubstateValue0}, required-interface=TI_WSS_IgnitionSubstate
      rpUpdateFuelLidOpenWarning: required-interface=TI_Ctrl_Warning_UpdateWarningStatus
      rp_CS_RxCanAdapterMdl: required-interface=if_CS_ComAbsRx
      rp_ClusterMode: nonqueued-receiver-com-spec{data-element=WSSCurrentClusterMode, init-value=constant-reference=Mdl_wFuelLidOpenWSSCurrentClusterModeValue0}, required-interface=TI_WSS_ClusterMode
    behavior IB_Mdl_wFuelLidOpen
      operation invoked event OIE_pp_Init_Mdl_wFuelLidOpen_InitTrigByInit: start-on-event=Mdl_wFuelLidOpen_Init, operation=pp_Init.Init
      timing event TEMdl_wFuelLidOpen_Task: start-on-event=Mdl_wFuelLidOpen_Task, period=0.032
      port-api-options:
        enable-take-address=false, indirect-api=false, port=Mdl_wFuelLidOpen/pp_Init
        enable-take-address=false, indirect-api=false, port=Mdl_wFuelLidOpen/rpIgnSubstate
        enable-take-address=false, indirect-api=false, port=rpUpdateFuelLidOpenWarning
        enable-take-address=false, indirect-api=false, port=rp_CS_RxCanAdapterMdl
        enable-take-address=false, indirect-api=false, port=Mdl_wFuelLidOpen/rp_ClusterMode
      runnable Mdl_wFuelLidOpen_Init: can-be-invoked-concurrently=true
      runnable Mdl_wFuelLidOpen_Task: can-be-invoked-concurrently=true
        data-receive-point-by-arguments:
          access DRA_rpIgnSubstate_IgnitionSubstate: accessed-variable=rpIgnSubstate.IgnitionSubstate
          access DRA_rp_ClusterMode_WSSCurrentClusterMode: accessed-variable=rp_ClusterMode.WSSCurrentClusterMode
        10 x sync call, all with timeout=0.0:
          OA_rpUpdateFuelLidOpenWarning_UpdateWarningStatus: operation=rpUpdateFuelLidOpenWarning.UpdateWarningStatus
          OA_rp_CS_RxCanAdapterMdl_RxCan_GetSignalValueU8Arr: operation=rp_CS_RxCanAdapterMdl.RxCan_GetSignalValueU8Arr
          OA_rp_CS_RxCanAdapterMdl_RxCan_SetSignalInitValue: operation=rp_CS_RxCanAdapterMdl.RxCan_SetSignalInitValue
          OA_rp_CS_RxCanAdapterMdl_RxCan_SetSignalInitValueU8Arr: operation=rp_CS_RxCanAdapterMdl.RxCan_SetSignalInitValueU8Arr
          OA_rp_CS_RxCanAdapterMdl_RxCan_SignalInvalidProcessingControl: operation=rp_CS_RxCanAdapterMdl.RxCan_SignalInvalidProcessingControl
          OA_rp_CS_RxCanAdapterMdl_RxCan_SignalMissingProcessingControl: operation=rp_CS_RxCanAdapterMdl.RxCan_SignalMissingProcessingControl
          OA_rp_CS_RxCanAdapterMdl_RxCan_SignalNRProcessingControl: operation=rp_CS_RxCanAdapterMdl.RxCan_SignalNRProcessingControl
          OA_rp_CS_RxCanAdapterMdl_RxCan_SignalGetJustRcvdStatus: operation=rp_CS_RxCanAdapterMdl.RxCan_SignalGetJustRcvdStatus
          OA_rp_CS_RxCanAdapterMdl_RxCan_SignalClearJustRcvdStatus: operation=rp_CS_RxCanAdapterMdl.RxCan_SignalClearJustRcvdStatus
          OA_rp_CS_RxCanAdapterMdl_RxCan_GetSignalValue: operation=rp_CS_RxCanAdapterMdl.RxCan_GetSignalValue
  constant specification Mdl_wFuelLidOpenIgnitionSubstateValue0: value-spec=Mdl_wFuelLidOpenIgnitionSubstateValue0:0
  constant specification Mdl_wFuelLidOpenWSSCurrentClusterModeValue0: value-spec=Mdl_wFuelLidOpenWSSCurrentClusterModeValue0:0
  swc implementation IMPL_Mdl_wFuelLidOpen: programming-language=C, behavior=IB_Mdl_wFuelLidOpen
    code-descriptors:
      code CodeDescriptor
  application sw component type WarnMsg_Core_TmrSupport
    provide port pp_Init: server-com-spec{operation=TI_EcumExtInit/Init, queue-length=1}, provided-interface=TI_EcumExtInit
    4 x require port:
      rp_CS_TmExt_Timer_Elapsed: required-interface=TI_If_TmExt_Timer_IsElapsed
      rp_CS_TmExt_Timer_Start: required-interface=TI_If_TmExt_Timer_Start
      rp_CS_TmExt_Timer_Started: required-interface=TI_If_TmExt_Timer_IsStarted
      rp_CS_TmExt_Timer_Stop: required-interface=TI_If_TmExt_Timer_Stop
    behavior IB_WarnMsg_Core_TmrSupport
      operation invoked event OIE_pp_Init_WarnMsg_Core_TmrSupport_InitTrigByInit: start-on-event=WarnMsg_Core_TmrSupport_Init, operation=pp_Init.Init
      timing event TEWarnMsg_Core_TmrSupport_Task: start-on-event=WarnMsg_Core_TmrSupport_Task, period=0.032
      port-api-options:
        enable-take-address=false, indirect-api=false, port=WarnMsg_Core_TmrSupport/pp_Init
        enable-take-address=false, indirect-api=false, port=WarnMsg_Core_TmrSupport/rp_CS_TmExt_Timer_Elapsed
        enable-take-address=false, indirect-api=false, port=WarnMsg_Core_TmrSupport/rp_CS_TmExt_Timer_Start
        enable-take-address=false, indirect-api=false, port=WarnMsg_Core_TmrSupport/rp_CS_TmExt_Timer_Started
        enable-take-address=false, indirect-api=false, port=WarnMsg_Core_TmrSupport/rp_CS_TmExt_Timer_Stop
      runnable WarnMsg_Core_TmrSupport_Init: can-be-invoked-concurrently=true
      runnable WarnMsg_Core_TmrSupport_Task: can-be-invoked-concurrently=true
        4 x sync call, all with timeout=0.0:
          OA_rp_CS_TmExt_Timer_Elapsed_Timer_IsElapsed: operation=rp_CS_TmExt_Timer_Elapsed.Timer_IsElapsed
          OA_rp_CS_TmExt_Timer_Start_Timer_Start: operation=rp_CS_TmExt_Timer_Start.Timer_Start
          OA_rp_CS_TmExt_Timer_Started_Timer_IsStarted: operation=rp_CS_TmExt_Timer_Started.Timer_IsStarted
          OA_rp_CS_TmExt_Timer_Stop_Timer_Stop: operation=rp_CS_TmExt_Timer_Stop.Timer_Stop
  swc implementation IMPL_WarnMsg_Core_TmrSupport: programming-language=C, behavior=IB_WarnMsg_Core_TmrSupport
    code-descriptors:
      code CodeDescriptor
  application sw component type DcmApp
    4 x provide port:
      pp_CS_DID_App_Diag_Action: server-com-spec{operation=TI_DID_App_Diag_Action/DID_DiagAction, queue-length=1}, provided-interface=TI_DID_App_Diag_Action
      pp_CS_DiagEntryStatus: server-com-spec{operation=Diag_Entry_Status, queue-length=1}, provided-interface=TI_DiagEntrySts
      pp_CS_RID_App_Diag_Action: server-com-spec{operation=TI_RID_App_Diag_Action/RID_DiagAction, queue-length=1}, provided-interface=TI_RID_App_Diag_Action
      pp_CmpLibCmd_CDcmApp: server-com-spec{operation=Impl_OnCommand, queue-length=1}, provided-interface=if_CS_ModeOnCommand
    behavior IB_DcmApp
      operation invoked event OIE_pp_CS_DID_App_Diag_Action_CDcmApp_DID_DiagActionTrigByDID_DiagAction: start-on-event=CDcmApp_DID_DiagAction, operation=pp_CS_DID_App_Diag_Action.DID_DiagAction
      operation invoked event OIE_pp_CS_DiagEntryStatus_CDcmApp_Diag_Entry_StatusTrigByDiag_Entry_Status: start-on-event=CDcmApp_Diag_Entry_Status, operation=pp_CS_DiagEntryStatus.Diag_Entry_Status
      timing event TECDcmApp_Impl_MainFunction: start-on-event=CDcmApp_Impl_MainFunction, period=0.01
      operation invoked event OIE_pp_CmpLibCmd_CDcmApp_CDcmApp_Impl_OnCommandTrigByImpl_OnCommand: start-on-event=CDcmApp_Impl_OnCommand, operation=pp_CmpLibCmd_CDcmApp.Impl_OnCommand
      operation invoked event OIE_pp_CS_RID_App_Diag_Action_CDcmApp_RID_DiagActionTrigByRID_DiagAction: start-on-event=CDcmApp_RID_DiagAction, operation=pp_CS_RID_App_Diag_Action.RID_DiagAction
      port-api-options:
        enable-take-address=false, indirect-api=false, port=pp_CS_DID_App_Diag_Action
        enable-take-address=false, indirect-api=false, port=pp_CS_DiagEntryStatus
        enable-take-address=false, indirect-api=false, port=pp_CS_RID_App_Diag_Action
        enable-take-address=false, indirect-api=false, port=pp_CmpLibCmd_CDcmApp
      5 x runnable, all with can-be-invoked-concurrently=true:
        CDcmApp_DID_DiagAction
        CDcmApp_Diag_Entry_Status
        CDcmApp_Impl_MainFunction
        CDcmApp_Impl_OnCommand
        CDcmApp_RID_DiagAction
  swc implementation IMPL_DcmApp: programming-language=C, behavior=IB_DcmApp
    code-descriptors:
      code CodeDescriptor
  application sw component type DemApp
    provide port pp_CmpLibCmd_CDemApp: server-com-spec{operation=Impl_OnCommand, queue-length=1}, provided-interface=if_CS_ModeOnCommand
    require port rp_CS_DemExt_ClearDTC: required-interface=TI_DemExt_ClearDTC
    require port rp_CS_DemExt_SetEventStatus: required-interface=TI_DemExt_SetEventStatus
    require port rp_CS_DemExt_SetOperationCycleState: required-interface=TI_DemExt_SetOperationCycleState
    behavior IB_DemApp
      timing event TECDemApp_Impl_MainFunction: start-on-event=CDemApp_Impl_MainFunction, period=0.01
      operation invoked event OIE_pp_CmpLibCmd_CDemApp_CDemApp_Impl_OnCommandTrigByImpl_OnCommand: start-on-event=CDemApp_Impl_OnCommand, operation=pp_CmpLibCmd_CDemApp.Impl_OnCommand
      port-api-options:
        enable-take-address=false, indirect-api=false, port=pp_CmpLibCmd_CDemApp
        enable-take-address=false, indirect-api=false, port=rp_CS_DemExt_ClearDTC
        enable-take-address=false, indirect-api=false, port=DemApp/rp_CS_DemExt_SetEventStatus
        enable-take-address=false, indirect-api=false, port=rp_CS_DemExt_SetOperationCycleState
      runnable CDemApp_Impl_MainFunction: can-be-invoked-concurrently=true
        sync call OA_rp_CS_DemExt_ClearDTC_DemExt_ClearDTC: operation=rp_CS_DemExt_ClearDTC.DemExt_ClearDTC, timeout=0.0
        sync call OA_rp_CS_DemExt_SetEventStatus_DemExt_SetEventStatus: operation=rp_CS_DemExt_SetEventStatus.DemExt_SetEventStatus, timeout=0.0
        sync call OA_rp_CS_DemExt_SetOperationCycleState_DemExt_SetOperationCycleState: operation=rp_CS_DemExt_SetOperationCycleState.DemExt_SetOperationCycleState, timeout=0.0
      runnable CDemApp_Impl_OnCommand: can-be-invoked-concurrently=true
        sync call OA_rp_CS_DemExt_ClearDTC_DemExt_ClearDTC: operation=rp_CS_DemExt_ClearDTC.DemExt_ClearDTC, timeout=0.0
        sync call OA_rp_CS_DemExt_SetEventStatus_DemExt_SetEventStatus: operation=rp_CS_DemExt_SetEventStatus.DemExt_SetEventStatus, timeout=0.0
        sync call OA_rp_CS_DemExt_SetOperationCycleState_DemExt_SetOperationCycleState: operation=rp_CS_DemExt_SetOperationCycleState.DemExt_SetOperationCycleState, timeout=0.0
  swc implementation IMPL_DemApp: programming-language=C, behavior=IB_DemApp
    code-descriptors:
      code CodeDescriptor
  application sw component type DemExt
    17 x provide port:
      pp_CS_DemExt_ClearDTC: server-com-spec{operation=DemExt_ClearDTC, queue-length=1}, provided-interface=TI_DemExt_ClearDTC
      pp_CS_DemExt_GetDTCOfEvent: server-com-spec{operation=DemExt_GetDTCOfEvent, queue-length=1}, provided-interface=TI_DemExt_GetDTCOfEvent
      pp_CS_DemExt_GetDTCSelectionResult: server-com-spec{operation=DemExt_GetDTCSelectionResult, queue-length=1}, provided-interface=TI_DemExt_GetDTCSelectionResult
      pp_CS_DemExt_GetDTCSelectionResultForClearDTC: server-com-spec{operation=DemExt_GetDTCSelectionResultForClearDTC, queue-length=1}, provided-interface=TI_DemExt_GetDTCSelectionResultForClearDTC
      pp_CS_DemExt_GetDebouncingOfEvent: server-com-spec{operation=DemExt_GetDebouncingOfEvent, queue-length=1}, provided-interface=TI_DemExt_GetDebouncingOfEvent
      pp_CS_DemExt_GetEventExtendedDataRecordEx: server-com-spec{operation=DemExt_GetEventExtendedDataRecordEx, queue-length=1}, provided-interface=TI_DemExt_GetEventExtendedDataRecordEx
      pp_CS_DemExt_GetEventFreezeFrameDataEx: server-com-spec{operation=DemExt_GetEventFreezeFrameDataEx, queue-length=1}, provided-interface=TI_DemExt_GetEventFreezeFrameDataEx
      pp_CS_DemExt_GetEventUdsStatus: server-com-spec{operation=DemExt_GetEventUdsStatus, queue-length=1}, provided-interface=TI_DemExt_GetEventUdsStatus
      pp_CS_DemExt_GetFaultDetectionCounter: server-com-spec{operation=DemExt_GetFaultDetectionCounter, queue-length=1}, provided-interface=TI_DemExt_GetFaultDetectionCounter
      pp_CS_DemExt_GetNumberOfEventMemoryEntries: server-com-spec{operation=DemExt_GetNumberOfEventMemoryEntries, queue-length=1}, provided-interface=TI_DemExt_GetNumberOfEventMemoryEntries
      pp_CS_DemExt_GetOperationCycleState: server-com-spec{operation=DemExt_GetOperationCycleState, queue-length=1}, provided-interface=TI_DemExt_GetOperationCycleState
      pp_CS_DemExt_SelectDTC: server-com-spec{operation=DemExt_SelectDTC, queue-length=1}, provided-interface=TI_DemExt_SelectDTC
      pp_CS_DemExt_SetEnableCondition: server-com-spec{operation=DemExt_SetEnableCondition, queue-length=1}, provided-interface=TI_DemExt_SetEnableCondition
      pp_CS_DemExt_SetEventAvailable: server-com-spec{operation=DemExt_SetEventAvailable, queue-length=1}, provided-interface=TI_DemExt_SetEventAvailable
      pp_CS_DemExt_SetEventStatus: server-com-spec{operation=DemExt_SetEventStatus, queue-length=1}, provided-interface=TI_DemExt_SetEventStatus
      pp_CS_DemExt_SetOperationCycleState: server-com-spec{operation=DemExt_SetOperationCycleState, queue-length=1}, provided-interface=TI_DemExt_SetOperationCycleState
      pp_CS_DemExt_SetStorageCondition: server-com-spec{operation=DemExt_SetStorageCondition, queue-length=1}, provided-interface=TI_DemExt_SetStorageCondition
    behavior IB_DemExt
      17 x operation invoked event:
        OIE_pp_CS_DemExt_ClearDTC_DemExt_ClearDTCTrigByDemExt_ClearDTC: start-on-event=DemExt_ClearDTC, operation=pp_CS_DemExt_ClearDTC.DemExt_ClearDTC
        OIE_pp_CS_DemExt_GetDTCOfEvent_DemExt_GetDTCOfEventTrigByDemExt_GetDTCOfEvent: start-on-event=DemExt_GetDTCOfEvent, operation=pp_CS_DemExt_GetDTCOfEvent.DemExt_GetDTCOfEvent
        OIE_pp_CS_DemExt_GetDTCSelectionResult_DemExt_GetDTCSelectionResultTrigByDemExt_GetDTCSelectionResult: start-on-event=DemExt_GetDTCSelectionResult, operation=pp_CS_DemExt_GetDTCSelectionResult.DemExt_GetDTCSelectionResult
        OperationInvokeEvent_110: start-on-event=DemExt_GetDTCSelectionResultForClearDTC, operation=pp_CS_DemExt_GetDTCSelectionResultForClearDTC.DemExt_GetDTCSelectionResultForClearDTC
        OIE_pp_CS_DemExt_GetDebouncingOfEvent_DemExt_GetDebouncingOfEventTrigByDemExt_GetDebouncingOfEvent: start-on-event=DemExt_GetDebouncingOfEvent, operation=pp_CS_DemExt_GetDebouncingOfEvent.DemExt_GetDebouncingOfEvent
        OIE_pp_CS_DemExt_GetEventExtendedDataRecordEx_DemExt_GetEventExtendedDataRecordExTrigByDemExt_GetEventExtendedDataRecordEx: start-on-event=DemExt_GetEventExtendedDataRecordEx, operation=pp_CS_DemExt_GetEventExtendedDataRecordEx.DemExt_GetEventExtendedDataRecordEx
        OIE_pp_CS_DemExt_GetEventFreezeFrameDataEx_DemExt_GetEventFreezeFrameDataExTrigByDemExt_GetEventFreezeFrameDataEx: start-on-event=DemExt_GetEventFreezeFrameDataEx, operation=pp_CS_DemExt_GetEventFreezeFrameDataEx.DemExt_GetEventFreezeFrameDataEx
        OIE_pp_CS_DemExt_GetEventUdsStatus_DemExt_GetEventUdsStatusTrigByDemExt_GetEventUdsStatus: start-on-event=DemExt_GetEventUdsStatus, operation=pp_CS_DemExt_GetEventUdsStatus.DemExt_GetEventUdsStatus
        OIE_pp_CS_DemExt_GetFaultDetectionCounter_DemExt_GetFaultDetectionCounterTrigByDemExt_GetFaultDetectionCounter: start-on-event=DemExt_GetFaultDetectionCounter, operation=pp_CS_DemExt_GetFaultDetectionCounter.DemExt_GetFaultDetectionCounter
        OIE_pp_CS_DemExt_GetNumberOfEventMemoryEntries_DemExt_GetNumberOfEventMemoryEntriesTrigByDemExt_GetNumberOfEventMemoryEntries: start-on-event=DemExt_GetNumberOfEventMemoryEntries, operation=pp_CS_DemExt_GetNumberOfEventMemoryEntries.DemExt_GetNumberOfEventMemoryEntries
        OIE_pp_CS_DemExt_GetOperationCycleState_DemExt_GetOperationCycleStateTrigByDemExt_GetOperationCycleState: start-on-event=DemExt_GetOperationCycleState, operation=pp_CS_DemExt_GetOperationCycleState.DemExt_GetOperationCycleState
        OIE_pp_CS_DemExt_SelectDTC_DemExt_SelectDTCTrigByDemExt_SelectDTC: start-on-event=DemExt_SelectDTC, operation=pp_CS_DemExt_SelectDTC.DemExt_SelectDTC
        OIE_pp_CS_DemExt_SetEnableCondition_DemExt_SetEnableConditionTrigByDemExt_SetEnableCondition: start-on-event=DemExt_SetEnableCondition, operation=pp_CS_DemExt_SetEnableCondition.DemExt_SetEnableCondition
        OIE_pp_CS_DemExt_SetEventAvailable_DemExt_SetEventAvailableTrigByDemExt_SetEventAvailable: start-on-event=DemExt_SetEventAvailable, operation=pp_CS_DemExt_SetEventAvailable.DemExt_SetEventAvailable
        OIE_pp_CS_DemExt_SetEventStatus_DemExt_SetEventStatusTrigByDemExt_SetEventStatus: start-on-event=DemExt_SetEventStatus, operation=pp_CS_DemExt_SetEventStatus.DemExt_SetEventStatus
        OIE_pp_CS_DemExt_SetOperationCycleState_DemExt_SetOperationCycleStateTrigByDemExt_SetOperationCycleState: start-on-event=DemExt_SetOperationCycleState, operation=pp_CS_DemExt_SetOperationCycleState.DemExt_SetOperationCycleState
        OIE_pp_CS_DemExt_SetStorageCondition_DemExt_SetStorageConditionTrigByDemExt_SetStorageCondition: start-on-event=DemExt_SetStorageCondition, operation=pp_CS_DemExt_SetStorageCondition.DemExt_SetStorageCondition
      timing event TEDemExt_MainFunction: start-on-event=DemExt_MainFunction, period=0.01
      port-api-options:
        enable-take-address=false, indirect-api=false, port=pp_CS_DemExt_ClearDTC
        enable-take-address=false, indirect-api=false, port=pp_CS_DemExt_GetDTCOfEvent
        enable-take-address=false, indirect-api=false, port=pp_CS_DemExt_GetDTCSelectionResult
        enable-take-address=false, indirect-api=false, port=pp_CS_DemExt_GetDTCSelectionResultForClearDTC
        enable-take-address=false, indirect-api=false, port=pp_CS_DemExt_GetDebouncingOfEvent
        enable-take-address=false, indirect-api=false, port=pp_CS_DemExt_GetEventExtendedDataRecordEx
        enable-take-address=false, indirect-api=false, port=pp_CS_DemExt_GetEventFreezeFrameDataEx
        enable-take-address=false, indirect-api=false, port=pp_CS_DemExt_GetEventUdsStatus
        enable-take-address=false, indirect-api=false, port=pp_CS_DemExt_GetFaultDetectionCounter
        enable-take-address=false, indirect-api=false, port=pp_CS_DemExt_GetNumberOfEventMemoryEntries
        enable-take-address=false, indirect-api=false, port=pp_CS_DemExt_GetOperationCycleState
        enable-take-address=false, indirect-api=false, port=pp_CS_DemExt_SelectDTC
        enable-take-address=false, indirect-api=false, port=pp_CS_DemExt_SetEnableCondition
        enable-take-address=false, indirect-api=false, port=pp_CS_DemExt_SetEventAvailable
        enable-take-address=false, indirect-api=false, port=pp_CS_DemExt_SetEventStatus
        enable-take-address=false, indirect-api=false, port=pp_CS_DemExt_SetOperationCycleState
        enable-take-address=false, indirect-api=false, port=pp_CS_DemExt_SetStorageCondition
      18 x runnable, all with can-be-invoked-concurrently=true:
        DemExt_ClearDTC
        DemExt_GetDTCOfEvent
        DemExt_GetDTCSelectionResult
        DemExt_GetDTCSelectionResultForClearDTC
        DemExt_GetDebouncingOfEvent
        DemExt_GetEventExtendedDataRecordEx
        DemExt_GetEventFreezeFrameDataEx
        DemExt_GetEventUdsStatus
        DemExt_GetFaultDetectionCounter
        DemExt_GetNumberOfEventMemoryEntries
        DemExt_GetOperationCycleState
        DemExt_SelectDTC
        DemExt_SetEnableCondition
        DemExt_SetEventAvailable
        DemExt_SetEventStatus
        DemExt_SetOperationCycleState
        DemExt_SetStorageCondition
        DemExt_MainFunction
  swc implementation IMPL_DemExt: programming-language=C, behavior=IB_DemExt
    code-descriptors:
      code CodeDescriptor
  application sw component type CDisplayCdd
    5 x provide port:
      ppCS_DisplayCdd_Cbk: server-com-spec{operation=I2cSeqEndCallback, queue-length=1}, provided-interface=TI_Display_I2cSeqCallback
      ppCS_DisplayCdd_GammaSet: provided-com-specs=[{operation=GetGammaCorrectionStatus, queue-length=1}, {operation=SetGammaCorrection, queue-length=1}], provided-interface=TI_Display_GammaCorrection
      ppSRDisplaySetPower: nonqueued-sender-com-spec{data-element=TI_DisplaySetPower/DisplaySetPowerData, init-value=constant-reference=CDisplayCddDisplaySetPowerDataValue0}, provided-interface=TI_DisplaySetPower
      pp_CS_DisplayCdd_Status: provided-com-specs=[{operation=TI_Display_Status/GetStatus, queue-length=1}, {operation=SetState, queue-length=1}], provided-interface=TI_Display_Status
      pp_CmpLibCmd_CDisplayCdd: server-com-spec{operation=Impl_OnCommand, queue-length=1}, provided-interface=if_CS_ModeOnCommand
    4 x require port:
      rpIoHwAb_SetDout: required-interface=TI_IOHWAB_SetDout
      rpSRDisplayCurrentState: nonqueued-receiver-com-spec{data-element=DisplayCurrentStateData, init-value=constant-reference=CDisplayCddDisplayCurrentStateDataValue0}, required-interface=DisplayCurrentState
      rp_CS_Backlight_Notify: required-interface=TI_Backlight_NotifyDispaly
      rp_CS_Backlight_Status: required-interface=TI_Backlight_Status
    behavior IB_CDisplayCdd
      operation invoked event OIE_ppCS_DisplayCdd_GammaSet_CDisplayCdd_GetGammaCorrectionStatusTrigByGetGammaCorrectionStatus: start-on-event=CDisplayCdd_GetGammaCorrectionStatus, operation=ppCS_DisplayCdd_GammaSet.GetGammaCorrectionStatus
      operation invoked event OIE_pp_CS_DisplayCdd_Status_CDisplayCdd_GetStatusTrigByGetStatus: start-on-event=CDisplayCdd_GetStatus, operation=pp_CS_DisplayCdd_Status.GetStatus
      operation invoked event OIE_ppCS_DisplayCdd_Cbk_CDisplayCdd_I2cSeqEndCallbackTrigByI2cSeqEndCallback: start-on-event=CDisplayCdd_I2cSeqEndCallback, operation=ppCS_DisplayCdd_Cbk.I2cSeqEndCallback
      timing event TECDisplayCdd_Impl_MainFunction: start-on-event=CDisplayCdd_Impl_MainFunction, period=0.01
      operation invoked event OIE_pp_CmpLibCmd_CDisplayCdd_CDisplayCdd_Impl_OnCommandTrigByImpl_OnCommand: start-on-event=CDisplayCdd_Impl_OnCommand, operation=pp_CmpLibCmd_CDisplayCdd.Impl_OnCommand
      operation invoked event OIE_ppCS_DisplayCdd_GammaSet_CDisplayCdd_SetGammaCorrectionTrigBySetGammaCorrection: start-on-event=CDisplayCdd_SetGammaCorrection, operation=ppCS_DisplayCdd_GammaSet.SetGammaCorrection
      operation invoked event OIE_pp_CS_DisplayCdd_Status_CDisplayCdd_SetStateTrigBySetState: start-on-event=CDisplayCdd_SetState, operation=pp_CS_DisplayCdd_Status.SetState
      port-api-options:
        enable-take-address=false, indirect-api=false, port=ppCS_DisplayCdd_Cbk
        enable-take-address=false, indirect-api=false, port=ppCS_DisplayCdd_GammaSet
        enable-take-address=false, indirect-api=false, port=ppSRDisplaySetPower
        enable-take-address=false, indirect-api=false, port=pp_CS_DisplayCdd_Status
        enable-take-address=false, indirect-api=false, port=pp_CmpLibCmd_CDisplayCdd
        enable-take-address=false, indirect-api=false, port=rpIoHwAb_SetDout
        enable-take-address=false, indirect-api=false, port=rpSRDisplayCurrentState
        enable-take-address=false, indirect-api=false, port=rp_CS_Backlight_Notify
        enable-take-address=false, indirect-api=false, port=rp_CS_Backlight_Status
      7 x runnable, all with can-be-invoked-concurrently=true:
        CDisplayCdd_GetGammaCorrectionStatus
        CDisplayCdd_GetStatus
          data-receive-point-by-arguments:
            access DRA_rpSRDisplayCurrentState_DisplayCurrentStateData: accessed-variable=rpSRDisplayCurrentState.DisplayCurrentStateData
          data-send-points:
            access DWA_ppSRDisplaySetPower_DisplaySetPowerData: accessed-variable=ppSRDisplaySetPower.DisplaySetPowerData
          4 x sync call, all with timeout=0.0:
            OA_rpIoHwAb_SetDout_SetOutputGroup: operation=rpIoHwAb_SetDout.SetOutputGroup
            OA_rpIoHwAb_SetDout_SetOutputPin: operation=rpIoHwAb_SetDout.SetOutputPin
            OA_rp_CS_Backlight_Notify_NotifyDisplayPowerState: operation=rp_CS_Backlight_Notify.NotifyDisplayPowerState
            OA_rp_CS_Backlight_Status_GetStatus: operation=rp_CS_Backlight_Status.GetStatus
        CDisplayCdd_I2cSeqEndCallback
        CDisplayCdd_Impl_MainFunction
          data-receive-point-by-arguments:
            access DRA_rpSRDisplayCurrentState_DisplayCurrentStateData: accessed-variable=rpSRDisplayCurrentState.DisplayCurrentStateData
          data-send-points:
            access DWA_ppSRDisplaySetPower_DisplaySetPowerData: accessed-variable=ppSRDisplaySetPower.DisplaySetPowerData
          4 x sync call, all with timeout=0.0:
            OA_rpIoHwAb_SetDout_SetOutputGroup: operation=rpIoHwAb_SetDout.SetOutputGroup
            OA_rpIoHwAb_SetDout_SetOutputPin: operation=rpIoHwAb_SetDout.SetOutputPin
            OA_rp_CS_Backlight_Notify_NotifyDisplayPowerState: operation=rp_CS_Backlight_Notify.NotifyDisplayPowerState
            OA_rp_CS_Backlight_Status_GetStatus: operation=rp_CS_Backlight_Status.GetStatus
        CDisplayCdd_Impl_OnCommand
          data-receive-point-by-arguments:
            access DRA_rpSRDisplayCurrentState_DisplayCurrentStateData: accessed-variable=rpSRDisplayCurrentState.DisplayCurrentStateData
          data-send-points:
            access DWA_ppSRDisplaySetPower_DisplaySetPowerData: accessed-variable=ppSRDisplaySetPower.DisplaySetPowerData
          4 x sync call, all with timeout=0.0:
            OA_rpIoHwAb_SetDout_SetOutputGroup: operation=rpIoHwAb_SetDout.SetOutputGroup
            OA_rpIoHwAb_SetDout_SetOutputPin: operation=rpIoHwAb_SetDout.SetOutputPin
            OA_rp_CS_Backlight_Notify_NotifyDisplayPowerState: operation=rp_CS_Backlight_Notify.NotifyDisplayPowerState
            OA_rp_CS_Backlight_Status_GetStatus: operation=rp_CS_Backlight_Status.GetStatus
        CDisplayCdd_SetGammaCorrection
        CDisplayCdd_SetState
          data-receive-point-by-arguments:
            access DRA_rpSRDisplayCurrentState_DisplayCurrentStateData: accessed-variable=rpSRDisplayCurrentState.DisplayCurrentStateData
          data-send-points:
            access DWA_ppSRDisplaySetPower_DisplaySetPowerData: accessed-variable=ppSRDisplaySetPower.DisplaySetPowerData
          4 x sync call, all with timeout=0.0:
            OA_rpIoHwAb_SetDout_SetOutputGroup: operation=rpIoHwAb_SetDout.SetOutputGroup
            OA_rpIoHwAb_SetDout_SetOutputPin: operation=rpIoHwAb_SetDout.SetOutputPin
            OA_rp_CS_Backlight_Notify_NotifyDisplayPowerState: operation=rp_CS_Backlight_Notify.NotifyDisplayPowerState
            OA_rp_CS_Backlight_Status_GetStatus: operation=rp_CS_Backlight_Status.GetStatus
  constant specification CDisplayCddDisplaySetPowerDataValue0: value-spec={short-label=CDisplayCddDisplaySetPowerDataValue0, fields=[CDisplayCddDisplaySetPowerDataValue_0:0, CDisplayCddDisplaySetPowerDataValue_1:0]}
  constant specification CDisplayCddDisplayCurrentStateDataValue0: value-spec={short-label=CDisplayCddDisplayCurrentStateDataValue0, fields=[CDisplayCddDisplayCurrentStateDataValue_0:0, CDisplayCddDisplayCurrentStateDataValue_1:0]}
  swc implementation IMPL_CDisplayCdd: programming-language=C, behavior=IB_CDisplayCdd
    code-descriptors:
      code CodeDescriptor
  application sw component type CFltM
    provide port pp_CS_FltM_HandlePostReset: server-com-spec{operation=FltM_HandlePostReset, queue-length=1}, provided-interface=TI_FltM_HandlePostReset
    provide port pp_CS_FltM_ReportFault: server-com-spec{operation=FltM_ReportFault, queue-length=1}, provided-interface=TI_FltM_ReportFault
    provide port pp_CmpLibCmd_CFltM: server-com-spec{operation=Impl_OnCommand, queue-length=1}, provided-interface=if_CS_ModeOnCommand
    7 x require port:
      rp_CS_DemExt_SetEventStatus: required-interface=TI_DemExt_SetEventStatus
      rp_CS_Dlt_SendLogMessage: required-interface=If_CS_Dlt_SendLogMessage
      rp_CS_RstM_ClearResetHistory: required-interface=TI_RstM_ClearResetHistory
      rp_CS_RstM_GetLastResetReason: required-interface=TI_RstM_GetLastResetReason
      rp_CS_RstM_GetResetCount: required-interface=TI_RstM_GetResetCount
      rp_CS_RstM_GetResetHistory: required-interface=TI_RstM_GetResetHistory
      rp_CS_RstM_RequestSwReset: required-interface=TI_RstM_RequestSwReset
    behavior IB_CFltM
      operation invoked event OIE_pp_CS_FltM_HandlePostReset_FltM_HandlePostResetTrigByFltM_HandlePostReset: start-on-event=FltM_HandlePostReset, operation=pp_CS_FltM_HandlePostReset.FltM_HandlePostReset
      operation invoked event OIE_pp_CS_FltM_ReportFault_FltM_ReportFaultTrigByFltM_ReportFault: start-on-event=FltM_ReportFault, operation=pp_CS_FltM_ReportFault.FltM_ReportFault
      operation invoked event OIE_pp_CmpLibCmd_CFltM_CFltM_Impl_OnCommandTrigByImpl_OnCommand: start-on-event=CFltM_Impl_OnCommand, operation=pp_CmpLibCmd_CFltM.Impl_OnCommand
      timing event TECFltM_MainFunction: start-on-event=CFltM_MainFunction, period=0.01
      port-api-options:
        enable-take-address=false, indirect-api=false, port=pp_CS_FltM_HandlePostReset
        enable-take-address=false, indirect-api=false, port=pp_CS_FltM_ReportFault
        enable-take-address=false, indirect-api=false, port=pp_CmpLibCmd_CFltM
        enable-take-address=false, indirect-api=false, port=CFltM/rp_CS_DemExt_SetEventStatus
        enable-take-address=false, indirect-api=false, port=CFltM/rp_CS_Dlt_SendLogMessage
        enable-take-address=false, indirect-api=false, port=rp_CS_RstM_ClearResetHistory
        enable-take-address=false, indirect-api=false, port=rp_CS_RstM_GetLastResetReason
        enable-take-address=false, indirect-api=false, port=rp_CS_RstM_GetResetCount
        enable-take-address=false, indirect-api=false, port=rp_CS_RstM_GetResetHistory
        enable-take-address=false, indirect-api=false, port=rp_CS_RstM_RequestSwReset
      4 x runnable, all with can-be-invoked-concurrently=true:
        FltM_HandlePostReset
          6 x sync call, all with timeout=0.0:
            OA_rp_CS_DemExt_SetEventStatus_DemExt_SetEventStatus: operation=rp_CS_DemExt_SetEventStatus.DemExt_SetEventStatus
            OA_rp_CS_RstM_ClearResetHistory_RstM_GetResetHistory: operation=rp_CS_RstM_ClearResetHistory.RstM_GetResetHistory
            OA_rp_CS_RstM_GetLastResetReason_RstM_GetLastResetReason: operation=rp_CS_RstM_GetLastResetReason.RstM_GetLastResetReason
            OA_rp_CS_RstM_GetResetCount_RstM_GetResetCount: operation=rp_CS_RstM_GetResetCount.RstM_GetResetCount
            OA_rp_CS_RstM_GetResetHistory_RstM_GetResetHistory: operation=rp_CS_RstM_GetResetHistory.RstM_GetResetHistory
            OA_rp_CS_RstM_RequestSwReset_RstM_RequestSwReset: operation=rp_CS_RstM_RequestSwReset.RstM_RequestSwReset
        FltM_ReportFault
          6 x sync call, all with timeout=0.0:
            OA_rp_CS_DemExt_SetEventStatus_DemExt_SetEventStatus: operation=rp_CS_DemExt_SetEventStatus.DemExt_SetEventStatus
            OA_rp_CS_RstM_ClearResetHistory_RstM_GetResetHistory: operation=rp_CS_RstM_ClearResetHistory.RstM_GetResetHistory
            OA_rp_CS_RstM_GetLastResetReason_RstM_GetLastResetReason: operation=rp_CS_RstM_GetLastResetReason.RstM_GetLastResetReason
            OA_rp_CS_RstM_GetResetCount_RstM_GetResetCount: operation=rp_CS_RstM_GetResetCount.RstM_GetResetCount
            OA_rp_CS_RstM_GetResetHistory_RstM_GetResetHistory: operation=rp_CS_RstM_GetResetHistory.RstM_GetResetHistory
            OA_rp_CS_RstM_RequestSwReset_RstM_RequestSwReset: operation=rp_CS_RstM_RequestSwReset.RstM_RequestSwReset
        CFltM_Impl_OnCommand
          6 x sync call, all with timeout=0.0:
            OA_rp_CS_DemExt_SetEventStatus_DemExt_SetEventStatus: operation=rp_CS_DemExt_SetEventStatus.DemExt_SetEventStatus
            OA_rp_CS_RstM_ClearResetHistory_RstM_GetResetHistory: operation=rp_CS_RstM_ClearResetHistory.RstM_GetResetHistory
            OA_rp_CS_RstM_GetLastResetReason_RstM_GetLastResetReason: operation=rp_CS_RstM_GetLastResetReason.RstM_GetLastResetReason
            OA_rp_CS_RstM_GetResetCount_RstM_GetResetCount: operation=rp_CS_RstM_GetResetCount.RstM_GetResetCount
            OA_rp_CS_RstM_GetResetHistory_RstM_GetResetHistory: operation=rp_CS_RstM_GetResetHistory.RstM_GetResetHistory
            OA_rp_CS_RstM_RequestSwReset_RstM_RequestSwReset: operation=rp_CS_RstM_RequestSwReset.RstM_RequestSwReset
        CFltM_MainFunction
          6 x sync call, all with timeout=0.0:
            OA_rp_CS_DemExt_SetEventStatus_DemExt_SetEventStatus: operation=rp_CS_DemExt_SetEventStatus.DemExt_SetEventStatus
            OA_rp_CS_RstM_ClearResetHistory_RstM_GetResetHistory: operation=rp_CS_RstM_ClearResetHistory.RstM_GetResetHistory
            OA_rp_CS_RstM_GetLastResetReason_RstM_GetLastResetReason: operation=rp_CS_RstM_GetLastResetReason.RstM_GetLastResetReason
            OA_rp_CS_RstM_GetResetCount_RstM_GetResetCount: operation=rp_CS_RstM_GetResetCount.RstM_GetResetCount
            OA_rp_CS_RstM_GetResetHistory_RstM_GetResetHistory: operation=rp_CS_RstM_GetResetHistory.RstM_GetResetHistory
            OA_rp_CS_RstM_RequestSwReset_RstM_RequestSwReset: operation=rp_CS_RstM_RequestSwReset.RstM_RequestSwReset
  swc implementation IMPL_CFltM: programming-language=C, behavior=IB_CFltM
    code-descriptors:
      code CodeDescriptor
  application sw component type RstM
    5 x provide port:
      pp_CS_RstM_ClearResetHistory: server-com-spec{operation=TI_RstM_ClearResetHistory/RstM_GetResetHistory, queue-length=1}, provided-interface=TI_RstM_ClearResetHistory
      pp_CS_RstM_GetLastResetReason: server-com-spec{operation=RstM_GetLastResetReason, queue-length=1}, provided-interface=TI_RstM_GetLastResetReason
      pp_CS_RstM_GetResetCount: server-com-spec{operation=RstM_GetResetCount, queue-length=1}, provided-interface=TI_RstM_GetResetCount
      pp_CS_RstM_GetResetHistory: server-com-spec{operation=TI_RstM_GetResetHistory/RstM_GetResetHistory, queue-length=1}, provided-interface=TI_RstM_GetResetHistory
      pp_CS_RstM_RequestSwReset: server-com-spec{operation=RstM_RequestSwReset, queue-length=1}, provided-interface=TI_RstM_RequestSwReset
    require port rp_CS_DltExt_GetResetInfo: required-interface=if_CS_DltExt_GetResetInfo
    require port rp_CS_Dlt_SendLogMessage: required-interface=If_CS_Dlt_SendLogMessage
    behavior IB_RstM
      timing event TERstM_MainFunction: start-on-event=RstM_MainFunction, period=0.01
      4 x operation invoked event:
        OIE_pp_CS_RstM_GetLastResetReason_RstM_GetLastResetReasonTrigByRstM_GetLastResetReason: start-on-event=RstM_GetLastResetReason, operation=pp_CS_RstM_GetLastResetReason.RstM_GetLastResetReason
        OIE_pp_CS_RstM_GetResetCount_RstM_GetResetCountTrigByRstM_GetResetCount: start-on-event=RstM_GetResetCount, operation=pp_CS_RstM_GetResetCount.RstM_GetResetCount
        OIE_pp_CS_RstM_ClearResetHistory_RstM_GetResetHistoryTrigByRstM_GetResetHistory: start-on-event=RstM_GetResetHistory, operation=pp_CS_RstM_ClearResetHistory.RstM_GetResetHistory
        OIE_pp_CS_RstM_RequestSwReset_RstM_RequestSwResetTrigByRstM_RequestSwReset: start-on-event=RstM_RequestSwReset, operation=pp_CS_RstM_RequestSwReset.RstM_RequestSwReset
      port-api-options:
        enable-take-address=false, indirect-api=false, port=pp_CS_RstM_ClearResetHistory
        enable-take-address=false, indirect-api=false, port=pp_CS_RstM_GetLastResetReason
        enable-take-address=false, indirect-api=false, port=pp_CS_RstM_GetResetCount
        enable-take-address=false, indirect-api=false, port=pp_CS_RstM_GetResetHistory
        enable-take-address=false, indirect-api=false, port=pp_CS_RstM_RequestSwReset
        enable-take-address=false, indirect-api=false, port=rp_CS_DltExt_GetResetInfo
        enable-take-address=false, indirect-api=false, port=RstM/rp_CS_Dlt_SendLogMessage
      5 x runnable, all with can-be-invoked-concurrently=true:
        RstM_MainFunction
        RstM_GetLastResetReason
        RstM_GetResetCount
        RstM_GetResetHistory
        RstM_RequestSwReset
  swc implementation IMPL_RstM: programming-language=C, behavior=IB_RstM
    code-descriptors:
      code CodeDescriptor
  application sw component type Dlt
    20 x provide port:
      ppCS_Dlt_DetForwardErrorTrace: server-com-spec{operation=DetForwardErrorTrace, queue-length=1}, provided-interface=If_CS_Dlt_DetForwardErrorTrace
      ppCS_Dlt_GetDefaultLogLevel: server-com-spec{operation=GetDefaultLogLevel, queue-length=1}, provided-interface=If_CS_Dlt_GetDefaultLogLevel
      ppCS_Dlt_GetDefaultTraceStatus: server-com-spec{operation=GetDefaultTraceStatus, queue-length=1}, provided-interface=If_CS_Dlt_GetDefaultTraceStatus
      ppCS_Dlt_GetLogChannelNames: server-com-spec{operation=GetLogChannelNames, queue-length=1}, provided-interface=If_CS_Dlt_GetLogChannelNames
      ppCS_Dlt_GetLogChannelThreshold: server-com-spec{operation=GetLogChannelThreshold, queue-length=1}, provided-interface=If_CS_Dlt_GetLogChannelThreshold
      ppCS_Dlt_GetLogInfo: server-com-spec{operation=GetLogInfo, queue-length=1}, provided-interface=If_CS_Dlt_GetLogInfo
      ppCS_Dlt_GetTraceStatus: server-com-spec{operation=GetTraceStatus, queue-length=1}, provided-interface=If_CS_Dlt_GetTraceStatus
      ppCS_Dlt_InjectCall_SESSION: server-com-spec{operation=InjectCall_SESSION, queue-length=1}, provided-interface=If_CS_Dlt_InjectCall_SESSION
      ppCS_Dlt_RegisterContext: server-com-spec{operation=RegisterContext, queue-length=1}, provided-interface=If_CS_Dlt_RegisterContext
      ppCS_Dlt_ResetToFactoryDefault: server-com-spec{operation=ResetToFactoryDefault, queue-length=1}, provided-interface=If_CS_Dlt_ResetToFactoryDefault
      ppCS_Dlt_SendLogMessage: server-com-spec{operation=If_CS_Dlt_SendLogMessage/SendLogMessage, queue-length=1}, provided-interface=If_CS_Dlt_SendLogMessage
      ppCS_Dlt_SendTraceMessage: server-com-spec{operation=SendTraceMessage, queue-length=1}, provided-interface=If_CS_Dlt_SendTraceMessage
      ppCS_Dlt_SetDefaultLogLevel: server-com-spec{operation=SetDefaultLogLevel, queue-length=1}, provided-interface=If_CS_Dlt_SetDefaultLogLevel
      ppCS_Dlt_SetDefaultTraceStatus: server-com-spec{operation=SetDefaultTraceStatus, queue-length=1}, provided-interface=If_CS_Dlt_SetDefaultTraceStatus
      ppCS_Dlt_SetLogChannelAssignment: server-com-spec{operation=SetLogChannelAssignment, queue-length=1}, provided-interface=If_CS_Dlt_SetLogChannelAssignment
      ppCS_Dlt_SetLogChannelThreshold: server-com-spec{operation=SetLogChannelThreshold, queue-length=1}, provided-interface=If_CS_Dlt_SetLogChannelThreshold
      ppCS_Dlt_SetLogLevel: server-com-spec{operation=SetLogLevel, queue-length=1}, provided-interface=If_CS_Dlt_SetLogLevel
      ppCS_Dlt_SetTraceStatus: server-com-spec{operation=SetTraceStatus, queue-length=1}, provided-interface=If_CS_Dlt_SetTraceStatus
      ppCS_Dlt_StoreConfiguration: server-com-spec{operation=StoreConfiguration, queue-length=1}, provided-interface=If_CS_Dlt_StoreConfiguration
      ppCS_Dlt_UnregisterContext: server-com-spec{operation=UnregisterContext, queue-length=1}, provided-interface=If_CS_Dlt_UnregisterContext
    require port rpCS_EcumExt_GetResetReason: required-interface=TI_EcuMExt_GetResetReason
    behavior IB_Dlt
      8 x operation invoked event:
        OIE_ppCS_Dlt_DetForwardErrorTrace_Dlt_DetForwardErrorTraceTrigByDetForwardErrorTrace: start-on-event=Dlt_DetForwardErrorTrace, operation=ppCS_Dlt_DetForwardErrorTrace.DetForwardErrorTrace
        OIE_ppCS_Dlt_GetDefaultLogLevel_Dlt_GetDefaultLogLevelTrigByGetDefaultLogLevel: start-on-event=Dlt_GetDefaultLogLevel, operation=ppCS_Dlt_GetDefaultLogLevel.GetDefaultLogLevel
        OIE_ppCS_Dlt_GetDefaultTraceStatus_Dlt_GetDefaultTraceStatusTrigByGetDefaultTraceStatus: start-on-event=Dlt_GetDefaultTraceStatus, operation=ppCS_Dlt_GetDefaultTraceStatus.GetDefaultTraceStatus
        OIE_ppCS_Dlt_GetLogChannelNames_Dlt_GetLogChannelNamesTrigByGetLogChannelNames: start-on-event=Dlt_GetLogChannelNames, operation=ppCS_Dlt_GetLogChannelNames.GetLogChannelNames
        OIE_ppCS_Dlt_GetLogChannelThreshold_Dlt_GetLogChannelThresholdTrigByGetLogChannelThreshold: start-on-event=Dlt_GetLogChannelThreshold, operation=ppCS_Dlt_GetLogChannelThreshold.GetLogChannelThreshold
        OIE_ppCS_Dlt_GetLogInfo_Dlt_GetLogInfoTrigByGetLogInfo: start-on-event=Dlt_GetLogInfo, operation=ppCS_Dlt_GetLogInfo.GetLogInfo
        OIE_ppCS_Dlt_GetTraceStatus_Dlt_GetTraceStatusTrigByGetTraceStatus: start-on-event=Dlt_GetTraceStatus, operation=ppCS_Dlt_GetTraceStatus.GetTraceStatus
        OIE_ppCS_Dlt_InjectCall_SESSION_Dlt_InjectCall_SESSIONTrigByInjectCall_SESSION: start-on-event=Dlt_InjectCall_SESSION, operation=ppCS_Dlt_InjectCall_SESSION.InjectCall_SESSION
      timing event TEDlt_MainFunction: start-on-event=Dlt_MainFunction, period=0.1
      12 x operation invoked event:
        OIE_ppCS_Dlt_RegisterContext_Dlt_RegisterContextTrigByRegisterContext: start-on-event=Dlt_RegisterContext, operation=ppCS_Dlt_RegisterContext.RegisterContext
        OIE_ppCS_Dlt_ResetToFactoryDefault_Dlt_ResetToFactoryDefaultTrigByResetToFactoryDefault: start-on-event=Dlt_ResetToFactoryDefault, operation=ppCS_Dlt_ResetToFactoryDefault.ResetToFactoryDefault
        OIE_ppCS_Dlt_SendLogMessage_Dlt_SendLogMessageTrigBySendLogMessage: start-on-event=Dlt_SendLogMessage, operation=ppCS_Dlt_SendLogMessage.SendLogMessage
        OIE_ppCS_Dlt_SendTraceMessage_Dlt_SendTraceMessageTrigBySendTraceMessage: start-on-event=Dlt_SendTraceMessage, operation=ppCS_Dlt_SendTraceMessage.SendTraceMessage
        OIE_ppCS_Dlt_SetDefaultLogLevel_Dlt_SetDefaultLogLevelTrigBySetDefaultLogLevel: start-on-event=Dlt_SetDefaultLogLevel, operation=ppCS_Dlt_SetDefaultLogLevel.SetDefaultLogLevel
        OIE_ppCS_Dlt_SetDefaultTraceStatus_Dlt_SetDefaultTraceStatusTrigBySetDefaultTraceStatus: start-on-event=Dlt_SetDefaultTraceStatus, operation=ppCS_Dlt_SetDefaultTraceStatus.SetDefaultTraceStatus
        OIE_ppCS_Dlt_SetLogChannelAssignment_Dlt_SetLogChannelAssignmentTrigBySetLogChannelAssignment: start-on-event=Dlt_SetLogChannelAssignment, operation=ppCS_Dlt_SetLogChannelAssignment.SetLogChannelAssignment
        OIE_ppCS_Dlt_SetLogChannelThreshold_Dlt_SetLogChannelThresholdTrigBySetLogChannelThreshold: start-on-event=Dlt_SetLogChannelThreshold, operation=ppCS_Dlt_SetLogChannelThreshold.SetLogChannelThreshold
        OIE_ppCS_Dlt_SetLogLevel_Dlt_SetLogLevelTrigBySetLogLevel: start-on-event=Dlt_SetLogLevel, operation=ppCS_Dlt_SetLogLevel.SetLogLevel
        OIE_ppCS_Dlt_SetTraceStatus_Dlt_SetTraceStatusTrigBySetTraceStatus: start-on-event=Dlt_SetTraceStatus, operation=ppCS_Dlt_SetTraceStatus.SetTraceStatus
        OIE_ppCS_Dlt_StoreConfiguration_Dlt_StoreConfigurationTrigByStoreConfiguration: start-on-event=Dlt_StoreConfiguration, operation=ppCS_Dlt_StoreConfiguration.StoreConfiguration
        OIE_ppCS_Dlt_UnregisterContext_Dlt_UnregisterContextTrigByUnregisterContext: start-on-event=Dlt_UnregisterContext, operation=ppCS_Dlt_UnregisterContext.UnregisterContext
      port-api-options:
        enable-take-address=false, indirect-api=false, port=ppCS_Dlt_DetForwardErrorTrace
        enable-take-address=false, indirect-api=false, port=ppCS_Dlt_GetDefaultLogLevel
        enable-take-address=false, indirect-api=false, port=ppCS_Dlt_GetDefaultTraceStatus
        enable-take-address=false, indirect-api=false, port=ppCS_Dlt_GetLogChannelNames
        enable-take-address=false, indirect-api=false, port=ppCS_Dlt_GetLogChannelThreshold
        enable-take-address=false, indirect-api=false, port=ppCS_Dlt_GetLogInfo
        enable-take-address=false, indirect-api=false, port=ppCS_Dlt_GetTraceStatus
        enable-take-address=false, indirect-api=false, port=ppCS_Dlt_InjectCall_SESSION
        enable-take-address=false, indirect-api=false, port=ppCS_Dlt_RegisterContext
        enable-take-address=false, indirect-api=false, port=ppCS_Dlt_ResetToFactoryDefault
        enable-take-address=false, indirect-api=false, port=ppCS_Dlt_SendLogMessage
        enable-take-address=false, indirect-api=false, port=ppCS_Dlt_SendTraceMessage
        enable-take-address=false, indirect-api=false, port=ppCS_Dlt_SetDefaultLogLevel
        enable-take-address=false, indirect-api=false, port=ppCS_Dlt_SetDefaultTraceStatus
        enable-take-address=false, indirect-api=false, port=ppCS_Dlt_SetLogChannelAssignment
        enable-take-address=false, indirect-api=false, port=ppCS_Dlt_SetLogChannelThreshold
        enable-take-address=false, indirect-api=false, port=ppCS_Dlt_SetLogLevel
        enable-take-address=false, indirect-api=false, port=ppCS_Dlt_SetTraceStatus
        enable-take-address=false, indirect-api=false, port=ppCS_Dlt_StoreConfiguration
        enable-take-address=false, indirect-api=false, port=ppCS_Dlt_UnregisterContext
        enable-take-address=false, indirect-api=false, port=rpCS_EcumExt_GetResetReason
      21 x runnable, all with can-be-invoked-concurrently=true:
        Dlt_DetForwardErrorTrace
        Dlt_GetDefaultLogLevel
        Dlt_GetDefaultTraceStatus
        Dlt_GetLogChannelNames
        Dlt_GetLogChannelThreshold
        Dlt_GetLogInfo
        Dlt_GetTraceStatus
        Dlt_InjectCall_SESSION
        Dlt_MainFunction
          sync call OA_rpCS_EcumExt_GetResetReason_GetResetReason: operation=rpCS_EcumExt_GetResetReason.GetResetReason, timeout=0.0
        Dlt_RegisterContext
        Dlt_ResetToFactoryDefault
        Dlt_SendLogMessage
        Dlt_SendTraceMessage
        Dlt_SetDefaultLogLevel
        Dlt_SetDefaultTraceStatus
        Dlt_SetLogChannelAssignment
        Dlt_SetLogChannelThreshold
        Dlt_SetLogLevel
        Dlt_SetTraceStatus
        Dlt_StoreConfiguration
        Dlt_UnregisterContext
  swc implementation IMPL_Dlt: programming-language=C, behavior=IB_Dlt
    code-descriptors:
      code CodeDescriptor
